VERSION "created by canmatrix"

NS_ :

BS_:

BU_: HUT T_BOX GW XBOX_D CEM Tester

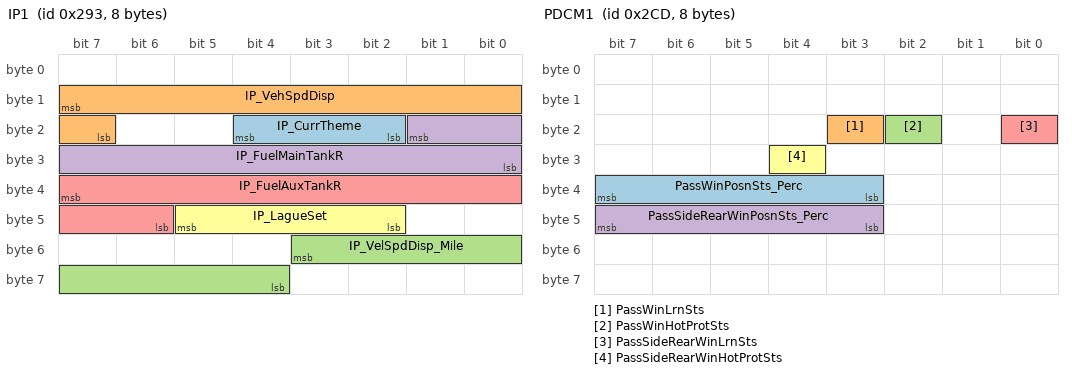
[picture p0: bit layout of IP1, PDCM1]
BO_ 659 IP1: 8 HUT
 SG_ IP_CurrTheme : 20|3@0+ (1,0) [0|7] "" T_BOX
 SG_ IP_VehSpdDisp : 15|9@0+ (0.5,0) [0|255] "kmh" GW
 SG_ IP_VelSpdDisp_Mile : 51|8@0+ (1,0) [0|255] "Mile per hour" GW
 SG_ IP_FuelMainTankR : 17|10@0+ (1,0) [10|1000] "Ohm" GW
 SG_ IP_FuelAuxTankR : 39|10@0+ (1,0) [10|1000] "Ohm" GW
 SG_ IP_LagueSet : 45|4@0+ (1,0) [0|15] "" Vector__XXX

BO_ 639 IP2: 16 HUT
 SG_ CheckSum_IP2 : 7|8@0+ (1,0) [0|255] "" GW
 SG_ IP_DrvSeatBeltWarnLmpFailSts : 51|2@0+ (1,0) [0|3] "" GW
 SG_ IP_PassSeatBeltWarnLmpFailSts : 49|2@0+ (1,0) [0|3] "" GW
 SG_ IP_VehTotDistance : 15|24@0+ (0.1,0) [0|999999.9] "Km" GW,CEM,T_BOX
 SG_ IP_VehTotDistanceValid : 46|1@0+ (1,0) [0|1] "" GW,CEM,T_BOX
 SG_ IP_FuelLvlInfo : 39|8@0+ (1,0) [0|200] "L" GW,T_BOX
 SG_ IP_FuelLvlLowLmpSts : 45|2@0+ (1,0) [0|3] "" T_BOX
 SG_ IP_BattChrgLmpSts : 43|2@0+ (1,0) [0|3] "" Vector__XXX
 SG_ IP_EngOilPressLowLmpSts : 41|2@0+ (1,0) [0|3] "" Vector__XXX
 SG_ IP_ABMWarnLmpFailrSts : 55|2@0+ (1,0) [0|3] "" GW
 SG_ IP_Err : 52|1@0+ (1,0) [0|1] "" GW
 SG_ IP_ACCErr : 47|1@0+ (1,0) [0|1] "" GW
 SG_ IP_VehSpdUnit : 53|1@0+ (1,0) [0|1] "" GW,T_BOX
 SG_ IP_VINcompr : 63|1@0+ (1,0) [0|1] "" GW
 SG_ RollingCounter_IP2 : 59|4@0+ (1,0) [0|15] "" GW
 SG_ FreshnessValue_IP2 : 71|16@0+ (1,0) [0|65535] "" GW,T_BOX
 SG_ MAC_Check_IP2 : 87|48@0+ (1,0) [0|281474976710655] "" GW,T_BOX

BO_ 842 IP3: 16 HUT
 SG_ IP_RemainDistance : 15|12@0+ (1,0) [0|2000] "km" T_BOX
 SG_ IP_InstFuelConsUnit : 19|1@0+ (1,0) [0|1] "" Vector__XXX
 SG_ IP_EBDFailSts : 18|1@0+ (1,0) [0|1] "" Vector__XXX
 SG_ IP_AvgFuelCons : 31|12@0+ (0.01,0) [0|29.99] "L100km" T_BOX
 SG_ IP_InstFuelCons : 35|14@0+ (0.01,0) [0|99.99] "L100km" T_BOX

BO_ 717 PDCM1: 8 GW
 SG_ PassWinPosnSts_Perc : 39|5@0+ (1,0) [0|31] "" HUT,T_BOX
 SG_ PassWinLrnSts : 19|1@0+ (1,0) [0|1] "" HUT,T_BOX
 SG_ PassWinHotProtSts : 18|1@0+ (1,0) [0|1] "" HUT,T_BOX
 SG_ PassSideRearWinPosnSts_Perc : 47|5@0+ (1,0) [0|31] "" HUT,T_BOX
 SG_ PassSideRearWinLrnSts : 16|1@0+ (1,0) [0|1] "" HUT,T_BOX
 SG_ PassSideRearWinHotProtSts : 28|1@0+ (1,0) [0|1] "" HUT,T_BOX

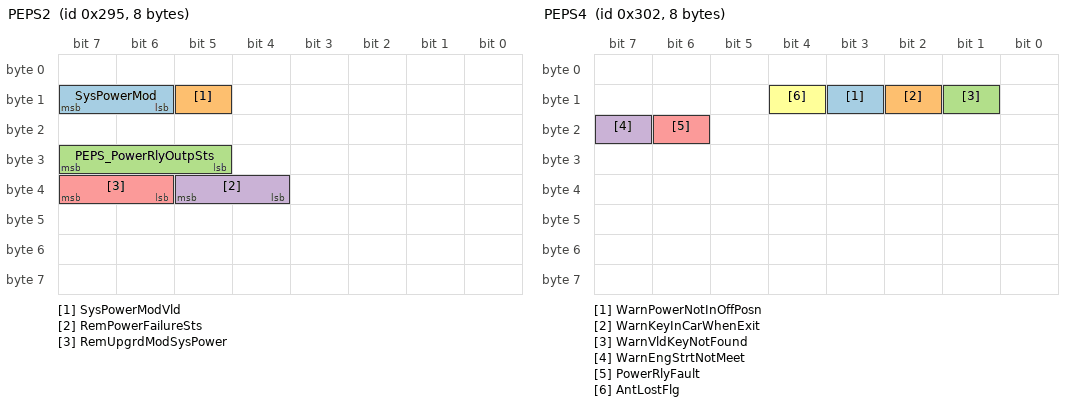
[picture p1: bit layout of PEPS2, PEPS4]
BO_ 661 PEPS2: 8 CEM
 SG_ SysPowerMod : 15|2@0+ (1,0) [0|3] "" HUT,XBOX_D,T_BOX
 SG_ SysPowerModVld : 13|1@0+ (1,0) [0|1] "" HUT,XBOX_D,T_BOX
 SG_ PEPS_PowerRlyOutpSts : 31|3@0+ (1,0) [0|7] "" HUT
 SG_ RemPowerFailureSts : 37|2@0+ (1,0) [0|3] "" HUT,T_BOX
 SG_ RemUpgrdModSysPower : 39|2@0+ (1,0) [0|3] "" HUT,T_BOX

BO_ 770 PEPS4: 8 CEM
 SG_ WarnPowerNotInOffPosn : 11|1@0+ (1,0) [0|1] "" HUT
 SG_ WarnKeyInCarWhenExit : 10|1@0+ (1,0) [0|1] "" HUT
 SG_ WarnVldKeyNotFound : 9|1@0+ (1,0) [0|1] "" HUT
 SG_ WarnEngStrtNotMeet : 23|1@0+ (1,0) [0|1] "" HUT
 SG_ PowerRlyFault : 22|1@0+ (1,0) [0|1] "" HUT
 SG_ AntLostFlg : 12|1@0+ (1,0) [0|1] "" HUT

BO_ 412 R_PBOX1: 16 GW
 SG_ HiPosnBrkLmpFailSts : 15|1@0+ (1,0) [0|1] "" HUT,T_BOX
 SG_ LBrkLmpFailSts : 13|1@0+ (1,0) [0|1] "" HUT,T_BOX
 SG_ RFogLmpFailSts_R_PBox : 29|1@0+ (1,0) [0|1] "" HUT,T_BOX
 SG_ RFogLmpSts_R_PBox : 28|1@0+ (1,0) [0|1] "" HUT,T_BOX
 SG_ ParkLmpSts_R_PBox : 26|1@0+ (1,0) [0|1] "" HUT,T_BOX
 SG_ RBrkLmpFailSts : 12|1@0+ (1,0) [0|1] "" HUT,T_BOX
 SG_ PosnLmpOutpSts_R_PBox : 11|1@0+ (1,0) [0|1] "" HUT,T_BOX
 SG_ RRPosnLmpFailSts : 10|1@0+ (1,0) [0|1] "" HUT,T_BOX
 SG_ RvsLmpFailSts : 9|1@0+ (1,0) [0|1] "" HUT,T_BOX
 SG_ LRPosnLmpFailSts : 8|1@0+ (1,0) [0|1] "" HUT,T_BOX
 SG_ LTurnLmpSts_R_PBox : 31|1@0+ (1,0) [0|1] "" HUT,T_BOX
 SG_ RTurnLmpSts_R_PBox : 30|1@0+ (1,0) [0|1] "" HUT,T_BOX
 SG_ RWinHeatgIconRlyCmd : 21|1@0+ (1,0) [0|1] "" HUT,T_BOX
 SG_ RWinHeatgFailSts : 20|1@0+ (1,0) [0|1] "" HUT
 SG_ LicPlateLmpFailSts : 14|1@0+ (1,0) [0|1] "" HUT,T_BOX
 SG_ RTurnLmpFailSts : 19|2@0+ (1,0) [0|3] "" HUT,T_BOX
 SG_ LTurnLmpFailSts : 17|2@0+ (1,0) [0|3] "" HUT,T_BOX
 SG_ LBrkLmpOutpSts_R_PBox : 38|1@0+ (1,0) [0|1] "" HUT
 SG_ RBrkLmpOutpSts_R_PBox : 24|1@0+ (1,0) [0|1] "" HUT
 SG_ HiPosnBrkLmpOutpSts_R_PBox : 39|1@0+ (1,0) [0|1] "" HUT
 SG_ FreshnessValue_R_PBox1 : 71|16@0+ (1,0) [0|65535] "" HUT,T_BOX
 SG_ MAC_Check_R_PBox1 : 87|48@0+ (1,0) [0|281474976710655] "" HUT,T_BOX

BO_ 367 RSDS_FD1: 64 GW
 SG_ RSDS_IPSoundReq : 81|2@0+ (1,0) [0|3] "" HUT
 SG_ RSDS_ErrSts : 119|1@0+ (1,0) [0|1] "" HUT
 SG_ RSDS_BrkgTrig : 118|1@0+ (1,0) [0|1] "" HUT
 SG_ RSDS_BliSts : 117|1@0+ (1,0) [0|1] "" HUT
 SG_ RSDS_TrailerSts : 116|1@0+ (1,0) [0|1] "" HUT
 SG_ RSDS_LCAResp : 115|1@0+ (1,0) [0|1] "" HUT
 SG_ RSDS_DOWResp : 114|1@0+ (1,0) [0|1] "" HUT
 SG_ RSDS_RCWResp : 113|1@0+ (1,0) [0|1] "" HUT
 SG_ RSDS_RCTAResp : 112|1@0+ (1,0) [0|1] "" HUT
 SG_ RSDS_RCTABrkResp : 127|1@0+ (1,0) [0|1] "" HUT
 SG_ RSDS_RCW_Trigger : 105|2@0+ (1,0) [0|3] "" HUT
 SG_ RSDS_CTA_Actv : 126|1@0+ (1,0) [0|1] "" HUT
 SG_ BSD_LCA_warningReqRight : 95|2@0+ (1,0) [0|3] "" HUT
 SG_ BSD_LCA_warningReqleft : 93|2@0+ (1,0) [0|3] "" HUT
 SG_ DOW_warningReqRight : 91|2@0+ (1,0) [0|3] "" HUT
 SG_ DOW_warningReqleft : 89|2@0+ (1,0) [0|3] "" HUT
 SG_ RCTA_warningReqRight : 125|1@0+ (1,0) [0|1] "" HUT
 SG_ RCTA_warningReqLeft : 124|1@0+ (1,0) [0|1] "" HUT

BO_ 778 RSDS_FD2: 64 GW
 SG_ RCTA_B_TTC : 15|6@0+ (0.1,0) [0|6.3] "s" HUT
 SG_ BSD_LCA_Left_TTC : 9|6@0+ (0.1,0) [0|6.3] "s" HUT
 SG_ BSD_LCA_Right_TTC : 19|6@0+ (0.1,0) [0|6.3] "s" HUT
 SG_ RCW_TTC : 29|6@0+ (0.1,0) [0|6.3] "s" HUT
 SG_ RSDS_LeTgt_01 : 79|1@0+ (1,0) [0|1] "" HUT
 SG_ RSDS_LeTgt_01_dx : 87|10@0+ (0.1,-90) [-90|5] "m" HUT
 SG_ RSDS_LeTgt_01_dy : 78|7@0+ (0.1,0) [0|8] "m" HUT
 SG_ RSDS_LeTgt_02 : 93|1@0+ (1,0) [0|1] "" HUT
 SG_ RSDS_LeTgt_02_dx : 92|10@0+ (0.1,-90) [-90|5] "m" HUT
 SG_ RSDS_LeTgt_02_dy : 98|7@0+ (0.1,0) [0|8] "m" HUT
 SG_ RSDS_RiTgt_01 : 107|1@0+ (1,0) [0|1] "" HUT
 SG_ RSDS_RiTgt_01_dx : 106|10@0+ (0.1,-90) [-90|5] "m" HUT
 SG_ RSDS_RiTgt_01_dy : 143|7@0+ (0.1,-8) [-8|0] "m" HUT
 SG_ RSDS_RiTgt_02 : 136|1@0+ (1,0) [0|1] "" HUT
 SG_ RSDS_RiTgt_02_dx : 151|10@0+ (0.1,-90) [-90|5] "m" HUT
 SG_ RSDS_RiTgt_02_dy : 157|7@0+ (0.1,-8) [-8|0] "m" HUT
 SG_ RSDS_MidTgt_01 : 166|1@0+ (1,0) [0|1] "" HUT
 SG_ RSDS_MidTgt_01_dx : 165|10@0+ (0.1,-90) [-90|5] "m" HUT
 SG_ RSDS_MidTgt_01_dy : 171|7@0+ (0.1,-4) [-4|4] "m" HUT
 SG_ RSDS_MidTgt_02 : 180|1@0+ (1,0) [0|1] "" HUT
 SG_ RSDS_MidTgt_02_dx : 207|10@0+ (0.1,-90) [-90|5] "m" HUT
 SG_ RSDS_MidTgt_02_dy : 213|7@0+ (0.1,-4) [-4|4] "m" HUT

BO_ 51 T_BOX_FD1: 16 T_BOX
 SG_ T_BOX_RemtDoorLockCtrl : 7|3@0+ (1,0) [0|7] "" CEM,HUT
 SG_ T_BOX_AudioMuteReq : 9|2@0+ (1,0) [0|3] "" HUT
 SG_ T_BOX_PM25AirQLvl : 43|4@0+ (1,0) [0|15] "" HUT
 SG_ T_BOX_PM25Dens : 49|10@0+ (1,0) [0|1023] "ugm^3" HUT
 SG_ FreshnessValue_T_BOX_FD1 : 71|16@0+ (1,0) [0|65535] "" GW,HUT
 SG_ MAC_Check_T_BOX_FD1 : 87|48@0+ (1,0) [0|281474976710655] "" GW,HUT

BO_ 1001 T_BOX_FD3: 16 T_BOX
 SG_ T_BOX_SysErrSts : 7|5@0+ (1,0) [0|31] "" GW,HUT
 SG_ T_BOX_SWUpdSts : 18|3@0+ (1,0) [0|7] "" HUT
 SG_ FreshnessValue_T_BOX_FD3 : 71|16@0+ (1,0) [0|65535] "" GW,HUT
 SG_ MAC_Check_T_BOX_FD3 : 87|48@0+ (1,0) [0|281474976710655] "" GW,HUT

BO_ 481 T_BOX_FD4: 16 T_BOX
 SG_ T_BOX_RemtVideoMonrEnaReq_APP : 41|2@0+ (1,0) [0|3] "" HUT

BO_ 752 T_BOX_FD10: 64 T_BOX
 SG_ V2X_FCW : 15|2@0+ (1,0) [0|3] "" HUT
 SG_ V2X_BSW : 13|4@0+ (1,0) [0|15] "" HUT
 SG_ V2X_LCW : 9|2@0+ (1,0) [0|3] "" HUT
 SG_ V2X_EBW : 23|2@0+ (1,0) [0|3] "" HUT
 SG_ V2X_ICW : 21|4@0+ (1,0) [0|15] "" HUT
 SG_ V2X_LTA : 17|2@0+ (1,0) [0|3] "" HUT
 SG_ V2X_IVSW : 31|8@0+ (1,0) [0|255] "" HUT
 SG_ V2X_AVW : 39|3@0+ (1,0) [0|7] "" HUT
 SG_ V2X_EVW : 36|3@0+ (1,0) [0|7] "" HUT
 SG_ V2X_DNPW : 33|2@0+ (1,0) [0|3] "" HUT
 SG_ V2X_HLW : 47|5@0+ (1,0) [0|31] "" HUT
 SG_ V2X_TJW : 42|3@0+ (1,0) [0|7] "" HUT
 SG_ V2X_CLW : 55|6@0+ (1,0) [0|63] "" HUT
 SG_ V2X_RLVW : 49|2@0+ (1,0) [0|3] "" HUT
 SG_ V2X_VRUCW : 63|4@0+ (1,0) [0|15] "" HUT
 SG_ V2X_SLW : 79|6@0+ (1,0) [0|63] "" HUT
 SG_ V2X_GLOSA : 87|8@0+ (1,0) [0|255] "" HUT
 SG_ V2X_SL1_LightTyp : 95|4@0+ (1,0) [0|15] "" HUT
 SG_ V2X_SL1_LightColor : 91|4@0+ (1,0) [0|15] "" HUT
 SG_ V2X_SL1_LightTim : 103|16@0+ (1,0) [0|65535] "s" HUT
 SG_ V2X_SL2_LightTyp : 119|4@0+ (1,0) [0|15] "" HUT
 SG_ V2X_SL2_LightColor : 115|4@0+ (1,0) [0|15] "" HUT
 SG_ V2X_SL2_LightTim : 143|16@0+ (1,0) [0|65535] "s" HUT
 SG_ V2X_SL3_LightTyp : 159|4@0+ (1,0) [0|15] "" HUT
 SG_ V2X_SL3_LightColor : 155|4@0+ (1,0) [0|15] "" HUT
 SG_ V2X_SL3_LightTim : 167|16@0+ (1,0) [0|65535] "s" HUT
 SG_ V2X_SL4_LightTyp : 183|4@0+ (1,0) [0|15] "" HUT
 SG_ V2X_SL4_LightColor : 179|4@0+ (1,0) [0|15] "" HUT
 SG_ V2X_SL5_LightTyp : 191|4@0+ (1,0) [0|15] "" HUT
 SG_ V2X_SL4_LightTim : 207|16@0+ (1,0) [0|65535] "s" HUT
 SG_ V2X_SL5_LightColor : 223|4@0+ (1,0) [0|15] "" HUT
 SG_ V2X_SL5_LightTim : 231|16@0+ (1,0) [0|65535] "s" HUT
 SG_ V2X_SL6_LightTyp : 219|4@0+ (1,0) [0|15] "" HUT
 SG_ V2X_SL6_LightColor : 247|4@0+ (1,0) [0|15] "" HUT
 SG_ V2X_SL6_LightTim : 271|16@0+ (1,0) [0|65535] "s" HUT
 SG_ V2X_SL7_LightTyp : 243|4@0+ (1,0) [0|15] "" HUT
 SG_ V2X_SL7_LightColor : 255|4@0+ (1,0) [0|15] "" HUT
 SG_ V2X_SL7_LightTim : 287|16@0+ (1,0) [0|65535] "s" HUT
 SG_ V2X_SL8_LightTyp : 303|4@0+ (1,0) [0|15] "" HUT
 SG_ V2X_SL8_LightColor : 299|4@0+ (1,0) [0|15] "" HUT
 SG_ V2X_SL8_LightTim : 335|16@0+ (1,0) [0|65535] "s" HUT
 SG_ V2X_SL_of_Veh : 311|4@0+ (1,0) [0|15] "" HUT

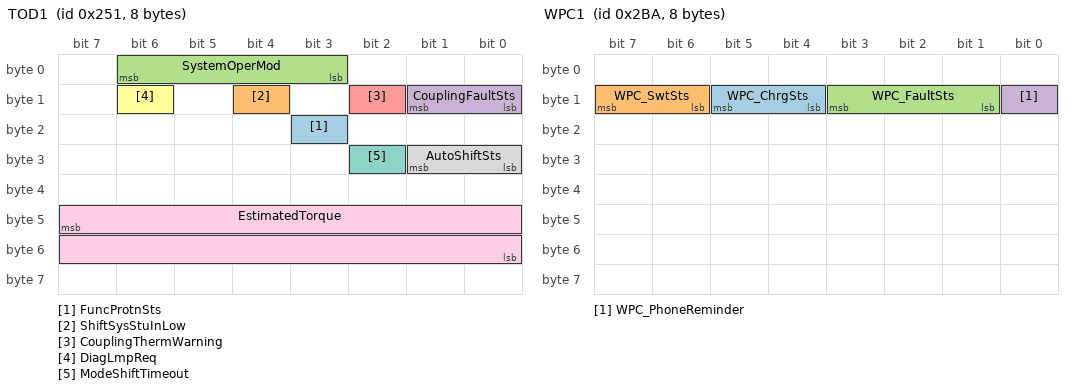
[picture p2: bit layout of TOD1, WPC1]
BO_ 593 TOD1: 8 GW
 SG_ FuncProtnSts : 19|1@0+ (1,0) [0|1] "" HUT
 SG_ ShiftSysStuInLow : 12|1@0+ (1,0) [0|1] "" HUT
 SG_ SystemOperMod : 6|4@0+ (1,0) [0|15] "" HUT,T_BOX
 SG_ CouplingFaultSts : 9|2@0+ (1,0) [0|3] "" HUT
 SG_ CouplingThermWarning : 10|1@0+ (1,0) [0|1] "" HUT,T_BOX
 SG_ DiagLmpReq : 14|1@0+ (1,0) [0|1] "" HUT,T_BOX
 SG_ ModeShiftTimeout : 26|1@0+ (1,0) [0|1] "" HUT
 SG_ AutoShiftSts : 25|2@0+ (1,0) [0|3] "" HUT
 SG_ EstimatedTorque : 47|16@0+ (0.25,0) [0|3000] "Nm" HUT

BO_ 833 TPMS1: 16 GW
 SG_ FLTirePressIndSts : 15|3@0+ (1,0) [0|7] "" HUT,T_BOX
 SG_ FRTirePressIndSts : 12|3@0+ (1,0) [0|7] "" HUT,T_BOX
 SG_ TirePressSysFailrIndcn : 9|2@0+ (1,0) [0|3] "" HUT,T_BOX
 SG_ RLTirePressIndSts : 23|3@0+ (1,0) [0|7] "" HUT,T_BOX
 SG_ RRTirePressIndSts : 20|3@0+ (1,0) [0|7] "" HUT,T_BOX
 SG_ FLTireTempSts : 31|2@0+ (1,0) [0|3] "" HUT,T_BOX
 SG_ FRTireTempSts : 29|2@0+ (1,0) [0|3] "" HUT,T_BOX
 SG_ RLTireTempSts : 27|2@0+ (1,0) [0|3] "" HUT,T_BOX
 SG_ RRTireTempSts : 25|2@0+ (1,0) [0|3] "" HUT,T_BOX
 SG_ FreshnessValue_TPMS1 : 71|16@0+ (1,0) [0|65535] "" HUT,T_BOX
 SG_ MAC_Check_TPMS1 : 87|48@0+ (1,0) [0|281474976710655] "" HUT,T_BOX

BO_ 917 TPMS2: 16 GW
 SG_ FLTirePress : 7|8@0+ (1.3725,0) [0|348.615] "kPa" HUT,T_BOX
 SG_ FLTireTemp : 15|8@0+ (1,-50) [-50|204] "Ã‚Â°C" HUT,T_BOX
 SG_ FRTirePress : 23|8@0+ (1.3725,0) [0|348.615] "kPa" HUT,T_BOX
 SG_ FRTireTemp : 31|8@0+ (1,-50) [-50|204] "Ã‚Â°C" HUT,T_BOX
 SG_ RLTirePress : 39|8@0+ (1.3725,0) [0|348.615] "kPa" HUT,T_BOX
 SG_ RLTireTemp : 47|8@0+ (1,-50) [-50|204] "Ã‚Â°C" HUT,T_BOX
 SG_ RRTirePress : 55|8@0+ (1.3725,0) [0|348.615] "kPa" HUT,T_BOX
 SG_ RRTireTemp : 63|8@0+ (1,-50) [-50|204] "Ã‚Â°C" HUT,T_BOX
 SG_ FreshnessValue_TPMS2 : 71|16@0+ (1,0) [0|65535] "" HUT,T_BOX
 SG_ MAC_Check_TPMS2 : 87|48@0+ (1,0) [0|281474976710655] "" HUT,T_BOX

BO_ 627 Trailer1: 8 GW
 SG_ TrailerSts : 7|1@0+ (1,0) [0|1] "" HUT

BO_ 698 WPC1: 8 GW
 SG_ WPC_ChrgSts : 13|2@0+ (1,0) [0|3] "" HUT
 SG_ WPC_SwtSts : 15|2@0+ (1,0) [0|3] "" HUT
 SG_ WPC_FaultSts : 11|3@0+ (1,0) [0|7] "" HUT
 SG_ WPC_PhoneReminder : 8|1@0+ (1,0) [0|1] "" HUT

BO_ 785 DOCK1: 64 XBOX_D
 SG_ DOCK_ExternalDevice_P : 7|512@0+ (1,0) [0|3.40282366920938E+038] "" HUT

BO_ 479 DOCK2: 64 XBOX_D
 SG_ DOCK_HUT_ExternalDevice_E : 7|512@0+ (1,0) [0|3.40282366920938E+038] "" HUT

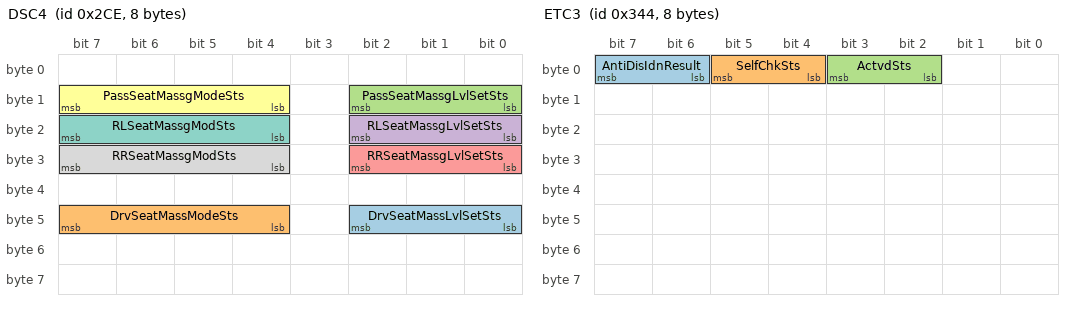
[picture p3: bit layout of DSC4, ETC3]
BO_ 718 DSC4: 8 GW
 SG_ DrvSeatMassLvlSetSts : 42|3@0+ (1,0) [0|7] "" HUT
 SG_ DrvSeatMassModeSts : 47|4@0+ (1,0) [0|15] "" HUT
 SG_ PassSeatMassgLvlSetSts : 10|3@0+ (1,0) [0|7] "" HUT
 SG_ RLSeatMassgLvlSetSts : 18|3@0+ (1,0) [0|7] "" HUT
 SG_ RRSeatMassgLvlSetSts : 26|3@0+ (1,0) [0|7] "" HUT
 SG_ PassSeatMassgModeSts : 15|4@0+ (1,0) [0|15] "" HUT
 SG_ RLSeatMassgModSts : 23|4@0+ (1,0) [0|15] "" HUT
 SG_ RRSeatMassgModSts : 31|4@0+ (1,0) [0|15] "" HUT

BO_ 604 BLE1: 8 GW
 SG_ BLEConnSts : 15|2@0+ (1,0) [0|3] "" HUT
 SG_ BLESecuritySts : 13|2@0+ (1,0) [0|3] "" HUT

BO_ 506 BLE5: 8 GW
 SG_ BLE_BeanID : 7|64@0+ (1,0) [0|1.84467440737096E+019] "" HUT

BO_ 473 GW_OTA: 8 CEM
 SG_ OTA_UpgrdModErrCode : 14|2@0+ (1,0) [0|3] "" HUT

BO_ 721 SCM1: 8 CEM
 SG_ DrvSeatVentnSts : 11|2@0+ (1,0) [0|3] "" HUT
 SG_ PassSeatVentnSts : 9|2@0+ (1,0) [0|3] "" HUT

BO_ 497 ETC2: 8 GW
 SG_ AntiDisIdnRndNumber : 7|64@0+ (1,0) [0|1.84467440737096E+019] "" HUT

BO_ 836 ETC3: 8 GW
 SG_ AntiDisIdnResult : 7|2@0+ (1,0) [0|3] "" HUT
 SG_ SelfChkSts : 5|2@0+ (1,0) [0|3] "" HUT
 SG_ ActvdSts : 3|2@0+ (1,0) [0|3] "" HUT

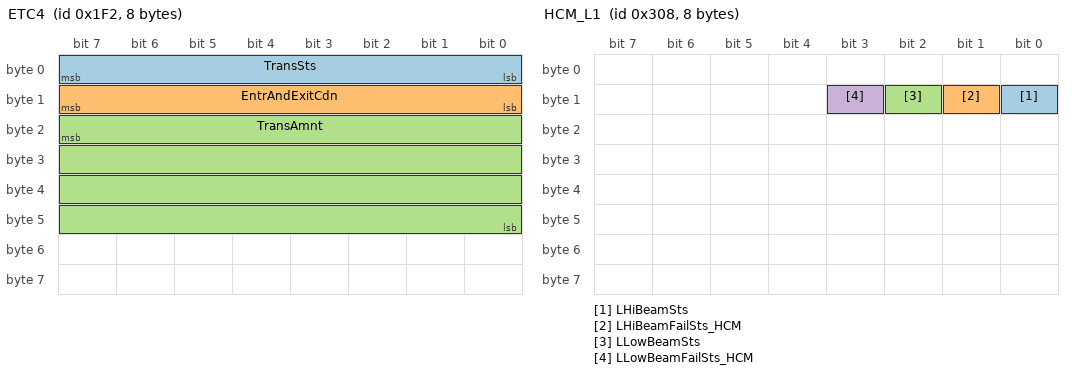
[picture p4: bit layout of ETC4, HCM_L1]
BO_ 498 ETC4: 8 GW
 SG_ TransSts : 7|8@0+ (1,0) [0|255] "" HUT
 SG_ EntrAndExitCdn : 15|8@0+ (1,0) [0|255] "" HUT
 SG_ TransAmnt : 23|32@0+ (1,0) [0|4294967295] "cent" HUT

BO_ 776 HCM_L1: 8 GW
 SG_ LHiBeamSts : 8|1@0+ (1,0) [0|1] "" HUT
 SG_ LHiBeamFailSts_HCM : 9|1@0+ (1,0) [0|1] "" HUT
 SG_ LLowBeamSts : 10|1@0+ (1,0) [0|1] "" HUT
 SG_ LLowBeamFailSts_HCM : 11|1@0+ (1,0) [0|1] "" HUT

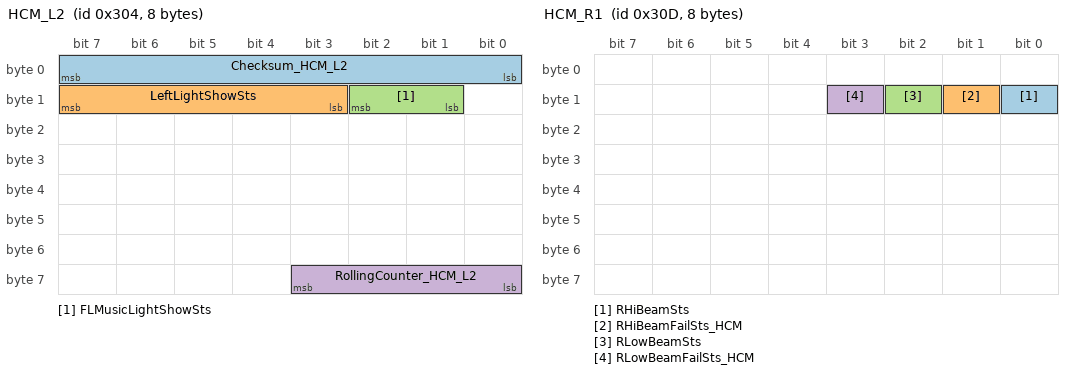
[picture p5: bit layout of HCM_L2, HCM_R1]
BO_ 772 HCM_L2: 8 GW
 SG_ Checksum_HCM_L2 : 7|8@0+ (1,0) [0|255] "" HUT,T_BOX
 SG_ LeftLightShowSts : 15|5@0+ (1,0) [0|31] "" HUT
 SG_ FLMusicLightShowSts : 10|2@0+ (1,0) [0|3] "" HUT,T_BOX
 SG_ RollingCounter_HCM_L2 : 59|4@0+ (1,0) [0|15] "" HUT,T_BOX

BO_ 781 HCM_R1: 8 GW
 SG_ RHiBeamSts : 8|1@0+ (1,0) [0|1] "" HUT
 SG_ RHiBeamFailSts_HCM : 9|1@0+ (1,0) [0|1] "" HUT
 SG_ RLowBeamSts : 10|1@0+ (1,0) [0|1] "" HUT
 SG_ RLowBeamFailSts_HCM : 11|1@0+ (1,0) [0|1] "" HUT

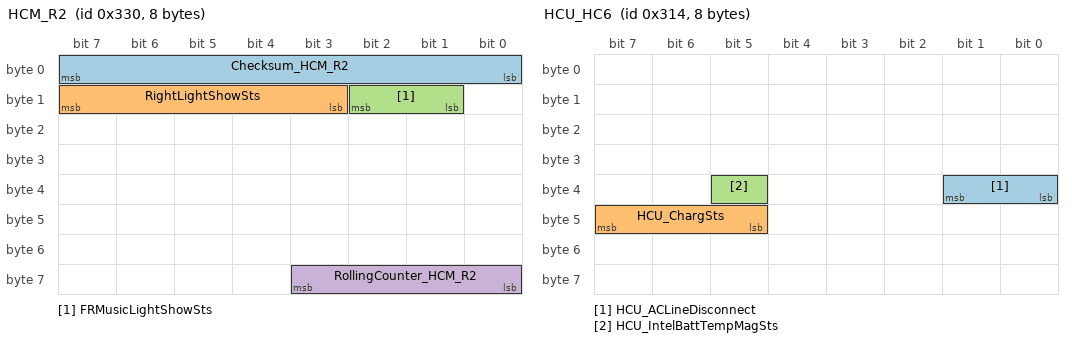
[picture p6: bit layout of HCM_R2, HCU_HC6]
BO_ 816 HCM_R2: 8 GW
 SG_ Checksum_HCM_R2 : 7|8@0+ (1,0) [0|255] "" HUT,T_BOX
 SG_ RightLightShowSts : 15|5@0+ (1,0) [0|31] "" HUT
 SG_ FRMusicLightShowSts : 10|2@0+ (1,0) [0|3] "" HUT,T_BOX
 SG_ RollingCounter_HCM_R2 : 59|4@0+ (1,0) [0|15] "" HUT,T_BOX

BO_ 647 ALS1: 16 GW
 SG_ CheckSum_HC1 : 7|8@0+ (1,0) [0|255] "" HUT
 SG_ ALS_FailSts : 8|1@0+ (1,0) [0|1] "" HUT
 SG_ RollingCounter_HC1 : 59|4@0+ (1,0) [0|15] "" HUT

BO_ 818 RFCM_L1: 8 GW
 SG_ RFLLightShowSts : 23|5@0+ (1,0) [0|31] "" HUT,T_BOX

BO_ 819 RFCM_R1: 8 GW
 SG_ RFRLightShowSts : 23|5@0+ (1,0) [0|31] "" HUT,T_BOX

BO_ 1888 DiagFuncReq: 8 Tester
 SG_ DiagFuncReq : 7|64@0+ (1,0) [0|1.84467440737096E+019] "" GW,CEM,T_BOX,XBOX_D,HUT

BO_ 1889 GW_Phy_Req: 8 Tester
 SG_ GW_Phy_Req : 7|64@0+ (1,0) [0|1.84467440737096E+019] "" GW

BO_ 1918 T_Box_Phy_Req: 8 Tester
 SG_ T_Box_Phy_Req : 7|64@0+ (1,0) [0|1.84467440737096E+019] "" GW,T_BOX

BO_ 1843 XBOX_D_Phy_Req: 8 Tester
 SG_ XBOX_D_Phy_Req : 7|64@0+ (1,0) [0|1.84467440737096E+019] "" GW,XBOX_D

BO_ 1907 HUT_Phy_Req: 8 Tester
 SG_ HUT_Phy_Req : 7|64@0+ (1,0) [0|1.84467440737096E+019] "" GW,HUT

BO_ 1953 GW_Phy_Resp: 8 GW
 SG_ GW_Phy_Resp : 7|64@0+ (1,0) [0|1.84467440737096E+019] "" Tester

BO_ 1982 T_Box_Phy_Resp: 8 T_BOX
 SG_ T_Box_Phy_Resp : 7|64@0+ (1,0) [0|1.84467440737096E+019] "" GW,Tester

BO_ 1844 XBOX_D_Phy_Resp: 8 XBOX_D
 SG_ XBOX_D_Phy_Resp : 7|64@0+ (1,0) [0|1.84467440737096E+019] "" GW,Tester

BO_ 1971 HUT_Phy_Resp: 8 HUT
 SG_ HUT_Phy_Resp : 7|64@0+ (1,0) [0|1.84467440737096E+019] "" GW,Tester

BO_ 1290 T_Box_NM: 8 T_BOX
 SG_ Destination_T_Box_NM : 7|8@0+ (1,0) [0|255] "" CEM,XBOX_D,HUT
 SG_ OpCode_T_Box_NM : 15|8@0+ (1,0) [0|255] "" CEM,XBOX_D,HUT

BO_ 1289 HUT_NM: 8 HUT
 SG_ Destination_HUT_NM : 7|8@0+ (1,0) [0|255] "" CEM,T_BOX,XBOX_D
 SG_ OpCode_HUT_NM : 15|8@0+ (1,0) [0|255] "" CEM,T_BOX,XBOX_D

BO_ 1334 XBOX_D_NM: 8 XBOX_D
 SG_ Destination_XBOX_D_NM : 7|8@0+ (1,0) [0|255] "" CEM,T_BOX,HUT
 SG_ OpCode_XBOX_D_NM : 15|8@0+ (1,0) [0|255] "" CEM,T_BOX,HUT

BO_ 1281 CEM_NM: 8 CEM
 SG_ Destination_CEM_NM : 7|8@0+ (1,0) [0|255] "" T_BOX,XBOX_D,HUT
 SG_ OpCode_CEM_NM : 15|8@0+ (1,0) [0|255] "" T_BOX,XBOX_D,HUT

BO_ 1122 HUT_Sync_Req: 16 HUT
 SG_ SyncRequestMessageId : 7|8@0+ (1,0) [0|0] "" GW
 SG_ SyncRequstReseverData : 15|56@0+ (1,0) [0|0] "" GW

BO_ 1121 GW_Sync_Req: 16 GW
 SG_ ResetCount : 31|16@0+ (1,0) [0|0] "" HUT
 SG_ CMACMessageInfo : 47|88@0+ (1,0) [0|0] "" HUT
 SG_ TripCount : 7|24@0+ (1,0) [0|0] "" HUT

BO_ 483 BMS_FD14: 8 GW
 SG_ BMS_ChrgTimResp : 9|1@0+ (1,0) [0|1] "" HUT

BO_ 850 BMS19: 8 GW
 SG_ BMS_IntelEngIdlChrgnSts : 45|2@0+ (1,0) [0|3] "" HUT
 SG_ BMS_BattKeepTempSts : 18|1@0+ (1,0) [0|1] "" HUT

BO_ 959 BMS22: 8 GW
 SG_ BMS_ChrgDurationTime : 47|10@0+ (1,0) [0|1022] "minute" HUT,T_BOX

BO_ 1009 BMS30: 8 GW
 SG_ BMS_SOCLowWarn : 31|1@0+ (1,0) [0|1] "" HUT

BO_ 942 BMS66: 8 GW
 SG_ BMS_SocJumpWarn_RM : 7|1@0+ (1,0) [0|1] "" HUT,T_BOX
 SG_ BMS_PackOverChrgWarn_RM : 6|1@0+ (1,0) [0|1] "" HUT,T_BOX
 SG_ BMS_ChrgSts_RM : 5|3@0+ (1,0) [0|7] "" HUT,T_BOX
 SG_ BMS_IsolationRValue_RM : 15|16@0+ (1,0) [0|60000] "Kohm" HUT,T_BOX
 SG_ BMS_PackCurr_RM : 31|15@0+ (0.1,-1000) [-1000|1000] "A" HUT,T_BOX
 SG_ BMS_SocOverWarn_RM : 32|1@0+ (1,0) [0|1] "" HUT,T_BOX
 SG_ BMS_BattOverTempRank_RM : 47|1@0+ (1,0) [0|1] "" HUT,T_BOX
 SG_ BMS_BattOverVoltRank_RM : 46|1@0+ (1,0) [0|1] "" HUT,T_BOX
 SG_ BMS_BattSOCLowRank_RM : 45|1@0+ (1,0) [0|1] "" HUT,T_BOX
 SG_ BMS_VCUIsolateErr_RM : 44|1@0+ (1,0) [0|1] "" HUT,T_BOX
 SG_ BMS_BattUnderVoltRank_RM : 43|1@0+ (1,0) [0|1] "" HUT,T_BOX
 SG_ BMS_CellDeltaVoltRank_RM : 42|1@0+ (1,0) [0|1] "" HUT,T_BOX
 SG_ BMS_CellOverVoltRank_RM : 41|1@0+ (1,0) [0|1] "" HUT,T_BOX
 SG_ BMS_CellUnderVoltRank_RM : 40|1@0+ (1,0) [0|1] "" HUT,T_BOX
 SG_ BMS_DeltaTempRank_RM : 55|1@0+ (1,0) [0|1] "" HUT,T_BOX
 SG_ BMS_PackMismatchWarn_RM : 54|1@0+ (1,0) [0|1] "" HUT,T_BOX
 SG_ BMS_PackVolt_RM : 53|14@0+ (0.1,0) [0|1000] "V" HUT,T_BOX

BO_ 645 BMS8: 8 GW
 SG_ BMS_BattHeatRunaway : 61|2@0+ (1,0) [0|3] "" HUT,T_BOX
 SG_ BMS_DisSOC1 : 31|8@0+ (1,0) [0|100] "%" HUT,T_BOX

BO_ 142 ECM_PT5: 8 GW
 SG_ EngTrqCrankshaftLvl : 27|12@0+ (0.25,-224) [-224|799.75] "Nm" HUT
 SG_ EngTrqCrankshaftLvlValid : 61|1@0+ (1,0) [0|1] "" HUT

BO_ 279 ECM_PT7: 8 GW
 SG_ EngState_PHEV : 31|3@0+ (1,0) [0|7] "" HUT
 SG_ CruiseCtrlSts_PHEV : 55|4@0+ (1,0) [0|15] "" HUT

BO_ 96 HCU_FD1: 64 GW
 SG_ HCU_AccelPedalPosn_Diag : 79|8@0+ (0.3937,0) [0|100.395] "%" HUT
 SG_ HCU_AccelPedalPosn_DiagValid : 85|1@0+ (1,0) [0|1] "" HUT
 SG_ HCU_PowertrainSts_0x60 : 303|5@0+ (1,0) [0|31] "" HUT,XBOX_D
 SG_ HCU_RaceLaunchSts_0x60 : 319|3@0+ (1,0) [0|7] "" HUT
 SG_ HCU_RaceLaunchAvail_0x60 : 287|2@0+ (1,0) [0|3] "" HUT
 SG_ HCU_AccelPedalPosn : 103|8@0+ (0.3937,0) [0|100.395] "%" HUT
 SG_ HCU_AccelPedalPosnValid : 127|1@0+ (1,0) [0|1] "" HUT

BO_ 616 HCU_HC3: 8 GW
 SG_ HCU_BattLowTempWarn : 51|2@0+ (1,0) [0|3] "" HUT
 SG_ HCU_BattLowTempHeatSts : 49|2@0+ (1,0) [0|3] "" HUT

BO_ 788 HCU_HC6: 8 GW
 SG_ HCU_ACLineDisconnect : 33|2@0+ (1,0) [0|3] "" HUT,T_BOX
 SG_ HCU_ChargSts : 47|3@0+ (1,0) [0|7] "" HUT,T_BOX
 SG_ HCU_IntelBattTempMagSts : 37|1@0+ (1,0) [0|1] "" HUT

BO_ 482 HCU_HC8: 8 GW
 SG_ HCU_TotalScore : 23|3@0+ (1,0) [0|5] "" HUT

BO_ 249 HCU_HP8: 8 GW
 SG_ HCU_TrqLimMax_Norm : 16|9@0+ (2,0) [0|800] "Nm" HUT

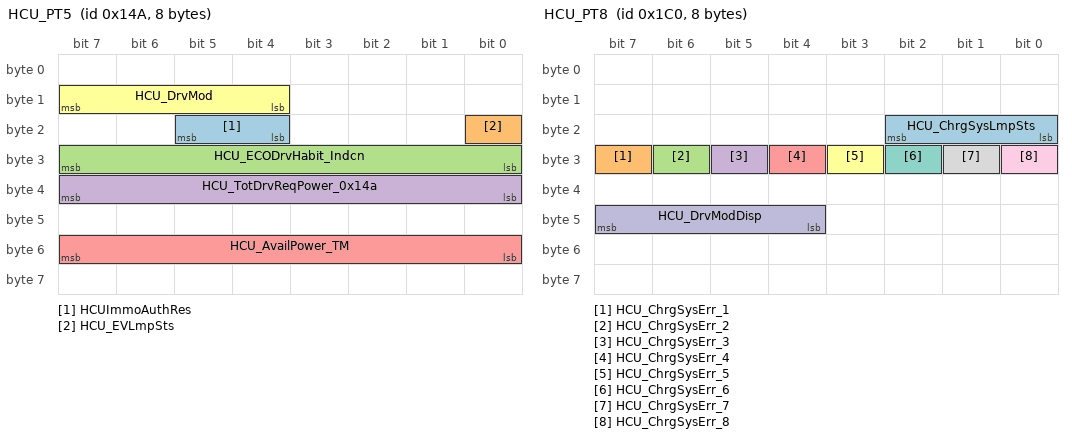
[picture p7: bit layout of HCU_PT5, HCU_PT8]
BO_ 330 HCU_PT5: 8 GW
 SG_ HCUImmoAuthRes : 21|2@0+ (1,0) [0|3] "" HUT
 SG_ HCU_EVLmpSts : 16|1@0+ (1,0) [0|1] "" HUT
 SG_ HCU_ECODrvHabit_Indcn : 31|8@0+ (0.1,-10) [-10|10] "" HUT
 SG_ HCU_TotDrvReqPower_0x14a : 39|8@0+ (1,-100) [-100|100] "%" HUT
 SG_ HCU_AvailPower_TM : 55|8@0+ (0.5,0) [0|100] "%" HUT
 SG_ HCU_DrvMod : 15|4@0+ (1,0) [0|15] "" HUT

BO_ 282 HCU_HP6: 8 GW
 SG_ HCU_HybMod : 28|2@0+ (1,0) [0|3] "" HUT
 SG_ HCU_HybFctnMod : 26|2@0+ (1,0) [0|3] "" HUT

BO_ 448 HCU_PT8: 8 GW
 SG_ HCU_ChrgSysLmpSts : 18|3@0+ (1,0) [0|7] "" HUT
 SG_ HCU_ChrgSysErr_1 : 31|1@0+ (1,0) [0|1] "" HUT
 SG_ HCU_ChrgSysErr_2 : 30|1@0+ (1,0) [0|1] "" HUT
 SG_ HCU_ChrgSysErr_3 : 29|1@0+ (1,0) [0|1] "" HUT
 SG_ HCU_ChrgSysErr_4 : 28|1@0+ (1,0) [0|1] "" HUT
 SG_ HCU_ChrgSysErr_5 : 27|1@0+ (1,0) [0|1] "" HUT
 SG_ HCU_ChrgSysErr_6 : 26|1@0+ (1,0) [0|1] "" HUT
 SG_ HCU_ChrgSysErr_7 : 25|1@0+ (1,0) [0|1] "" HUT
 SG_ HCU_ChrgSysErr_8 : 24|1@0+ (1,0) [0|1] "" HUT
 SG_ HCU_DrvModDisp : 47|4@0+ (1,0) [0|15] "" HUT

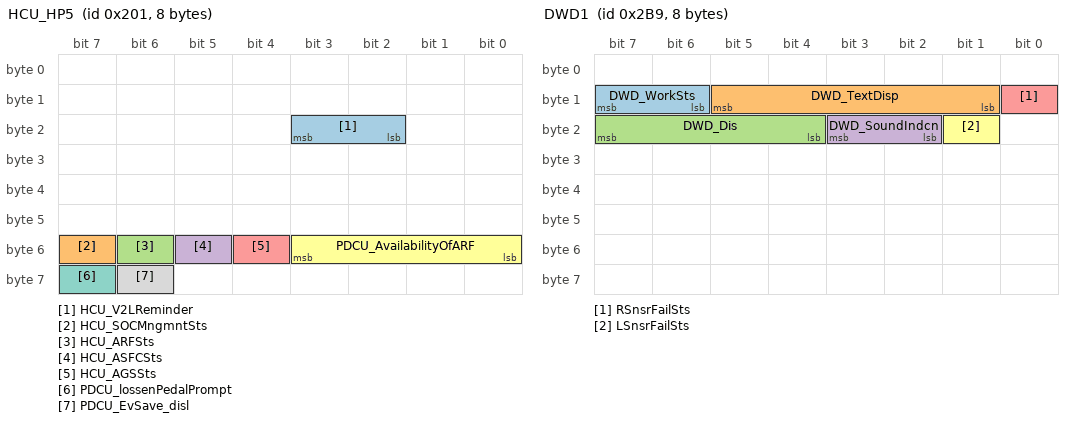
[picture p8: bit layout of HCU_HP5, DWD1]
BO_ 513 HCU_HP5: 8 GW
 SG_ HCU_V2LReminder : 19|2@0+ (1,0) [0|3] "" HUT
 SG_ HCU_SOCMngmntSts : 55|1@0+ (1,0) [0|1] "" HUT
 SG_ HCU_ARFSts : 54|1@0+ (1,0) [0|1] "" HUT
 SG_ HCU_ASFCSts : 53|1@0+ (1,0) [0|1] "" HUT
 SG_ HCU_AGSSts : 52|1@0+ (1,0) [0|1] "" HUT
 SG_ PDCU_AvailabilityOfARF : 51|4@0+ (1,0) [0|5] "" HUT
 SG_ PDCU_lossenPedalPrompt : 63|1@0+ (1,0) [0|1] "" HUT
 SG_ PDCU_EvSave_disl : 62|1@0+ (1,0) [0|1] "" HUT

BO_ 690 HUT27: 8 HUT
 SG_ ExpertModReq_HUT_HCU : 62|2@0+ (1,0) [0|3] "" GW

BO_ 301 EBOOSTER_FD1: 64 GW
 SG_ EB_TgtRcprtnTrqSts : 145|2@0+ (1,0) [0|3] "" HUT

BO_ 172 P2M1: 8 GW
 SG_ P2M_ActTrq : 38|14@0+ (0.1,-819) [-819|819.1] "Nm" HUT

BO_ 190 P2M3: 8 GW
 SG_ P2M_ActSpd : 43|16@0+ (1,-2000) [-2000|10286] "rpm" HUT,T_BOX
 SG_ P2M_ActHvDcVolt : 15|12@0+ (0.25,0) [0|1023.25] "V" HUT

BO_ 510 T_BOX_FD9: 8 T_BOX
 SG_ T_BOX_ChrgTim_Day : 50|5@0+ (1,0) [0|31] "" GW,HUT

BO_ 697 DWD1: 8 GW
 SG_ DWD_WorkSts : 15|2@0+ (1,0) [0|3] "" HUT
 SG_ DWD_TextDisp : 13|5@0+ (1,0) [0|31] "" HUT
 SG_ DWD_Dis : 23|4@0+ (1,0) [0|15] "" HUT
 SG_ DWD_SoundIndcn : 19|2@0+ (1,0) [0|3] "" HUT
 SG_ RSnsrFailSts : 8|1@0+ (1,0) [0|1] "" HUT
 SG_ LSnsrFailSts : 17|1@0+ (1,0) [0|1] "" HUT

BO_ 790 OBC1: 8 GW
 SG_ OBC_ModSts : 19|4@0+ (1,0) [0|15] "" HUT

BO_ 791 OBC2: 8 GW
 SG_ OBC_ConnectSts : 15|2@0+ (1,0) [0|3] "" HUT,T_BOX

BO_ 708 BMS35: 8 GW
 SG_ BMS_BattSOCLimResp : 42|3@0+ (1,0) [0|7] "" HUT

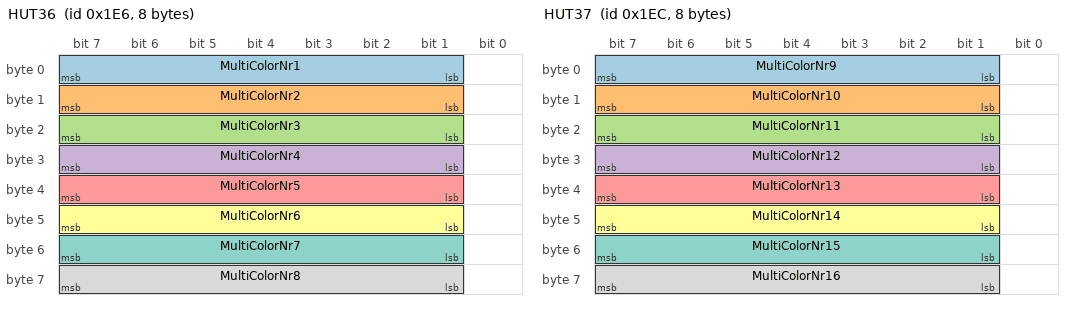
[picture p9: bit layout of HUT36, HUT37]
BO_ 486 HUT36: 8 HUT
 SG_ MultiColorNr1 : 7|7@0+ (1,0) [0|64] "" CEM
 SG_ MultiColorNr2 : 15|7@0+ (1,0) [0|64] "" CEM
 SG_ MultiColorNr3 : 23|7@0+ (1,0) [0|64] "" CEM
 SG_ MultiColorNr4 : 31|7@0+ (1,0) [0|64] "" CEM
 SG_ MultiColorNr5 : 39|7@0+ (1,0) [0|64] "" CEM
 SG_ MultiColorNr6 : 47|7@0+ (1,0) [0|64] "" CEM
 SG_ MultiColorNr7 : 55|7@0+ (1,0) [0|64] "" CEM
 SG_ MultiColorNr8 : 63|7@0+ (1,0) [0|64] "" CEM

BO_ 492 HUT37: 8 HUT
 SG_ MultiColorNr9 : 7|7@0+ (1,0) [0|64] "" CEM
 SG_ MultiColorNr10 : 15|7@0+ (1,0) [0|64] "" CEM
 SG_ MultiColorNr11 : 23|7@0+ (1,0) [0|64] "" CEM
 SG_ MultiColorNr12 : 31|7@0+ (1,0) [0|64] "" CEM
 SG_ MultiColorNr13 : 39|7@0+ (1,0) [0|64] "" CEM
 SG_ MultiColorNr14 : 47|7@0+ (1,0) [0|64] "" CEM
 SG_ MultiColorNr15 : 55|7@0+ (1,0) [0|64] "" CEM
 SG_ MultiColorNr16 : 63|7@0+ (1,0) [0|64] "" CEM

BO_ 130 ECM4: 8 GW
 SG_ NetEngTrq : 15|16@0+ (0.0030518,-100) [-100|99.9966612] "%" HUT
 SG_ DrvEngTrqReq : 31|16@0+ (0.0030518,-100) [-100|99.999713] "%" HUT

BO_ 258 ECM9: 8 GW
 SG_ AccelPedlPosnDiagc : 39|8@0+ (0.3937,0) [0|100.3935] "%" HUT

BO_ 132 ECM7: 8 GW
 SG_ HCU_RaceLaunchAvail_0x84 : 61|2@0+ (1,0) [0|3] "" HUT
 SG_ HCU_RaceLaunchSts_0x84 : 23|3@0+ (1,0) [0|7] "" HUT

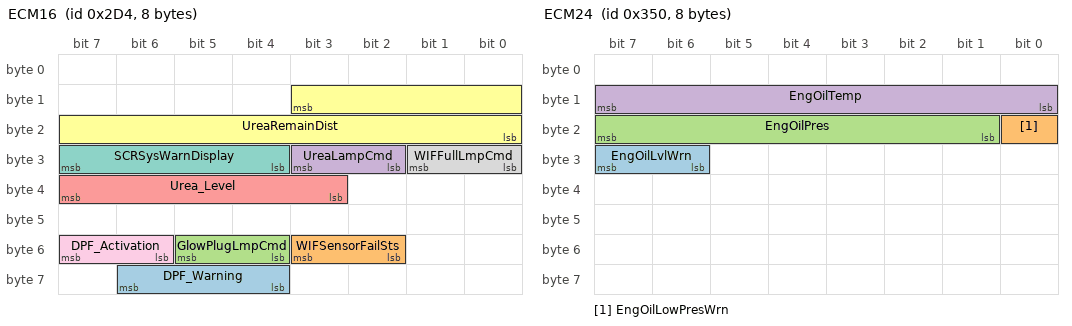
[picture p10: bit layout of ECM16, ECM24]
BO_ 724 ECM16: 8 GW
 SG_ DPF_Warning : 62|3@0+ (1,0) [0|7] "" HUT
 SG_ WIFSensorFailSts : 51|2@0+ (1,0) [0|3] "" HUT
 SG_ GlowPlugLmpCmd : 53|2@0+ (1,0) [0|3] "" HUT
 SG_ UreaLampCmd : 27|2@0+ (1,0) [0|3] "" HUT
 SG_ Urea_Level : 39|5@0+ (5,0) [0|100] "%" HUT
 SG_ UreaRemainDist : 11|12@0+ (1,0) [0|4095] "Km" HUT
 SG_ SCRSysWarnDisplay : 31|4@0+ (1,0) [0|15] "" HUT
 SG_ WIFFullLmpCmd : 25|2@0+ (1,0) [0|3] "" HUT
 SG_ DPF_Activation : 55|2@0+ (1,0) [0|3] "" HUT

BO_ 848 ECM24: 8 GW
 SG_ EngOilLvlWrn : 31|2@0+ (1,0) [0|3] "" HUT
 SG_ EngOilLowPresWrn : 16|1@0+ (1,0) [0|1] "" HUT
 SG_ EngOilPres : 23|7@0+ (0.1,0) [0|12] "Bar" HUT
 SG_ EngOilTemp : 15|8@0+ (1,-40) [-40|160] "Ã¢Â„Âƒ" HUT

BO_ 335 BMS65: 8 GW
 SG_ BMS_BattSOC_P0 : 33|10@0+ (0.1,0) [0|100] "%" HUT

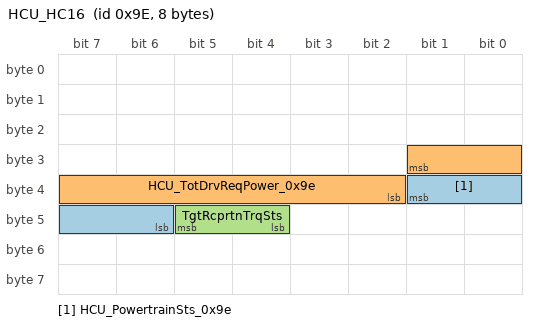
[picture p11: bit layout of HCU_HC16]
BO_ 158 HCU_HC16: 8 GW
 SG_ HCU_PowertrainSts_0x9e : 33|4@0+ (1,0) [0|15] "" HUT
 SG_ HCU_TotDrvReqPower_0x9e : 25|8@0+ (1,-100) [-100|100] "%" HUT
 SG_ TgtRcprtnTrqSts : 45|2@0+ (1,0) [0|3] "" HUT

CM_ SG_ 659 IP_CurrTheme "Indicate the current theme by IP.The coding detailed definition IFCACCording to specific project";
CM_ SG_ 659 IP_VehSpdDisp "The vehilce speed display by IPADAS_CAN:To IFC,IDC_L2";
CM_ SG_ 659 IP_VelSpdDisp_Mile "The vehicle speed display by IP(Mile)ADAS_CAN:To IFC,IDC_L2";
CM_ SG_ 659 IP_FuelMainTankR "IP external main fuel tank resistance valuePT_CAN To:ECM";
CM_ SG_ 659 IP_FuelAuxTankR "IP external auxiliary fuel tank resistance valuePT_CAN To:ECM";
CM_ SG_ 659 IP_LagueSet "Language set";
CM_ SG_ 639 CheckSum_IP2 "Use the checksum strategy from document Ã¢Â€ÂœEnd-to-End Communication Protection SpecificationÃ¢Â€Â";
CM_ SG_ 639 IP_DrvSeatBeltWarnLmpFailSts "Driver Seat Belt  warning lamp failure statusBD2-CAN To:ABM";
CM_ SG_ 639 IP_PassSeatBeltWarnLmpFailSts "Passenger  Seat Belt warning lamp failure statusBD2-CAN To:ABM";
CM_ SG_ 639 IP_VehTotDistance "Vehicle total distanceBD1-CAN To:CSA,ESCL,WPC,AC,BLE
BD2-CAN To:ABM,HUD,AMP,PPMI_D,PPMI_P,SBWM,SVM,ELD,TOD
PT_CAN To:ESP,TCU,Ibooster,EDC,EPS,ECM
ADAS-CANFD To:IFC,RSDS_R,RSDS_L,HAP,PAS,RPAS,CR_L,CR_R,ALS,IDC_L2
HC_CAN:To DCDC,BSG,BMS
BD_Sub_CAN:To DDCM,PDCM,DSC,HVSM,CP,RHVSM";
CM_ SG_ 639 IP_VehTotDistanceValid "Vaild information to current Vehicle travelled total distanceBD1-CAN To:CSA,ESCL,WPC,AC,BLE
BD2-CAN To:HUD,AMP,SBWM,SVM,TOD
PT_CAN To:ESP,TCU,Ibooster,EDC,EPS,ECM
ADAS-CANFD To:IFC,RSDS_R,RSDS_L,HAP,PAS,RPAS,CR_L,CR_R,ALS,IDC_L2
HC_CAN:To DCDC,BSG,BMS
BD_Sub_CAN:To DDCM,PDCM,DSC,HVSM,CP,RHVSM";
CM_ SG_ 639 IP_FuelLvlInfo "Fuel Level Information.PT_CAN:To ECM";
CM_ SG_ 639 IP_FuelLvlLowLmpSts "Fuel Level Low indication lamp ON or OFF status.";
CM_ SG_ 639 IP_BattChrgLmpSts "Indicate Battery charging  lamp ON or OFF status.";
CM_ SG_ 639 IP_EngOilPressLowLmpSts "Engine Oil pressure Low indication lamp status..";
CM_ SG_ 639 IP_ABMWarnLmpFailrSts "Airbag warning lamp failure statusBD2-CAN To:ABM";
CM_ SG_ 639 IP_Err "Error in the IP control unit or the dashboardADAS-CANFD To:IFC,IDC_L2";
CM_ SG_ 639 IP_ACCErr "IP Check ACC error(Checksum,RollingCounter,Missing message)status,if any error were detected by IP will send this signalADAS-CANFD To:IFC,IDC_L2";
CM_ SG_ 639 IP_VehSpdUnit "Indicate the vehicle speed unit used by IP.PT_CAN To:ECM,TCU
ADAS-CANFD To:IFC,IDC_L2";
CM_ SG_ 639 IP_VINcompr "IP compare inner VIN with VIN ECM sendPT_CAN To:ECM";
CM_ SG_ 639 RollingCounter_IP2 "Rolling counter_IP2PT_CAN To:TCU,Ibooster";
CM_ SG_ 639 FreshnessValue_IP2 "ADAS-CANFD To:IDC_L2
PT_CAN:To TCU,EPS";
CM_ SG_ 639 MAC_Check_IP2 "MAC protection mechanism should comply with the GWM MAC SpecificatioADAS-CANFD To:IDC_L2
PT_CAN:To TCU,EPS";
CM_ SG_ 842 IP_RemainDistance "the value was calculated by IPÃ¯Â¼ÂŒwhen Remain Distance<50km,IP will send value \"0xFFF\"display";
CM_ SG_ 842 IP_InstFuelConsUnit "the unit  of instant fuel consumption";
CM_ SG_ 842 IP_EBDFailSts "the Brake System Fault status";
CM_ SG_ 842 IP_AvgFuelCons "the value of average fuel consumption";
CM_ SG_ 842 IP_InstFuelCons "the value  of instant fuel consumption - when the unit is L100kmÃ¯Â¼ÂŒmax value 29.99,when  unit is LhÃ¯Â¼ÂŒmax value 99.99When the vehicle is idling,the unit of this signal is Lh.
When the vehicle is runing,the unit of this signal is Lkm";
CM_ SG_ 717 PassWinPosnSts_Perc "passenger window position status";
CM_ SG_ 717 PassWinLrnSts "passenger window learning status";
CM_ SG_ 717 PassWinHotProtSts "passenger window hot protection status";
CM_ SG_ 717 PassSideRearWinPosnSts_Perc "passenger side rear window position status";
CM_ SG_ 717 PassSideRearWinLrnSts "passenger side rear window learning status";
CM_ SG_ 717 PassSideRearWinHotProtSts "passenger side rear window hot protection status";
CM_ SG_ 661 SysPowerMod "System power modeIP Received";
CM_ SG_ 661 SysPowerModVld "System power mode valid";
CM_ SG_ 661 PEPS_PowerRlyOutpSts "PEPS Power Relay Output status, 3 bits indicate 3 PEPS Power Relay Output Status, 0 means the output enable, 1 means no output. Bit0 for ACC, Bit1 for IGN2, Bit2 For IGN1.
Ã§Â³Â»Ã§Â»ÂŸÃ§Â”ÂµÃ¦ÂºÂÃ§Â»Â§Ã§Â”ÂµÃ¥Â™Â¨Ã¥ÂÂÃ©Â¦ÂˆÃ§ÂŠÂ¶Ã¦Â€ÂÃ¤Â¿Â¡Ã¥ÂÂ·Sub_CAN:To HUD";
CM_ SG_ 661 RemPowerFailureSts "Remote power failure status";
CM_ SG_ 661 RemUpgrdModSysPower "Remote upgrade system power mode";
CM_ SG_ 770 WarnPowerNotInOffPosn "Power not in off warning,when the driver close the door and exit with carrying the key
Ã§Â”ÂµÃ¦ÂºÂÃ¦ÂœÂªÃ¥Â…Â³Ã¦ÂŠÂ¥Ã¨Â­Â¦Ã¤Â¿Â¡Ã¥ÂÂ·IP Received";
CM_ SG_ 770 WarnKeyInCarWhenExit "Key in car warning,when the driver exit and close the door
Ã©Â’Â¥Ã¥ÂŒÂ™Ã©ÂÂ—Ã¥Â¿Â˜Ã¨Â½Â¦Ã¥Â†Â…Ã¦ÂŠÂ¥Ã¨Â­Â¦Ã¤Â¿Â¡Ã¥ÂÂ·IP Received";
CM_ SG_ 770 WarnVldKeyNotFound "Valid Key not found  in the vehicle warningIP Received";
CM_ SG_ 770 WarnEngStrtNotMeet "Indicate the engine start condition is not meetIP Received";
CM_ SG_ 770 PowerRlyFault "ACC(reserved),IGN1 or IGN2 Relay rault,which is no same to the relay driver output status.
Ã§Â»Â§Ã§Â”ÂµÃ¥Â™Â¨Ã¦Â•Â…Ã©ÂšÂœIP Received";
CM_ SG_ 770 AntLostFlg "Antenna lost flag
Ã¥Â¤Â©Ã§ÂºÂ¿Ã¦Â•Â…Ã©ÂšÂœÃ¤Â¿Â¡Ã¥ÂÂ·";
CM_ SG_ 412 HiPosnBrkLmpFailSts "High position Brake lamp failure statusIP Received";
CM_ SG_ 412 LBrkLmpFailSts "Left  Brake lamp failure stausIP Received";
CM_ SG_ 412 RFogLmpFailSts_R_PBox "Rear fog lamp failure statusIP Received";
CM_ SG_ 412 RFogLmpSts_R_PBox "Rear fog lamp statusIP Received";
CM_ SG_ 412 ParkLmpSts_R_PBox "Park lamp statusIP Received";
CM_ SG_ 412 RBrkLmpFailSts "Right  Brake lamp failure stausIP Received";
CM_ SG_ 412 PosnLmpOutpSts_R_PBox "Position lamp output statusIP Received
HUT_Sub:To HUD";
CM_ SG_ 412 RRPosnLmpFailSts "Right rear  position lamp failure stausIP Received";
CM_ SG_ 412 RvsLmpFailSts "Revers Lamp failure stausIP Received";
CM_ SG_ 412 LRPosnLmpFailSts "Left  rear position lamp failure statusIP Received";
CM_ SG_ 412 LTurnLmpSts_R_PBox "Left turn lamp statusIP Received";
CM_ SG_ 412 RTurnLmpSts_R_PBox "Right turn lamp statusIP Received";
CM_ SG_ 412 RWinHeatgIconRlyCmd "Rear Window Heating Icon RelayCommandthis signal is transferred to CCSM by BCM";
CM_ SG_ 412 RWinHeatgFailSts "Rear Window Heating Status";
CM_ SG_ 412 LicPlateLmpFailSts "License plate lamp fail statusIP Received";
CM_ SG_ 412 RTurnLmpFailSts "Right turn lamp failure status";
CM_ SG_ 412 LTurnLmpFailSts "Left turn lamp failure status";
CM_ SG_ 412 LBrkLmpOutpSts_R_PBox "Left  Brake lamp output status";
CM_ SG_ 412 RBrkLmpOutpSts_R_PBox "Right  Brake lamp output status";
CM_ SG_ 412 HiPosnBrkLmpOutpSts_R_PBox "High position Brake lamp output status";
CM_ SG_ 412 MAC_Check_R_PBox1 "MAC protection mechanism should comply with the GWM MAC Specificatio";
CM_ SG_ 367 RSDS_IPSoundReq "IP sound RequestIP Received";
CM_ SG_ 367 RSDS_ErrSts "show the RSDS status of  failureIP Received";
CM_ SG_ 367 RSDS_BrkgTrig "Indicate the CTA Braking function had been triggeredIP Received";
CM_ SG_ 367 RSDS_BliSts "RSDS Blindness StatesIP Received";
CM_ SG_ 367 RSDS_TrailerSts "RSDS Trailer StatesIP Received";
CM_ SG_ 367 RSDS_LCAResp "Indicate LCAÃ¯Â¼ÂˆLane Change AssistÃ‚Â Ã¯Â¼Â‰ Switch statusIP Received";
CM_ SG_ 367 RSDS_DOWResp "Indicate DOW(door open warning) Switch status";
CM_ SG_ 367 RSDS_RCWResp "Indicate RCWÃ¯Â¼ÂˆRear Collision Warning Ã¯Â¼Â‰ Switch status";
CM_ SG_ 367 RSDS_RCTAResp "Indicate CTA  Ã¯Â¼ÂˆCross Traffic Assist Ã¯Â¼Â‰Switch status";
CM_ SG_ 367 RSDS_RCTABrkResp "Indicate CTA _Brake Ã¯Â¼ÂˆCross Traffic Assist With BrakeÃ¯Â¼Â‰Switch status";
CM_ SG_ 367 RSDS_RCW_Trigger "indicate RCW trigger statusIP Received";
CM_ SG_ 367 RSDS_CTA_Actv "show the CTA  Ã¯Â¼ÂˆCross Traffic Assist Ã¯Â¼Â‰statusIP Received";
CM_ SG_ 367 BSD_LCA_warningReqRight "Request BSDLCA right side warning element";
CM_ SG_ 367 BSD_LCA_warningReqleft "Request BSDLCA left side warning element";
CM_ SG_ 367 DOW_warningReqRight "Request DOW right side warning element";
CM_ SG_ 367 DOW_warningReqleft "Request DOW left side warning element";
CM_ SG_ 367 RCTA_warningReqRight "Request RCTA right side warning element";
CM_ SG_ 367 RCTA_warningReqLeft "Request RCTA left side warning element";
CM_ SG_ 778 RCTA_B_TTC "RCTARCTB TTC";
CM_ SG_ 778 BSD_LCA_Left_TTC "Left  BSD_LCA  TTC";
CM_ SG_ 778 BSD_LCA_Right_TTC "Right  BSD_LCA  TTC";
CM_ SG_ 778 RCW_TTC "RCW TTC(Rear collision warning)";
CM_ SG_ 778 RSDS_LeTgt_01 "left first targrt from RSDS";
CM_ SG_ 778 RSDS_LeTgt_01_dx "left first targrt of dx  from RSDS";
CM_ SG_ 778 RSDS_LeTgt_01_dy "left first targrt of dy  from RSDS";
CM_ SG_ 778 RSDS_LeTgt_02 "left second targrt from RSDS";
CM_ SG_ 778 RSDS_LeTgt_02_dx "left second targrt of dx  from RSDS";
CM_ SG_ 778 RSDS_LeTgt_02_dy "left second targrt of dy  from RSDS";
CM_ SG_ 778 RSDS_RiTgt_01 "right first targrt from RSDS";
CM_ SG_ 778 RSDS_RiTgt_01_dx "right first targrt of dx  from RSDS";
CM_ SG_ 778 RSDS_RiTgt_01_dy "right first targrt of dy  from RSDS";
CM_ SG_ 778 RSDS_RiTgt_02 "right second targrt from RSDS";
CM_ SG_ 778 RSDS_RiTgt_02_dx "right second targrt of dx  from RSDS";
CM_ SG_ 778 RSDS_RiTgt_02_dy "right second targrt of dy  from RSDS";
CM_ SG_ 778 RSDS_MidTgt_01 "left first targrt from RSDS";
CM_ SG_ 778 RSDS_MidTgt_01_dx "middle first targrt of dx  from RSDS";
CM_ SG_ 778 RSDS_MidTgt_01_dy "middle first targrt of dy  from RSDS";
CM_ SG_ 778 RSDS_MidTgt_02 "middle second targrt from RSDS";
CM_ SG_ 778 RSDS_MidTgt_02_dx "middle second targrt of dx  from RSDS";
CM_ SG_ 778 RSDS_MidTgt_02_dy "middle second targrt of dy  from RSDS";
CM_ SG_ 51 T_BOX_RemtDoorLockCtrl "Remote door lock control";
CM_ SG_ 51 T_BOX_AudioMuteReq "Request HUT mute the Audio.";
CM_ SG_ 51 T_BOX_PM25AirQLvl "PM2.5 air quality level";
CM_ SG_ 51 T_BOX_PM25Dens "PM2.5 density";
CM_ SG_ 51 MAC_Check_T_BOX_FD1 "MAC protection mechanism should comply with the GWM MAC Specificatio";
CM_ SG_ 1001 T_BOX_SysErrSts "System error statusADAS-CANFD To:IFC,IDC_L2";
CM_ SG_ 1001 T_BOX_SWUpdSts "Software update status";
CM_ SG_ 1001 FreshnessValue_T_BOX_FD3 "ADAS-CANFD To:IDC_L2";
CM_ SG_ 1001 MAC_Check_T_BOX_FD3 "MAC protection mechanism should comply with the GWM MAC SpecificatioADAS-CANFD To:IDC_L2";
CM_ SG_ 481 T_BOX_RemtVideoMonrEnaReq_APP "remote video monitor enable request from APP";
CM_ SG_ 752 V2X_FCW "V2X_Forward Collision Warning";
CM_ SG_ 752 V2X_BSW "V2X_Blind Spot Warning";
CM_ SG_ 752 V2X_LCW "V2X_Lane Change Warning";
CM_ SG_ 752 V2X_EBW "V2X_Emergency Brake Warning";
CM_ SG_ 752 V2X_ICW "V2X_Intersection Collision Warning";
CM_ SG_ 752 V2X_LTA "V2X_Left Turn Assist";
CM_ SG_ 752 V2X_IVSW "V2X_In-Vehicle Signage Warning";
CM_ SG_ 752 V2X_AVW "V2X_Abnormal Vehicle  Warning";
CM_ SG_ 752 V2X_EVW "V2X_Emergency Vehicle Warning";
CM_ SG_ 752 V2X_DNPW "V2X_Do Not Pass Warning";
CM_ SG_ 752 V2X_HLW "V2X_Hazardous Location Warning";
CM_ SG_ 752 V2X_TJW "V2X_Traffic Jam Warning";
CM_ SG_ 752 V2X_CLW "V2X_Control Loss Warning";
CM_ SG_ 752 V2X_RLVW "V2X_Red Light Violation Warning";
CM_ SG_ 752 V2X_VRUCW "V2X_Vulnerable Road User Collision Warning";
CM_ SG_ 752 V2X_SLW "V2X_Speed Limit Warning";
CM_ SG_ 752 V2X_GLOSA "V2X_Green Light Optimal Speed Advisory";
CM_ SG_ 752 V2X_SL1_LightTyp "V2X_Single Lamp1-LightType";
CM_ SG_ 752 V2X_SL1_LightColor "V2X_Single Lamp1-LightColor";
CM_ SG_ 752 V2X_SL1_LightTim "V2X_Single Lamp1-Light Time";
CM_ SG_ 752 V2X_SL2_LightTyp "V2X_Single Lamp2-LightType";
CM_ SG_ 752 V2X_SL2_LightColor "V2X_Single Lamp2-LightColor";
CM_ SG_ 752 V2X_SL2_LightTim "V2X_Single Lamp2-Light Time";
CM_ SG_ 752 V2X_SL3_LightTyp "V2X_Single Lamp3-LightType";
CM_ SG_ 752 V2X_SL3_LightColor "V2X_Single Lamp3-LightColor";
CM_ SG_ 752 V2X_SL3_LightTim "V2X_Single Lamp3-Light Time";
CM_ SG_ 752 V2X_SL4_LightTyp "V2X_Single Lamp4-Light Type";
CM_ SG_ 752 V2X_SL4_LightColor "V2X_Single Lamp4-Light Color";
CM_ SG_ 752 V2X_SL5_LightTyp "V2X_Single Lamp5-LightType";
CM_ SG_ 752 V2X_SL4_LightTim "V2X_Single Lamp4-Light Time";
CM_ SG_ 752 V2X_SL5_LightColor "V2X_Single Lamp5-LightColor";
CM_ SG_ 752 V2X_SL5_LightTim "V2X_Single Lamp5-Light Time";
CM_ SG_ 752 V2X_SL6_LightTyp "V2X_Single Lamp6-LightType";
CM_ SG_ 752 V2X_SL6_LightColor "V2X_Single Lamp6-LightColor";
CM_ SG_ 752 V2X_SL6_LightTim "V2X_Single Lamp6-Light Time";
CM_ SG_ 752 V2X_SL7_LightTyp "V2X_Single Lamp7-LightType";
CM_ SG_ 752 V2X_SL7_LightColor "V2X_Single Lamp7-LightColor";
CM_ SG_ 752 V2X_SL7_LightTim "V2X_Single Lamp7-Light Time";
CM_ SG_ 752 V2X_SL8_LightTyp "V2X_Single Lamp8-LightType";
CM_ SG_ 752 V2X_SL8_LightColor "V2X_Single Lamp8-LightColor";
CM_ SG_ 752 V2X_SL8_LightTim "V2X_Single Lamp8-Light Time";
CM_ SG_ 752 V2X_SL_of_Veh "V2X_ Signal Light of  Vehicle";
CM_ SG_ 593 FuncProtnSts "Identifies the function demotion status through wheel speed.IP Received";
CM_ SG_ 593 ShiftSysStuInLow "Shift System Stuck in Low";
CM_ SG_ 593 SystemOperMod "Identifies the current AWD(all wheel drive) Mode";
CM_ SG_ 593 CouplingFaultSts "indicates that which fault the coupling  has";
CM_ SG_ 593 CouplingThermWarning "Indicates that the system is shutdown due to thermal protection WarningIP Received";
CM_ SG_ 593 DiagLmpReq "Identifies there is a light diagnostic lamp request.";
CM_ SG_ 593 ModeShiftTimeout "Mode Shift Timeout";
CM_ SG_ 593 AutoShiftSts "Identifies there is a light Neutral mode lamp request";
CM_ SG_ 593 EstimatedTorque "Estimated Coupling Torque";
CM_ SG_ 833 FLTirePressIndSts "Front left tire pressure Indicator statusIP Received";
CM_ SG_ 833 FRTirePressIndSts "Front right  tire pressure Indicator statusIP Received";
CM_ SG_ 833 TirePressSysFailrIndcn "Tire pressure system failure indicationIP Received";
CM_ SG_ 833 RLTirePressIndSts "Rear left  tire pressure Indicator statusIP Received";
CM_ SG_ 833 RRTirePressIndSts "Rear right tire pressure Indicator statusIP Received";
CM_ SG_ 833 FLTireTempSts "Front left tire tempperature statusIP Received";
CM_ SG_ 833 FRTireTempSts "Front right tire tempperature statusIP Received";
CM_ SG_ 833 RLTireTempSts "Rear left tire tempperature statusIP Received";
CM_ SG_ 833 RRTireTempSts "Rear right tire tempperature statusIP Received";
CM_ SG_ 833 MAC_Check_TPMS1 "MAC protection mechanism should comply with the GWM MAC Specificatio";
CM_ SG_ 917 FLTirePress "Left front tire pressureIP Received";
CM_ SG_ 917 FLTireTemp "Left front tire temperatureIP Received";
CM_ SG_ 917 FRTirePress "Right front tire pressureIP Received";
CM_ SG_ 917 FRTireTemp "Right front tire temperatureIP Received";
CM_ SG_ 917 RLTirePress "Left rear tire pressureIP Received";
CM_ SG_ 917 RLTireTemp "Left rear tire temperatureIP Received";
CM_ SG_ 917 RRTirePress "Right rear tire pressureIP Received";
CM_ SG_ 917 RRTireTemp "Right rear tire temperatureIP Received";
CM_ SG_ 917 MAC_Check_TPMS2 "MAC protection mechanism should comply with the GWM MAC Specificatio";
CM_ SG_ 627 TrailerSts "Trailer Status";
CM_ SG_ 698 WPC_ChrgSts "Describe the status of charge of the WPC:standby,charging,charging completed,WPC failure.";
CM_ SG_ 698 WPC_SwtSts "WPC Switch Status";
CM_ SG_ 698 WPC_FaultSts "Describe the current failure status of WPC.";
CM_ SG_ 698 WPC_PhoneReminder "Describe whether there is a phone forgotten in the car.";
CM_ SG_ 785 DOCK_ExternalDevice_P "DOCK External Device (Period)";
CM_ SG_ 479 DOCK_HUT_ExternalDevice_E "DOCK_HUT External Device (Event)";
CM_ SG_ 718 DrvSeatMassLvlSetSts "Driver Seat Massage Level Set Status";
CM_ SG_ 718 DrvSeatMassModeSts "Driver Seat Massage Mode Status";
CM_ SG_ 718 PassSeatMassgLvlSetSts "Passager Seat Massage Level Set Status";
CM_ SG_ 718 RLSeatMassgLvlSetSts "Rear Left Seat massage  level set status";
CM_ SG_ 718 RRSeatMassgLvlSetSts "Rear Right Seat massage  level set status";
CM_ SG_ 718 PassSeatMassgModeSts "Passager Seat Massage Mode Status";
CM_ SG_ 718 RLSeatMassgModSts "Rear Left Seat massage mode status";
CM_ SG_ 718 RRSeatMassgModSts "Rear Right Seat massage mode status";
CM_ SG_ 604 BLEConnSts "Smartphone BLE and vehicle BLE connection status";
CM_ SG_ 604 BLESecuritySts "Smartphone BLE and vehicle BLE Security certification status";
CM_ SG_ 506 BLE_BeanID "Bluetooth bean ID";
CM_ SG_ 473 OTA_UpgrdModErrCode "Unable to enter the vehicle upgrade mode.";
CM_ SG_ 721 DrvSeatVentnSts "The driver side seat ventilation status";
CM_ SG_ 721 PassSeatVentnSts "The passenger side seat ventilation status";
CM_ SG_ 497 AntiDisIdnRndNumber "Anti-dismantle identification random number";
CM_ SG_ 836 AntiDisIdnResult "Anti-dismantle identification result";
CM_ SG_ 836 SelfChkSts "Status of Self-Check";
CM_ SG_ 836 ActvdSts "Status of Activation of the ESAM";
CM_ SG_ 498 TransSts "Transaction Status";
CM_ SG_ 498 EntrAndExitCdn "Entrance And Exit Condition";
CM_ SG_ 498 TransAmnt "Amount of the Transaction";
CM_ SG_ 776 LHiBeamSts "High beam status";
CM_ SG_ 776 LHiBeamFailSts_HCM "Left High beam failure status";
CM_ SG_ 776 LLowBeamSts "Low beam status";
CM_ SG_ 776 LLowBeamFailSts_HCM "Left Low beam  failure status";
CM_ SG_ 772 Checksum_HCM_L2 "Use the checksum strategy from document Ã¢Â€ÂœEnd-to-End Communication Protection SpecificationÃ¢Â€Â";
CM_ SG_ 772 LeftLightShowSts "Light show processstatus";
CM_ SG_ 772 FLMusicLightShowSts "Front Left Light show processstatus";
CM_ SG_ 772 RollingCounter_HCM_L2 "Rolling Counter";
CM_ SG_ 781 RHiBeamSts "Right High beam status";
CM_ SG_ 781 RHiBeamFailSts_HCM "Right High beam failure status";
CM_ SG_ 781 RLowBeamSts "Right Low beam status";
CM_ SG_ 781 RLowBeamFailSts_HCM "Right Low beam  failure status";
CM_ SG_ 816 Checksum_HCM_R2 "Use the checksum strategy from document Ã¢Â€ÂœEnd-to-End Communication Protection SpecificationÃ¢Â€Â";
CM_ SG_ 816 RightLightShowSts "Light show processstatus";
CM_ SG_ 816 FRMusicLightShowSts "Front Right Light show processstatus";
CM_ SG_ 816 RollingCounter_HCM_R2 "Rolling Counter";
CM_ SG_ 647 CheckSum_HC1 "Use the checksum strategy from document Ã¢Â€ÂœEnd-to-End Communication Protection SpecificationÃ¢Â€Â";
CM_ SG_ 647 ALS_FailSts "ALS failure status";
CM_ SG_ 647 RollingCounter_HC1 "Rolling counter_HC1";
CM_ SG_ 818 RFLLightShowSts "Rear fender left light show processstatus";
CM_ SG_ 819 RFRLightShowSts "Rear fender right light show processstatus";
CM_ SG_ 483 BMS_ChrgTimResp "Charg Time Response";
CM_ SG_ 850 BMS_IntelEngIdlChrgnSts "Intelligent Engine Idle Charging statusSC_CAN:To HUT";
CM_ SG_ 850 BMS_BattKeepTempSts "Battery Keep Temperature stateSC_CAN:To HUT";
CM_ SG_ 959 BMS_ChrgDurationTime "Charge Duration Time in minute";
CM_ SG_ 1009 BMS_SOCLowWarn "SOC is too low,need to charge,IP need light the lamp.IP receive";
CM_ SG_ 942 BMS_SocJumpWarn_RM "BMS_SocJumpWarn Rank";
CM_ SG_ 942 BMS_PackOverChrgWarn_RM "BMS_Pack Over Charge warning Rank";
CM_ SG_ 942 BMS_ChrgSts_RM "BMS Charge status";
CM_ SG_ 942 BMS_IsolationRValue_RM "Isolation resistance value";
CM_ SG_ 942 BMS_PackCurr_RM "Pack Current";
CM_ SG_ 942 BMS_SocOverWarn_RM "BMS_Soc over warning Rank";
CM_ SG_ 942 BMS_BattOverTempRank_RM "battery temperature is too higher";
CM_ SG_ 942 BMS_BattOverVoltRank_RM "battery pack over voltage Rank";
CM_ SG_ 942 BMS_BattSOCLowRank_RM "SOC low Rank";
CM_ SG_ 942 BMS_VCUIsolateErr_RM "BMS_VCU Isolate  Error";
CM_ SG_ 942 BMS_BattUnderVoltRank_RM "battery pack under voltage Rank";
CM_ SG_ 942 BMS_CellDeltaVoltRank_RM "cell delta voltage Rank";
CM_ SG_ 942 BMS_CellOverVoltRank_RM "cell over voltage Rank";
CM_ SG_ 942 BMS_CellUnderVoltRank_RM "cell under voltage Rank";
CM_ SG_ 942 BMS_DeltaTempRank_RM "delta temperature Rank";
CM_ SG_ 942 BMS_PackMismatchWarn_RM "BMS_Pack Mismatchwarning Rank";
CM_ SG_ 942 BMS_PackVolt_RM "Pack Voltage";
CM_ SG_ 645 BMS_BattHeatRunaway "Battery  Heat  Runaway";
CM_ SG_ 645 BMS_DisSOC1 "display battery SOC";
CM_ SG_ 142 EngTrqCrankshaftLvl "Actual engine torque at crankshaft level (fast path)HUT_sub:TO AMP";
CM_ SG_ 142 EngTrqCrankshaftLvlValid "Actual engine torque at crankshaft level (fast path) ValidityHUT_sub:TO AMP";
CM_ SG_ 279 EngState_PHEV "Engine status.HUT";
CM_ SG_ 279 CruiseCtrlSts_PHEV "Cruise control statusIP";
CM_ SG_ 96 HCU_AccelPedalPosn_Diag "Physical acceleration pedal position.
it represents the physical value of acceleration pedal even in CCACC case, in which case normal acceleration pedal is replaced by virtual pedal position.IP Received";
CM_ SG_ 96 HCU_AccelPedalPosn_DiagValid "Flag: Physical acceleration pedal position validIP Received";
CM_ SG_ 96 HCU_PowertrainSts_0x60 "Powertrain Status.";
CM_ SG_ 96 HCU_RaceLaunchSts_0x60 "Race Launch function is active or deactivateIP Received";
CM_ SG_ 96 HCU_RaceLaunchAvail_0x60 "HCU Race Launch AvailIP Received";
CM_ SG_ 96 HCU_AccelPedalPosn "Acceleration pedal position
shall represent real physical pedal position or in case of CCACCHDCCCOAPA active a pedal value calculated from the torque request";
CM_ SG_ 96 HCU_AccelPedalPosnValid "Flag: Accelerator pedal value valid<accelerator pedal actual position validity>";
CM_ SG_ 616 HCU_BattLowTempWarn "Battery low temperature low warn";
CM_ SG_ 616 HCU_BattLowTempHeatSts "Low temperature heating state of battery";
CM_ SG_ 788 HCU_ACLineDisconnect "AC Line Disconnect";
CM_ SG_ 788 HCU_ChargSts "Charging  statue  displayIPHUT Received";
CM_ SG_ 788 HCU_IntelBattTempMagSts "Intelligent Battery Temperature Management stateSC_CAN:To HUT";
CM_ SG_ 482 HCU_TotalScore "the Total score of the  driverÃ¢Â€Â˜s drive style and  energy consumption in this dirve cycle";
CM_ SG_ 249 HCU_TrqLimMax_Norm "Torque Normalization value which reflect 100% torque on CAN bus,Current value is 550Nm.HUT_sub:To AMP";
CM_ SG_ 330 HCUImmoAuthRes "Immo authorisation resultIP";
CM_ SG_ 330 HCU_EVLmpSts "EV lamp signalIP";
CM_ SG_ 330 HCU_ECODrvHabit_Indcn "Economic Indication of driving habitsIP";
CM_ SG_ 330 HCU_TotDrvReqPower_0x14a "total driver request PowerIP";
CM_ SG_ 330 HCU_AvailPower_TM "rear emotor available powerIP";
CM_ SG_ 330 HCU_DrvMod "Represents currently active driving mode. It is also used to transmit terrain response modes (sand mud snow)HUT_sub:TO AMP";
CM_ SG_ 282 HCU_HybMod "Represents currently active dhybrid mode.";
CM_ SG_ 282 HCU_HybFctnMod "Represents currently battery SOC management mode and currently sport plus mode";
CM_ SG_ 448 HCU_ChrgSysLmpSts "Charge system indicate lamp statusIP Received";
CM_ SG_ 448 HCU_ChrgSysErr_1 "Charge system error indicate word:On board charger errorÃ¯Â¼ÂŒ go to the service piont.IP Received";
CM_ SG_ 448 HCU_ChrgSysErr_2 "Charge system error indicate word: Charge system errorÃ¯Â¼ÂŒ charging stoppedIP Received";
CM_ SG_ 448 HCU_ChrgSysErr_3 "Charge system error indicate word:  Charging stopped due to insuff power supply lowIP Received";
CM_ SG_ 448 HCU_ChrgSysErr_4 "Charge system error indicate word:  Charging stopped due to charger over temperatureIP Received";
CM_ SG_ 448 HCU_ChrgSysErr_5 "Charge system error indicate word:  Charging stopped due to battery over temperatureIP Received";
CM_ SG_ 448 HCU_ChrgSysErr_6 "Charge system error indicate word:  Charging stopped due to  battery temperature lowIP Received";
CM_ SG_ 448 HCU_ChrgSysErr_7 "Charge system error indicate word:  Charger output power  lowIP Received";
CM_ SG_ 448 HCU_ChrgSysErr_8 "Charge system error indicate word:  Charging stopped due to charge line not connect rightIP Received";
CM_ SG_ 448 HCU_DrvModDisp "Represents currently active driving mode to HUTFrom HCU_FD4";
CM_ SG_ 513 HCU_V2LReminder "V2L relevant
tips";
CM_ SG_ 513 HCU_SOCMngmntSts "The status of Soc management function";
CM_ SG_ 513 HCU_ARFSts "The status of adaptive recuperation function";
CM_ SG_ 513 HCU_ASFCSts "The status of adaptive startstop control function";
CM_ SG_ 513 HCU_AGSSts "The status of adaptive gear shifting function";
CM_ SG_ 513 PDCU_AvailabilityOfARF "the current availability status of the ARF function for display";
CM_ SG_ 513 PDCU_lossenPedalPrompt "the display signal about loosenthe accelerator pedal to IP for display at prompt time";
CM_ SG_ 513 PDCU_EvSave_disl "Inform the driver of Currently in 4L mode,EVSAVE mode is not availableÃ¢Â€Â";
CM_ SG_ 690 ExpertModReq_HUT_HCU "HCU mode  request by HUTPT_CAN:To PDCU";
CM_ SG_ 301 EB_TgtRcprtnTrqSts "Status of Target Recuperation torque of Generator";
CM_ SG_ 172 P2M_ActTrq "Actual torque at EM(Electric Motor) shaftHUT_sub:To AMP";
CM_ SG_ 190 P2M_ActSpd "Actual mechanical speed of EM(Electric Motor)PT_CAN:To ECM DCT
SC_CANFD:To HUT,T_BOX,VIMS,DVR";
CM_ SG_ 190 P2M_ActHvDcVolt "Actual HV DC(High Voltage Direct Current link) voltage";
CM_ SG_ 510 T_BOX_ChrgTim_Day "The Charge Time for daysHC_CAN:To PDCU";
CM_ SG_ 697 DWD_WorkSts "DWD work status";
CM_ SG_ 697 DWD_TextDisp "DWD Text Display";
CM_ SG_ 697 DWD_Dis "DWD Distance";
CM_ SG_ 697 DWD_SoundIndcn "DWD Sound Indication";
CM_ SG_ 697 RSnsrFailSts "Sensor fault status of the Right sensor";
CM_ SG_ 697 LSnsrFailSts "Sensor fault status of the Left sensor";
CM_ SG_ 790 OBC_ModSts "mode status of charger";
CM_ SG_ 791 OBC_ConnectSts "OBC charge connect statusIP Received";
CM_ SG_ 708 BMS_BattSOCLimResp "After BMS received signal\"BattSOCLim\" , BMS shall make a Response to confirm wether received successful or not";
CM_ SG_ 486 MultiColorNr1 "Multi color number1";
CM_ SG_ 486 MultiColorNr2 "Multi color number2";
CM_ SG_ 486 MultiColorNr3 "Multi color number3";
CM_ SG_ 486 MultiColorNr4 "Multi color number4";
CM_ SG_ 486 MultiColorNr5 "Multi color number5";
CM_ SG_ 486 MultiColorNr6 "Multi color number6";
CM_ SG_ 486 MultiColorNr7 "Multi color number7";
CM_ SG_ 486 MultiColorNr8 "Multi color number8";
CM_ SG_ 492 MultiColorNr9 "Multi color number9";
CM_ SG_ 492 MultiColorNr10 "Multi color number10";
CM_ SG_ 492 MultiColorNr11 "Multi color number11";
CM_ SG_ 492 MultiColorNr12 "Multi color number12";
CM_ SG_ 492 MultiColorNr13 "Multi color number13";
CM_ SG_ 492 MultiColorNr14 "Multi color number14";
CM_ SG_ 492 MultiColorNr15 "Multi color number15";
CM_ SG_ 492 MultiColorNr16 "Multi color number16";
CM_ SG_ 130 NetEngTrq "Current engine flywheel torque.";
CM_ SG_ 130 DrvEngTrqReq "Torque request from ACCeleration pedal or from CCACC.
It is burning torque, without any torque limitation, without filtering, without  consideration of external intervention, with idle controller, no torque intervention, not minus engine loss.Sub_CAN:To HUD";
CM_ SG_ 258 AccelPedlPosnDiagc "Physical acceleration pedal position.IP Received";
CM_ SG_ 132 HCU_RaceLaunchAvail_0x84 "HCU Race Launch Avail";
CM_ SG_ 132 HCU_RaceLaunchSts_0x84 "Race Launch function is active or deactivate";
CM_ SG_ 724 DPF_Warning "This signal is used for IP to dispalay the regeneration state of the DPF(Disel Particulate Filter).IP Received";
CM_ SG_ 724 WIFSensorFailSts "Fuel water box sensor failure statusIP Received";
CM_ SG_ 724 GlowPlugLmpCmd "Glow plug working statusIP Received";
CM_ SG_ 724 UreaLampCmd "This signal is a indicator to display the AUS system working stateIP Received";
CM_ SG_ 724 Urea_Level "This signal is a indicator to display the remain AUS solution in the tank. This signal is from ECU, and in ECU It is computed throuth the AUS tank volume and the signal from DCU.
The level display will be 0%Ã£Â€Â5%Ã£Â€Â10%Ã£Â€Â15%Ã£Â€Â20%Ã£Â€Â25%Ã£Â€Â30%Ã£Â€Â35%Ã£Â€Â40%Ã£Â€Â45%Ã£Â€Â50%Ã£Â€Â55%Ã£Â€Â60%Ã£Â€Â65%Ã£Â€Â70%Ã£Â€Â75%Ã£Â€Â80%Ã£Â€Â85%Ã£Â€Â90%Ã£Â€Â95%Ã£Â€Â100%IP Received";
CM_ SG_ 724 UreaRemainDist "This signal is used to display the estimated remain distance due to the Urea volume in tank.IP Received";
CM_ SG_ 724 SCRSysWarnDisplay "This signal is used to display the messages of SCR system failure mode,to inform the driver to operate in time to avold system damage and keep the vehicle performance.IP Received";
CM_ SG_ 724 WIFFullLmpCmd "Fuel water box statusIP Received";
CM_ SG_ 724 DPF_Activation "This signal is used for HUT to activate the regeneration keys of the DPF(Diesel Particulate Filter)";
CM_ SG_ 848 EngOilLvlWrn "Engine oil  warning";
CM_ SG_ 848 EngOilLowPresWrn "Engine oil low pressure warning";
CM_ SG_ 848 EngOilPres "Engine oil pressure";
CM_ SG_ 848 EngOilTemp "Engine oil temperature";
CM_ SG_ 335 BMS_BattSOC_P0 "Battery SOCIP Received";
CM_ SG_ 158 HCU_PowertrainSts_0x9e "Powertrain Status.";
CM_ SG_ 158 HCU_TotDrvReqPower_0x9e "total driver request PowerIP Received";
CM_ SG_ 158 TgtRcprtnTrqSts "Status of Target Recuperation torque of Generator";

BA_DEF_ BO_ "DiagRequest" ENUM  "No","Yes";
BA_DEF_ BO_ "DiagResponse" ENUM  "No","Yes";
BA_DEF_ BO_ "DiagState" ENUM  "No","Yes";
BA_DEF_ BO_ "GenMsgCycleTime" INT 0 65535;
BA_DEF_ BO_ "GenMsgCycleTimeFast" INT 0 65535;
BA_DEF_ BO_ "GenMsgILSupport" ENUM  "No","Yes";
BA_DEF_ BO_ "GenMsgNrOfRepetition" INT 0 65535;
BA_DEF_ BO_ "GenMsgSendType" ENUM  "Cyclic","CyclicAndSpontanX","Event";
BA_DEF_ BO_ "NmAsrMessage" ENUM  "No","Yes";
BA_DEF_ BO_ "OriginFrame" STRING;
BA_DEF_ BO_ "SCP_AuthInfoTxLength" INT 0 512;
BA_DEF_ BO_ "SCP_DataId" INT 0 65535;
BA_DEF_ BO_ "SCP_FreshnessValueLength" INT 0 512;
BA_DEF_ BO_ "SCP_FreshnessValueTxLength" INT 0 512;
BA_DEF_ BO_ "SC_Message" ENUM  "NO","YES";
BA_DEF_ BO_ "VFrameFormat" ENUM  "StandardCAN","ExtendedCAN","reserved","reserved","reserved","reserved","reserved","reserved","reserved","reserved","reserved","reserved","reserved","reserved","StandardCAN_FD","ExtendedCAN_FD";
BA_DEF_ SG_ "GenSigCycleTime" INT 0 65535;
BA_DEF_ SG_ "GenSigSendType" ENUM  "Cyclic","OnWrite","OnWriteWithRepetition","OnChange","OnChangeWithRepetition","NotUsed","NotUsed","NoSigSendType";
BA_DEF_ SG_ "GenSigStartValue" FLOAT 0 100000000000;
BA_DEF_ SG_ "Match" STRING;
BA_DEF_ SG_ "Origin" STRING;
BA_DEF_ SG_ "SystemSignalLongSymbol" STRING;
BA_DEF_DEF_ "DiagRequest" "No";
BA_DEF_DEF_ "DiagResponse" "No";
BA_DEF_DEF_ "DiagState" "No";
BA_DEF_DEF_ "GenMsgCycleTime" 0;
BA_DEF_DEF_ "GenMsgCycleTimeFast" 0;
BA_DEF_DEF_ "GenMsgILSupport" "No";
BA_DEF_DEF_ "GenMsgNrOfRepetition" 0;
BA_DEF_DEF_ "GenMsgSendType" "Cyclic";
BA_DEF_DEF_ "GenSigCycleTime" 0;
BA_DEF_DEF_ "GenSigSendType" "Cyclic";
BA_DEF_DEF_ "GenSigStartValue" 0;
BA_DEF_DEF_ "Match" "";
BA_DEF_DEF_ "NmAsrMessage" "No";
BA_DEF_DEF_ "Origin" "";
BA_DEF_DEF_ "OriginFrame" "";
BA_DEF_DEF_ "SCP_AuthInfoTxLength" 0;
BA_DEF_DEF_ "SCP_DataId" 0;
BA_DEF_DEF_ "SCP_FreshnessValueLength" 0;
BA_DEF_DEF_ "SCP_FreshnessValueTxLength" 0;
BA_DEF_DEF_ "SC_Message" "NO";
BA_DEF_DEF_ "SystemSignalLongSymbol" "";
BA_DEF_DEF_ "VFrameFormat" "";
BA_ "GenMsgCycleTime" BO_ 659 100;
BA_ "GenMsgILSupport" BO_ 659 1;
BA_ "OriginFrame" BO_ 659 "fuel,ev";
BA_ "VFrameFormat" BO_ 659 14;
BA_ "GenMsgCycleTime" BO_ 639 50;
BA_ "GenMsgILSupport" BO_ 639 1;
BA_ "OriginFrame" BO_ 639 "fuel,ev";
BA_ "SCP_AuthInfoTxLength" BO_ 639 48;
BA_ "SCP_DataId" BO_ 639 639;
BA_ "SCP_FreshnessValueLength" BO_ 639 64;
BA_ "SCP_FreshnessValueTxLength" BO_ 639 16;
BA_ "SC_Message" BO_ 639 1;
BA_ "VFrameFormat" BO_ 639 14;
BA_ "GenMsgCycleTime" BO_ 842 500;
BA_ "GenMsgILSupport" BO_ 842 1;
BA_ "OriginFrame" BO_ 842 "fuel,ev";
BA_ "VFrameFormat" BO_ 842 14;
BA_ "GenMsgCycleTime" BO_ 717 100;
BA_ "GenMsgILSupport" BO_ 717 1;
BA_ "OriginFrame" BO_ 717 "fuel,ev";
BA_ "VFrameFormat" BO_ 717 14;
BA_ "GenMsgCycleTime" BO_ 661 50;
BA_ "GenMsgILSupport" BO_ 661 1;
BA_ "OriginFrame" BO_ 661 "fuel,ev";
BA_ "VFrameFormat" BO_ 661 14;
BA_ "GenMsgCycleTime" BO_ 770 200;
BA_ "GenMsgCycleTimeFast" BO_ 770 20;
BA_ "GenMsgILSupport" BO_ 770 1;
BA_ "GenMsgNrOfRepetition" BO_ 770 5;
BA_ "OriginFrame" BO_ 770 "fuel,ev";
BA_ "VFrameFormat" BO_ 770 14;
BA_ "GenMsgCycleTime" BO_ 412 50;
BA_ "GenMsgILSupport" BO_ 412 1;
BA_ "OriginFrame" BO_ 412 "fuel,ev";
BA_ "SCP_AuthInfoTxLength" BO_ 412 48;
BA_ "SCP_DataId" BO_ 412 412;
BA_ "SCP_FreshnessValueLength" BO_ 412 64;
BA_ "SCP_FreshnessValueTxLength" BO_ 412 16;
BA_ "SC_Message" BO_ 412 1;
BA_ "VFrameFormat" BO_ 412 14;
BA_ "GenMsgCycleTime" BO_ 367 20;
BA_ "GenMsgILSupport" BO_ 367 1;
BA_ "OriginFrame" BO_ 367 "fuel,ev";
BA_ "VFrameFormat" BO_ 367 14;
BA_ "GenMsgCycleTime" BO_ 778 200;
BA_ "GenMsgILSupport" BO_ 778 1;
BA_ "OriginFrame" BO_ 778 "fuel,ev";
BA_ "VFrameFormat" BO_ 778 14;
BA_ "GenMsgCycleTimeFast" BO_ 51 20;
BA_ "GenMsgILSupport" BO_ 51 1;
BA_ "GenMsgNrOfRepetition" BO_ 51 5;
BA_ "GenMsgSendType" BO_ 51 2;
BA_ "OriginFrame" BO_ 51 "fuel,ev";
BA_ "SCP_AuthInfoTxLength" BO_ 51 48;
BA_ "SCP_DataId" BO_ 51 51;
BA_ "SCP_FreshnessValueLength" BO_ 51 64;
BA_ "SCP_FreshnessValueTxLength" BO_ 51 16;
BA_ "SC_Message" BO_ 51 1;
BA_ "VFrameFormat" BO_ 51 14;
BA_ "GenMsgCycleTime" BO_ 1001 1000;
BA_ "GenMsgILSupport" BO_ 1001 1;
BA_ "OriginFrame" BO_ 1001 "fuel,ev";
BA_ "SCP_AuthInfoTxLength" BO_ 1001 48;
BA_ "SCP_DataId" BO_ 1001 1001;
BA_ "SCP_FreshnessValueLength" BO_ 1001 64;
BA_ "SCP_FreshnessValueTxLength" BO_ 1001 16;
BA_ "SC_Message" BO_ 1001 1;
BA_ "VFrameFormat" BO_ 1001 14;
BA_ "GenMsgCycleTimeFast" BO_ 481 20;
BA_ "GenMsgILSupport" BO_ 481 1;
BA_ "GenMsgNrOfRepetition" BO_ 481 5;
BA_ "GenMsgSendType" BO_ 481 2;
BA_ "OriginFrame" BO_ 481 "fuel,ev";
BA_ "VFrameFormat" BO_ 481 14;
BA_ "GenMsgCycleTime" BO_ 752 100;
BA_ "GenMsgILSupport" BO_ 752 1;
BA_ "OriginFrame" BO_ 752 "fuel,ev";
BA_ "VFrameFormat" BO_ 752 14;
BA_ "GenMsgCycleTime" BO_ 593 20;
BA_ "GenMsgILSupport" BO_ 593 1;
BA_ "OriginFrame" BO_ 593 "fuel,ev";
BA_ "VFrameFormat" BO_ 593 14;
BA_ "GenMsgCycleTime" BO_ 833 500;
BA_ "GenMsgILSupport" BO_ 833 1;
BA_ "OriginFrame" BO_ 833 "fuel,ev";
BA_ "SCP_AuthInfoTxLength" BO_ 833 48;
BA_ "SCP_DataId" BO_ 833 833;
BA_ "SCP_FreshnessValueLength" BO_ 833 64;
BA_ "SCP_FreshnessValueTxLength" BO_ 833 16;
BA_ "SC_Message" BO_ 833 1;
BA_ "VFrameFormat" BO_ 833 14;
BA_ "GenMsgCycleTime" BO_ 917 500;
BA_ "GenMsgILSupport" BO_ 917 1;
BA_ "OriginFrame" BO_ 917 "fuel,ev";
BA_ "SCP_AuthInfoTxLength" BO_ 917 48;
BA_ "SCP_DataId" BO_ 917 917;
BA_ "SCP_FreshnessValueLength" BO_ 917 64;
BA_ "SCP_FreshnessValueTxLength" BO_ 917 16;
BA_ "SC_Message" BO_ 917 1;
BA_ "VFrameFormat" BO_ 917 14;
BA_ "GenMsgCycleTime" BO_ 627 50;
BA_ "GenMsgILSupport" BO_ 627 1;
BA_ "OriginFrame" BO_ 627 "fuel,ev";
BA_ "VFrameFormat" BO_ 627 14;
BA_ "GenMsgCycleTime" BO_ 698 100;
BA_ "GenMsgILSupport" BO_ 698 1;
BA_ "OriginFrame" BO_ 698 "fuel,ev";
BA_ "VFrameFormat" BO_ 698 14;
BA_ "GenMsgCycleTime" BO_ 785 200;
BA_ "GenMsgILSupport" BO_ 785 1;
BA_ "OriginFrame" BO_ 785 "fuel,ev";
BA_ "VFrameFormat" BO_ 785 14;
BA_ "GenMsgCycleTimeFast" BO_ 479 20;
BA_ "GenMsgILSupport" BO_ 479 1;
BA_ "GenMsgNrOfRepetition" BO_ 479 5;
BA_ "GenMsgSendType" BO_ 479 2;
BA_ "OriginFrame" BO_ 479 "fuel,ev";
BA_ "VFrameFormat" BO_ 479 14;
BA_ "GenMsgCycleTime" BO_ 718 100;
BA_ "GenMsgILSupport" BO_ 718 1;
BA_ "OriginFrame" BO_ 718 "fuel,ev";
BA_ "VFrameFormat" BO_ 718 14;
BA_ "GenMsgCycleTime" BO_ 604 50;
BA_ "GenMsgILSupport" BO_ 604 1;
BA_ "OriginFrame" BO_ 604 "fuel,ev";
BA_ "VFrameFormat" BO_ 604 14;
BA_ "GenMsgCycleTimeFast" BO_ 506 20;
BA_ "GenMsgILSupport" BO_ 506 1;
BA_ "GenMsgNrOfRepetition" BO_ 506 5;
BA_ "GenMsgSendType" BO_ 506 2;
BA_ "OriginFrame" BO_ 506 "fuel,ev";
BA_ "VFrameFormat" BO_ 506 14;
BA_ "GenMsgCycleTimeFast" BO_ 473 20;
BA_ "GenMsgILSupport" BO_ 473 1;
BA_ "GenMsgNrOfRepetition" BO_ 473 5;
BA_ "GenMsgSendType" BO_ 473 2;
BA_ "OriginFrame" BO_ 473 "fuel,ev";
BA_ "VFrameFormat" BO_ 473 14;
BA_ "GenMsgCycleTime" BO_ 721 100;
BA_ "GenMsgILSupport" BO_ 721 1;
BA_ "OriginFrame" BO_ 721 "fuel,ev";
BA_ "VFrameFormat" BO_ 721 14;
BA_ "GenMsgCycleTimeFast" BO_ 497 20;
BA_ "GenMsgILSupport" BO_ 497 1;
BA_ "GenMsgNrOfRepetition" BO_ 497 5;
BA_ "GenMsgSendType" BO_ 497 2;
BA_ "OriginFrame" BO_ 497 "fuel,ev";
BA_ "VFrameFormat" BO_ 497 14;
BA_ "GenMsgCycleTime" BO_ 836 500;
BA_ "GenMsgILSupport" BO_ 836 1;
BA_ "OriginFrame" BO_ 836 "fuel,ev";
BA_ "VFrameFormat" BO_ 836 14;
BA_ "GenMsgCycleTimeFast" BO_ 498 20;
BA_ "GenMsgILSupport" BO_ 498 1;
BA_ "GenMsgNrOfRepetition" BO_ 498 5;
BA_ "GenMsgSendType" BO_ 498 2;
BA_ "OriginFrame" BO_ 498 "fuel,ev";
BA_ "VFrameFormat" BO_ 498 14;
BA_ "GenMsgCycleTime" BO_ 776 200;
BA_ "GenMsgILSupport" BO_ 776 1;
BA_ "OriginFrame" BO_ 776 "fuel,ev";
BA_ "VFrameFormat" BO_ 776 14;
BA_ "GenMsgCycleTime" BO_ 772 200;
BA_ "GenMsgILSupport" BO_ 772 1;
BA_ "OriginFrame" BO_ 772 "fuel,ev";
BA_ "VFrameFormat" BO_ 772 14;
BA_ "GenMsgCycleTime" BO_ 781 200;
BA_ "GenMsgILSupport" BO_ 781 1;
BA_ "OriginFrame" BO_ 781 "fuel,ev";
BA_ "VFrameFormat" BO_ 781 14;
BA_ "GenMsgCycleTime" BO_ 816 200;
BA_ "GenMsgILSupport" BO_ 816 1;
BA_ "OriginFrame" BO_ 816 "fuel,ev";
BA_ "VFrameFormat" BO_ 816 14;
BA_ "GenMsgCycleTime" BO_ 647 100;
BA_ "GenMsgILSupport" BO_ 647 1;
BA_ "OriginFrame" BO_ 647 "fuel,ev";
BA_ "VFrameFormat" BO_ 647 14;
BA_ "GenMsgCycleTime" BO_ 818 200;
BA_ "GenMsgILSupport" BO_ 818 1;
BA_ "OriginFrame" BO_ 818 "fuel,ev";
BA_ "VFrameFormat" BO_ 818 14;
BA_ "GenMsgCycleTime" BO_ 819 200;
BA_ "GenMsgILSupport" BO_ 819 1;
BA_ "OriginFrame" BO_ 819 "fuel,ev";
BA_ "VFrameFormat" BO_ 819 14;
BA_ "DiagState" BO_ 1888 1;
BA_ "GenMsgSendType" BO_ 1888 2;
BA_ "OriginFrame" BO_ 1888 "fuel,ev";
BA_ "VFrameFormat" BO_ 1888 14;
BA_ "DiagRequest" BO_ 1889 1;
BA_ "GenMsgSendType" BO_ 1889 2;
BA_ "OriginFrame" BO_ 1889 "fuel,ev";
BA_ "VFrameFormat" BO_ 1889 14;
BA_ "DiagRequest" BO_ 1918 1;
BA_ "GenMsgSendType" BO_ 1918 2;
BA_ "OriginFrame" BO_ 1918 "fuel,ev";
BA_ "VFrameFormat" BO_ 1918 14;
BA_ "DiagRequest" BO_ 1843 1;
BA_ "GenMsgSendType" BO_ 1843 2;
BA_ "OriginFrame" BO_ 1843 "fuel,ev";
BA_ "VFrameFormat" BO_ 1843 14;
BA_ "DiagRequest" BO_ 1907 1;
BA_ "GenMsgSendType" BO_ 1907 2;
BA_ "OriginFrame" BO_ 1907 "fuel,ev";
BA_ "VFrameFormat" BO_ 1907 14;
BA_ "DiagResponse" BO_ 1953 1;
BA_ "GenMsgSendType" BO_ 1953 2;
BA_ "OriginFrame" BO_ 1953 "fuel,ev";
BA_ "VFrameFormat" BO_ 1953 14;
BA_ "DiagResponse" BO_ 1982 1;
BA_ "GenMsgSendType" BO_ 1982 2;
BA_ "OriginFrame" BO_ 1982 "fuel,ev";
BA_ "VFrameFormat" BO_ 1982 14;
BA_ "DiagResponse" BO_ 1844 1;
BA_ "GenMsgSendType" BO_ 1844 2;
BA_ "OriginFrame" BO_ 1844 "fuel,ev";
BA_ "VFrameFormat" BO_ 1844 14;
BA_ "DiagResponse" BO_ 1971 1;
BA_ "GenMsgSendType" BO_ 1971 2;
BA_ "OriginFrame" BO_ 1971 "fuel,ev";
BA_ "VFrameFormat" BO_ 1971 14;
BA_ "GenMsgSendType" BO_ 1290 2;
BA_ "NmAsrMessage" BO_ 1290 1;
BA_ "OriginFrame" BO_ 1290 "fuel,ev";
BA_ "VFrameFormat" BO_ 1290 0;
BA_ "GenMsgSendType" BO_ 1289 2;
BA_ "NmAsrMessage" BO_ 1289 1;
BA_ "OriginFrame" BO_ 1289 "fuel,ev";
BA_ "VFrameFormat" BO_ 1289 0;
BA_ "GenMsgSendType" BO_ 1334 2;
BA_ "NmAsrMessage" BO_ 1334 1;
BA_ "OriginFrame" BO_ 1334 "fuel,ev";
BA_ "VFrameFormat" BO_ 1334 0;
BA_ "GenMsgSendType" BO_ 1281 2;
BA_ "NmAsrMessage" BO_ 1281 1;
BA_ "OriginFrame" BO_ 1281 "fuel,ev";
BA_ "VFrameFormat" BO_ 1281 0;
BA_ "GenMsgILSupport" BO_ 1122 1;
BA_ "GenMsgSendType" BO_ 1122 2;
BA_ "OriginFrame" BO_ 1122 "fuel,ev";
BA_ "VFrameFormat" BO_ 1122 14;
BA_ "OriginFrame" BO_ 1121 "fuel,ev";
BA_ "SCP_AuthInfoTxLength" BO_ 1121 88;
BA_ "SCP_DataId" BO_ 1121 1121;
BA_ "SCP_FreshnessValueLength" BO_ 1121 40;
BA_ "SCP_FreshnessValueTxLength" BO_ 1121 40;
BA_ "SC_Message" BO_ 1121 1;
BA_ "VFrameFormat" BO_ 1121 14;
BA_ "GenMsgCycleTimeFast" BO_ 483 20;
BA_ "GenMsgILSupport" BO_ 483 1;
BA_ "GenMsgNrOfRepetition" BO_ 483 5;
BA_ "GenMsgSendType" BO_ 483 2;
BA_ "OriginFrame" BO_ 483 "ev";
BA_ "VFrameFormat" BO_ 483 14;
BA_ "GenMsgCycleTime" BO_ 850 500;
BA_ "GenMsgILSupport" BO_ 850 1;
BA_ "OriginFrame" BO_ 850 "ev";
BA_ "VFrameFormat" BO_ 850 14;
BA_ "GenMsgCycleTime" BO_ 959 1000;
BA_ "GenMsgILSupport" BO_ 959 1;
BA_ "OriginFrame" BO_ 959 "ev";
BA_ "VFrameFormat" BO_ 959 14;
BA_ "GenMsgCycleTime" BO_ 1009 1000;
BA_ "GenMsgILSupport" BO_ 1009 1;
BA_ "OriginFrame" BO_ 1009 "ev";
BA_ "VFrameFormat" BO_ 1009 14;
BA_ "GenMsgCycleTime" BO_ 942 1000;
BA_ "GenMsgILSupport" BO_ 942 1;
BA_ "OriginFrame" BO_ 942 "ev";
BA_ "VFrameFormat" BO_ 942 14;
BA_ "GenMsgCycleTime" BO_ 645 100;
BA_ "GenMsgILSupport" BO_ 645 1;
BA_ "OriginFrame" BO_ 645 "ev";
BA_ "VFrameFormat" BO_ 645 14;
BA_ "GenMsgCycleTime" BO_ 142 10;
BA_ "GenMsgILSupport" BO_ 142 1;
BA_ "OriginFrame" BO_ 142 "ev";
BA_ "VFrameFormat" BO_ 142 14;
BA_ "GenMsgCycleTime" BO_ 279 20;
BA_ "GenMsgILSupport" BO_ 279 1;
BA_ "OriginFrame" BO_ 279 "ev";
BA_ "VFrameFormat" BO_ 279 14;
BA_ "GenMsgCycleTime" BO_ 96 10;
BA_ "GenMsgILSupport" BO_ 96 1;
BA_ "OriginFrame" BO_ 96 "ev";
BA_ "VFrameFormat" BO_ 96 14;
BA_ "GenMsgCycleTime" BO_ 616 50;
BA_ "GenMsgILSupport" BO_ 616 1;
BA_ "OriginFrame" BO_ 616 "ev";
BA_ "VFrameFormat" BO_ 616 14;
BA_ "GenMsgCycleTime" BO_ 788 200;
BA_ "GenMsgILSupport" BO_ 788 1;
BA_ "OriginFrame" BO_ 788 "ev";
BA_ "VFrameFormat" BO_ 788 14;
BA_ "GenMsgCycleTimeFast" BO_ 482 20;
BA_ "GenMsgILSupport" BO_ 482 1;
BA_ "GenMsgNrOfRepetition" BO_ 482 5;
BA_ "GenMsgSendType" BO_ 482 2;
BA_ "OriginFrame" BO_ 482 "ev";
BA_ "VFrameFormat" BO_ 482 14;
BA_ "GenMsgCycleTime" BO_ 249 10;
BA_ "GenMsgILSupport" BO_ 249 1;
BA_ "OriginFrame" BO_ 249 "ev";
BA_ "VFrameFormat" BO_ 249 14;
BA_ "GenMsgCycleTime" BO_ 330 20;
BA_ "GenMsgILSupport" BO_ 330 1;
BA_ "OriginFrame" BO_ 330 "ev";
BA_ "VFrameFormat" BO_ 330 14;
BA_ "GenMsgCycleTime" BO_ 282 20;
BA_ "GenMsgILSupport" BO_ 282 1;
BA_ "OriginFrame" BO_ 282 "ev";
BA_ "VFrameFormat" BO_ 282 14;
BA_ "GenMsgCycleTime" BO_ 448 50;
BA_ "GenMsgILSupport" BO_ 448 1;
BA_ "OriginFrame" BO_ 448 "ev";
BA_ "VFrameFormat" BO_ 448 14;
BA_ "GenMsgCycleTime" BO_ 513 50;
BA_ "GenMsgILSupport" BO_ 513 1;
BA_ "OriginFrame" BO_ 513 "ev";
BA_ "VFrameFormat" BO_ 513 14;
BA_ "GenMsgCycleTime" BO_ 690 100;
BA_ "GenMsgILSupport" BO_ 690 1;
BA_ "OriginFrame" BO_ 690 "ev";
BA_ "VFrameFormat" BO_ 690 14;
BA_ "GenMsgCycleTime" BO_ 301 20;
BA_ "GenMsgILSupport" BO_ 301 1;
BA_ "OriginFrame" BO_ 301 "ev";
BA_ "VFrameFormat" BO_ 301 14;
BA_ "GenMsgCycleTime" BO_ 172 10;
BA_ "GenMsgILSupport" BO_ 172 1;
BA_ "OriginFrame" BO_ 172 "ev";
BA_ "VFrameFormat" BO_ 172 14;
BA_ "GenMsgCycleTime" BO_ 190 10;
BA_ "GenMsgILSupport" BO_ 190 1;
BA_ "OriginFrame" BO_ 190 "ev";
BA_ "VFrameFormat" BO_ 190 14;
BA_ "GenMsgCycleTimeFast" BO_ 510 20;
BA_ "GenMsgILSupport" BO_ 510 1;
BA_ "GenMsgNrOfRepetition" BO_ 510 5;
BA_ "GenMsgSendType" BO_ 510 2;
BA_ "OriginFrame" BO_ 510 "ev";
BA_ "VFrameFormat" BO_ 510 14;
BA_ "GenMsgCycleTime" BO_ 697 100;
BA_ "GenMsgILSupport" BO_ 697 1;
BA_ "OriginFrame" BO_ 697 "ev";
BA_ "VFrameFormat" BO_ 697 14;
BA_ "GenMsgCycleTime" BO_ 790 200;
BA_ "GenMsgILSupport" BO_ 790 1;
BA_ "OriginFrame" BO_ 790 "ev";
BA_ "VFrameFormat" BO_ 790 14;
BA_ "GenMsgCycleTime" BO_ 791 200;
BA_ "GenMsgILSupport" BO_ 791 1;
BA_ "OriginFrame" BO_ 791 "ev";
BA_ "VFrameFormat" BO_ 791 14;
BA_ "GenMsgCycleTime" BO_ 708 100;
BA_ "GenMsgILSupport" BO_ 708 1;
BA_ "OriginFrame" BO_ 708 "ev";
BA_ "VFrameFormat" BO_ 708 14;
BA_ "GenMsgCycleTimeFast" BO_ 486 20;
BA_ "GenMsgILSupport" BO_ 486 1;
BA_ "GenMsgNrOfRepetition" BO_ 486 5;
BA_ "GenMsgSendType" BO_ 486 2;
BA_ "OriginFrame" BO_ 486 "fuel";
BA_ "VFrameFormat" BO_ 486 14;
BA_ "GenMsgCycleTimeFast" BO_ 492 20;
BA_ "GenMsgILSupport" BO_ 492 1;
BA_ "GenMsgNrOfRepetition" BO_ 492 5;
BA_ "GenMsgSendType" BO_ 492 2;
BA_ "OriginFrame" BO_ 492 "fuel";
BA_ "VFrameFormat" BO_ 492 14;
BA_ "GenMsgCycleTime" BO_ 130 10;
BA_ "GenMsgILSupport" BO_ 130 1;
BA_ "OriginFrame" BO_ 130 "fuel";
BA_ "VFrameFormat" BO_ 130 14;
BA_ "GenMsgCycleTime" BO_ 258 20;
BA_ "GenMsgILSupport" BO_ 258 1;
BA_ "OriginFrame" BO_ 258 "fuel";
BA_ "VFrameFormat" BO_ 258 14;
BA_ "GenMsgCycleTime" BO_ 132 10;
BA_ "GenMsgILSupport" BO_ 132 1;
BA_ "OriginFrame" BO_ 132 "fuel";
BA_ "VFrameFormat" BO_ 132 14;
BA_ "GenMsgCycleTime" BO_ 724 100;
BA_ "GenMsgILSupport" BO_ 724 1;
BA_ "OriginFrame" BO_ 724 "fuel";
BA_ "VFrameFormat" BO_ 724 14;
BA_ "GenMsgCycleTime" BO_ 848 500;
BA_ "GenMsgILSupport" BO_ 848 1;
BA_ "OriginFrame" BO_ 848 "fuel";
BA_ "VFrameFormat" BO_ 848 14;
BA_ "GenMsgCycleTime" BO_ 335 20;
BA_ "GenMsgILSupport" BO_ 335 1;
BA_ "OriginFrame" BO_ 335 "fuel";
BA_ "VFrameFormat" BO_ 335 14;
BA_ "GenMsgCycleTime" BO_ 158 10;
BA_ "GenMsgILSupport" BO_ 158 1;
BA_ "OriginFrame" BO_ 158 "fuel";
BA_ "VFrameFormat" BO_ 158 14;
BA_ "GenSigCycleTime" SG_ 659 IP_CurrTheme 100;
BA_ "GenSigStartValue" SG_ 659 IP_CurrTheme 4;
BA_ "Match" SG_ 659 IP_CurrTheme "IP_CurrTheme";
BA_ "Origin" SG_ 659 IP_CurrTheme "fuel,ev";
BA_ "GenSigCycleTime" SG_ 659 IP_VehSpdDisp 100;
BA_ "Match" SG_ 659 IP_VehSpdDisp "IP_VehSpdDisp";
BA_ "Origin" SG_ 659 IP_VehSpdDisp "fuel,ev";
BA_ "GenSigCycleTime" SG_ 659 IP_VelSpdDisp_Mile 100;
BA_ "Match" SG_ 659 IP_VelSpdDisp_Mile "IP_VelSpdDisp_Mile";
BA_ "Origin" SG_ 659 IP_VelSpdDisp_Mile "fuel,ev";
BA_ "GenSigCycleTime" SG_ 659 IP_FuelMainTankR 100;
BA_ "GenSigStartValue" SG_ 659 IP_FuelMainTankR 10;
BA_ "Match" SG_ 659 IP_FuelMainTankR "IP_FuelMainTankR";
BA_ "Origin" SG_ 659 IP_FuelMainTankR "fuel,ev";
BA_ "GenSigCycleTime" SG_ 659 IP_FuelAuxTankR 100;
BA_ "GenSigStartValue" SG_ 659 IP_FuelAuxTankR 10;
BA_ "Match" SG_ 659 IP_FuelAuxTankR "IP_FuelAuxTankR";
BA_ "Origin" SG_ 659 IP_FuelAuxTankR "fuel,ev";
BA_ "GenSigCycleTime" SG_ 659 IP_LagueSet 100;
BA_ "GenSigStartValue" SG_ 659 IP_LagueSet 15;
BA_ "Match" SG_ 659 IP_LagueSet "IP_LagueSet";
BA_ "Origin" SG_ 659 IP_LagueSet "fuel,ev";
BA_ "GenSigCycleTime" SG_ 639 CheckSum_IP2 50;
BA_ "Match" SG_ 639 CheckSum_IP2 "CheckSum_IP2";
BA_ "Origin" SG_ 639 CheckSum_IP2 "fuel,ev";
BA_ "GenSigCycleTime" SG_ 639 IP_DrvSeatBeltWarnLmpFailSts 50;
BA_ "Match" SG_ 639 IP_DrvSeatBeltWarnLmpFailSts "IP_DrvSeatBeltWarnLmpFailSts";
BA_ "Origin" SG_ 639 IP_DrvSeatBeltWarnLmpFailSts "fuel,ev";
BA_ "GenSigCycleTime" SG_ 639 IP_PassSeatBeltWarnLmpFailSts 50;
BA_ "Match" SG_ 639 IP_PassSeatBeltWarnLmpFailSts "IP_PassSeatBeltWarnLmpFailSts";
BA_ "Origin" SG_ 639 IP_PassSeatBeltWarnLmpFailSts "fuel,ev";
BA_ "GenSigCycleTime" SG_ 639 IP_VehTotDistance 50;
BA_ "Match" SG_ 639 IP_VehTotDistance "IP_VehTotDistance";
BA_ "Origin" SG_ 639 IP_VehTotDistance "fuel,ev";
BA_ "GenSigCycleTime" SG_ 639 IP_VehTotDistanceValid 50;
BA_ "Match" SG_ 639 IP_VehTotDistanceValid "IP_VehTotDistanceValid";
BA_ "Origin" SG_ 639 IP_VehTotDistanceValid "fuel,ev";
BA_ "GenSigCycleTime" SG_ 639 IP_FuelLvlInfo 50;
BA_ "Match" SG_ 639 IP_FuelLvlInfo "IP_FuelLvlInfo";
BA_ "Origin" SG_ 639 IP_FuelLvlInfo "fuel,ev";
BA_ "GenSigCycleTime" SG_ 639 IP_FuelLvlLowLmpSts 50;
BA_ "Match" SG_ 639 IP_FuelLvlLowLmpSts "IP_FuelLvlLowLmpSts";
BA_ "Origin" SG_ 639 IP_FuelLvlLowLmpSts "fuel,ev";
BA_ "GenSigCycleTime" SG_ 639 IP_BattChrgLmpSts 50;
BA_ "Match" SG_ 639 IP_BattChrgLmpSts "IP_BattChrgLmpSts";
BA_ "Origin" SG_ 639 IP_BattChrgLmpSts "fuel,ev";
BA_ "GenSigCycleTime" SG_ 639 IP_EngOilPressLowLmpSts 50;
BA_ "Match" SG_ 639 IP_EngOilPressLowLmpSts "IP_EngOilPressLowLmpSts";
BA_ "Origin" SG_ 639 IP_EngOilPressLowLmpSts "fuel,ev";
BA_ "GenSigCycleTime" SG_ 639 IP_ABMWarnLmpFailrSts 50;
BA_ "Match" SG_ 639 IP_ABMWarnLmpFailrSts "IP_ABMWarnLmpFailrSts";
BA_ "Origin" SG_ 639 IP_ABMWarnLmpFailrSts "fuel,ev";
BA_ "GenSigCycleTime" SG_ 639 IP_Err 50;
BA_ "Match" SG_ 639 IP_Err "IP_Err";
BA_ "Origin" SG_ 639 IP_Err "fuel,ev";
BA_ "GenSigCycleTime" SG_ 639 IP_ACCErr 50;
BA_ "Match" SG_ 639 IP_ACCErr "IP_ACCErr";
BA_ "Origin" SG_ 639 IP_ACCErr "fuel,ev";
BA_ "GenSigCycleTime" SG_ 639 IP_VehSpdUnit 50;
BA_ "Match" SG_ 639 IP_VehSpdUnit "IP_VehSpdUnit";
BA_ "Origin" SG_ 639 IP_VehSpdUnit "fuel,ev";
BA_ "GenSigCycleTime" SG_ 639 IP_VINcompr 50;
BA_ "Match" SG_ 639 IP_VINcompr "IP_VINcompr";
BA_ "Origin" SG_ 639 IP_VINcompr "fuel,ev";
BA_ "GenSigCycleTime" SG_ 639 RollingCounter_IP2 50;
BA_ "Match" SG_ 639 RollingCounter_IP2 "RollingCounter_IP2";
BA_ "Origin" SG_ 639 RollingCounter_IP2 "fuel,ev";
BA_ "GenSigCycleTime" SG_ 639 FreshnessValue_IP2 50;
BA_ "Match" SG_ 639 FreshnessValue_IP2 "FreshnessValue_IP2";
BA_ "Origin" SG_ 639 FreshnessValue_IP2 "fuel,ev";
BA_ "GenSigCycleTime" SG_ 639 MAC_Check_IP2 50;
BA_ "Match" SG_ 639 MAC_Check_IP2 "MAC_Check_IP2";
BA_ "Origin" SG_ 639 MAC_Check_IP2 "fuel,ev";
BA_ "GenSigCycleTime" SG_ 842 IP_RemainDistance 500;
BA_ "Match" SG_ 842 IP_RemainDistance "IP_RemainDistance";
BA_ "Origin" SG_ 842 IP_RemainDistance "fuel,ev";
BA_ "GenSigCycleTime" SG_ 842 IP_InstFuelConsUnit 500;
BA_ "Match" SG_ 842 IP_InstFuelConsUnit "IP_InstFuelConsUnit";
BA_ "Origin" SG_ 842 IP_InstFuelConsUnit "fuel,ev";
BA_ "GenSigCycleTime" SG_ 842 IP_EBDFailSts 500;
BA_ "Match" SG_ 842 IP_EBDFailSts "IP_EBDFailSts";
BA_ "Origin" SG_ 842 IP_EBDFailSts "fuel,ev";
BA_ "GenSigCycleTime" SG_ 842 IP_AvgFuelCons 500;
BA_ "GenSigStartValue" SG_ 842 IP_AvgFuelCons 4095;
BA_ "Match" SG_ 842 IP_AvgFuelCons "IP_AvgFuelCons";
BA_ "Origin" SG_ 842 IP_AvgFuelCons "fuel,ev";
BA_ "GenSigCycleTime" SG_ 842 IP_InstFuelCons 500;
BA_ "GenSigStartValue" SG_ 842 IP_InstFuelCons 16383;
BA_ "Match" SG_ 842 IP_InstFuelCons "IP_InstFuelCons";
BA_ "Origin" SG_ 842 IP_InstFuelCons "fuel,ev";
BA_ "GenSigCycleTime" SG_ 717 PassWinPosnSts_Perc 100;
BA_ "Match" SG_ 717 PassWinPosnSts_Perc "PassWinPosnSts_Perc";
BA_ "Origin" SG_ 717 PassWinPosnSts_Perc "fuel,ev";
BA_ "GenSigCycleTime" SG_ 717 PassWinLrnSts 100;
BA_ "Match" SG_ 717 PassWinLrnSts "PassWinLrnSts";
BA_ "Origin" SG_ 717 PassWinLrnSts "fuel,ev";
BA_ "GenSigCycleTime" SG_ 717 PassWinHotProtSts 100;
BA_ "Match" SG_ 717 PassWinHotProtSts "PassWinHotProtSts";
BA_ "Origin" SG_ 717 PassWinHotProtSts "fuel,ev";
BA_ "GenSigCycleTime" SG_ 717 PassSideRearWinPosnSts_Perc 100;
BA_ "Match" SG_ 717 PassSideRearWinPosnSts_Perc "PassSideRearWinPosnSts_Perc";
BA_ "Origin" SG_ 717 PassSideRearWinPosnSts_Perc "fuel,ev";
BA_ "GenSigCycleTime" SG_ 717 PassSideRearWinLrnSts 100;
BA_ "Match" SG_ 717 PassSideRearWinLrnSts "PassSideRearWinLrnSts";
BA_ "Origin" SG_ 717 PassSideRearWinLrnSts "fuel,ev";
BA_ "GenSigCycleTime" SG_ 717 PassSideRearWinHotProtSts 100;
BA_ "Match" SG_ 717 PassSideRearWinHotProtSts "PassSideRearWinHotProtSts";
BA_ "Origin" SG_ 717 PassSideRearWinHotProtSts "fuel,ev";
BA_ "GenSigCycleTime" SG_ 661 SysPowerMod 50;
BA_ "Match" SG_ 661 SysPowerMod "SysPowerMod";
BA_ "Origin" SG_ 661 SysPowerMod "fuel,ev";
BA_ "GenSigCycleTime" SG_ 661 SysPowerModVld 50;
BA_ "Match" SG_ 661 SysPowerModVld "SysPowerModVld";
BA_ "Origin" SG_ 661 SysPowerModVld "fuel,ev";
BA_ "GenSigCycleTime" SG_ 661 PEPS_PowerRlyOutpSts 50;
BA_ "Match" SG_ 661 PEPS_PowerRlyOutpSts "PEPS_PowerRlyOutpSts";
BA_ "Origin" SG_ 661 PEPS_PowerRlyOutpSts "fuel,ev";
BA_ "GenSigCycleTime" SG_ 661 RemPowerFailureSts 50;
BA_ "Match" SG_ 661 RemPowerFailureSts "RemPowerFailureSts";
BA_ "Origin" SG_ 661 RemPowerFailureSts "fuel,ev";
BA_ "GenSigCycleTime" SG_ 661 RemUpgrdModSysPower 50;
BA_ "Match" SG_ 661 RemUpgrdModSysPower "RemUpgrdModSysPower";
BA_ "Origin" SG_ 661 RemUpgrdModSysPower "fuel,ev";
BA_ "GenSigCycleTime" SG_ 770 WarnPowerNotInOffPosn 200;
BA_ "GenSigSendType" SG_ 770 WarnPowerNotInOffPosn 2;
BA_ "Match" SG_ 770 WarnPowerNotInOffPosn "WarnPowerNotInOffPosn";
BA_ "Origin" SG_ 770 WarnPowerNotInOffPosn "fuel,ev";
BA_ "GenSigCycleTime" SG_ 770 WarnKeyInCarWhenExit 200;
BA_ "GenSigSendType" SG_ 770 WarnKeyInCarWhenExit 2;
BA_ "Match" SG_ 770 WarnKeyInCarWhenExit "WarnKeyInCarWhenExit";
BA_ "Origin" SG_ 770 WarnKeyInCarWhenExit "fuel,ev";
BA_ "GenSigCycleTime" SG_ 770 WarnVldKeyNotFound 200;
BA_ "GenSigSendType" SG_ 770 WarnVldKeyNotFound 2;
BA_ "Match" SG_ 770 WarnVldKeyNotFound "WarnVldKeyNotFound";
BA_ "Origin" SG_ 770 WarnVldKeyNotFound "fuel,ev";
BA_ "GenSigCycleTime" SG_ 770 WarnEngStrtNotMeet 200;
BA_ "GenSigSendType" SG_ 770 WarnEngStrtNotMeet 2;
BA_ "Match" SG_ 770 WarnEngStrtNotMeet "WarnEngStrtNotMeet";
BA_ "Origin" SG_ 770 WarnEngStrtNotMeet "fuel,ev";
BA_ "GenSigCycleTime" SG_ 770 PowerRlyFault 200;
BA_ "GenSigSendType" SG_ 770 PowerRlyFault 2;
BA_ "Match" SG_ 770 PowerRlyFault "PowerRlyFault";
BA_ "Origin" SG_ 770 PowerRlyFault "fuel,ev";
BA_ "GenSigCycleTime" SG_ 770 AntLostFlg 200;
BA_ "GenSigSendType" SG_ 770 AntLostFlg 2;
BA_ "Match" SG_ 770 AntLostFlg "AntLostFlg";
BA_ "Origin" SG_ 770 AntLostFlg "fuel,ev";
BA_ "GenSigCycleTime" SG_ 412 HiPosnBrkLmpFailSts 50;
BA_ "Match" SG_ 412 HiPosnBrkLmpFailSts "HiPosnBrkLmpFailSts";
BA_ "Origin" SG_ 412 HiPosnBrkLmpFailSts "fuel,ev";
BA_ "GenSigCycleTime" SG_ 412 LBrkLmpFailSts 50;
BA_ "Match" SG_ 412 LBrkLmpFailSts "LBrkLmpFailSts";
BA_ "Origin" SG_ 412 LBrkLmpFailSts "fuel,ev";
BA_ "GenSigCycleTime" SG_ 412 RFogLmpFailSts_R_PBox 50;
BA_ "Match" SG_ 412 RFogLmpFailSts_R_PBox "RFogLmpFailSts_R_PBox";
BA_ "Origin" SG_ 412 RFogLmpFailSts_R_PBox "fuel,ev";
BA_ "GenSigCycleTime" SG_ 412 RFogLmpSts_R_PBox 50;
BA_ "Match" SG_ 412 RFogLmpSts_R_PBox "RFogLmpSts_R_PBox";
BA_ "Origin" SG_ 412 RFogLmpSts_R_PBox "fuel,ev";
BA_ "GenSigCycleTime" SG_ 412 ParkLmpSts_R_PBox 50;
BA_ "Match" SG_ 412 ParkLmpSts_R_PBox "ParkLmpSts_R_PBox";
BA_ "Origin" SG_ 412 ParkLmpSts_R_PBox "fuel,ev";
BA_ "GenSigCycleTime" SG_ 412 RBrkLmpFailSts 50;
BA_ "Match" SG_ 412 RBrkLmpFailSts "RBrkLmpFailSts";
BA_ "Origin" SG_ 412 RBrkLmpFailSts "fuel,ev";
BA_ "GenSigCycleTime" SG_ 412 PosnLmpOutpSts_R_PBox 50;
BA_ "Match" SG_ 412 PosnLmpOutpSts_R_PBox "PosnLmpOutpSts_R_PBox";
BA_ "Origin" SG_ 412 PosnLmpOutpSts_R_PBox "fuel,ev";
BA_ "GenSigCycleTime" SG_ 412 RRPosnLmpFailSts 50;
BA_ "Match" SG_ 412 RRPosnLmpFailSts "RRPosnLmpFailSts";
BA_ "Origin" SG_ 412 RRPosnLmpFailSts "fuel,ev";
BA_ "GenSigCycleTime" SG_ 412 RvsLmpFailSts 50;
BA_ "Match" SG_ 412 RvsLmpFailSts "RvsLmpFailSts";
BA_ "Origin" SG_ 412 RvsLmpFailSts "fuel,ev";
BA_ "GenSigCycleTime" SG_ 412 LRPosnLmpFailSts 50;
BA_ "Match" SG_ 412 LRPosnLmpFailSts "LRPosnLmpFailSts";
BA_ "Origin" SG_ 412 LRPosnLmpFailSts "fuel,ev";
BA_ "GenSigCycleTime" SG_ 412 LTurnLmpSts_R_PBox 50;
BA_ "Match" SG_ 412 LTurnLmpSts_R_PBox "LTurnLmpSts_R_PBox";
BA_ "Origin" SG_ 412 LTurnLmpSts_R_PBox "fuel,ev";
BA_ "GenSigCycleTime" SG_ 412 RTurnLmpSts_R_PBox 50;
BA_ "Match" SG_ 412 RTurnLmpSts_R_PBox "RTurnLmpSts_R_PBox";
BA_ "Origin" SG_ 412 RTurnLmpSts_R_PBox "fuel,ev";
BA_ "GenSigCycleTime" SG_ 412 RWinHeatgIconRlyCmd 50;
BA_ "Match" SG_ 412 RWinHeatgIconRlyCmd "RWinHeatgIconRlyCmd";
BA_ "Origin" SG_ 412 RWinHeatgIconRlyCmd "fuel,ev";
BA_ "GenSigCycleTime" SG_ 412 RWinHeatgFailSts 50;
BA_ "Match" SG_ 412 RWinHeatgFailSts "RWinHeatgFailSts";
BA_ "Origin" SG_ 412 RWinHeatgFailSts "fuel,ev";
BA_ "GenSigCycleTime" SG_ 412 LicPlateLmpFailSts 50;
BA_ "Match" SG_ 412 LicPlateLmpFailSts "LicPlateLmpFailSts";
BA_ "Origin" SG_ 412 LicPlateLmpFailSts "fuel,ev";
BA_ "GenSigCycleTime" SG_ 412 RTurnLmpFailSts 50;
BA_ "Match" SG_ 412 RTurnLmpFailSts "RTurnLmpFailSts";
BA_ "Origin" SG_ 412 RTurnLmpFailSts "fuel,ev";
BA_ "GenSigCycleTime" SG_ 412 LTurnLmpFailSts 50;
BA_ "Match" SG_ 412 LTurnLmpFailSts "LTurnLmpFailSts";
BA_ "Origin" SG_ 412 LTurnLmpFailSts "fuel,ev";
BA_ "GenSigCycleTime" SG_ 412 LBrkLmpOutpSts_R_PBox 50;
BA_ "Match" SG_ 412 LBrkLmpOutpSts_R_PBox "LBrkLmpOutpSts_R_PBox";
BA_ "Origin" SG_ 412 LBrkLmpOutpSts_R_PBox "fuel,ev";
BA_ "GenSigCycleTime" SG_ 412 RBrkLmpOutpSts_R_PBox 50;
BA_ "Match" SG_ 412 RBrkLmpOutpSts_R_PBox "RBrkLmpOutpSts_R_PBox";
BA_ "Origin" SG_ 412 RBrkLmpOutpSts_R_PBox "fuel,ev";
BA_ "GenSigCycleTime" SG_ 412 HiPosnBrkLmpOutpSts_R_PBox 50;
BA_ "Match" SG_ 412 HiPosnBrkLmpOutpSts_R_PBox "HiPosnBrkLmpOutpSts_R_PBox";
BA_ "Origin" SG_ 412 HiPosnBrkLmpOutpSts_R_PBox "fuel,ev";
BA_ "GenSigCycleTime" SG_ 412 FreshnessValue_R_PBox1 50;
BA_ "Match" SG_ 412 FreshnessValue_R_PBox1 "FreshnessValue_R_PBox1";
BA_ "Origin" SG_ 412 FreshnessValue_R_PBox1 "fuel,ev";
BA_ "GenSigCycleTime" SG_ 412 MAC_Check_R_PBox1 50;
BA_ "Match" SG_ 412 MAC_Check_R_PBox1 "MAC_Check_R_PBox1";
BA_ "Origin" SG_ 412 MAC_Check_R_PBox1 "fuel,ev";
BA_ "GenSigCycleTime" SG_ 367 RSDS_IPSoundReq 20;
BA_ "Match" SG_ 367 RSDS_IPSoundReq "RSDS_IPSoundReq";
BA_ "Origin" SG_ 367 RSDS_IPSoundReq "fuel,ev";
BA_ "GenSigCycleTime" SG_ 367 RSDS_ErrSts 20;
BA_ "Match" SG_ 367 RSDS_ErrSts "RSDS_ErrSts";
BA_ "Origin" SG_ 367 RSDS_ErrSts "fuel,ev";
BA_ "GenSigCycleTime" SG_ 367 RSDS_BrkgTrig 20;
BA_ "Match" SG_ 367 RSDS_BrkgTrig "RSDS_BrkgTrig";
BA_ "Origin" SG_ 367 RSDS_BrkgTrig "fuel,ev";
BA_ "GenSigCycleTime" SG_ 367 RSDS_BliSts 20;
BA_ "Match" SG_ 367 RSDS_BliSts "RSDS_BliSts";
BA_ "Origin" SG_ 367 RSDS_BliSts "fuel,ev";
BA_ "GenSigCycleTime" SG_ 367 RSDS_TrailerSts 20;
BA_ "Match" SG_ 367 RSDS_TrailerSts "RSDS_TrailerSts";
BA_ "Origin" SG_ 367 RSDS_TrailerSts "fuel,ev";
BA_ "GenSigCycleTime" SG_ 367 RSDS_LCAResp 20;
BA_ "Match" SG_ 367 RSDS_LCAResp "RSDS_LCAResp";
BA_ "Origin" SG_ 367 RSDS_LCAResp "fuel,ev";
BA_ "GenSigCycleTime" SG_ 367 RSDS_DOWResp 20;
BA_ "Match" SG_ 367 RSDS_DOWResp "RSDS_DOWResp";
BA_ "Origin" SG_ 367 RSDS_DOWResp "fuel,ev";
BA_ "GenSigCycleTime" SG_ 367 RSDS_RCWResp 20;
BA_ "Match" SG_ 367 RSDS_RCWResp "RSDS_RCWResp";
BA_ "Origin" SG_ 367 RSDS_RCWResp "fuel,ev";
BA_ "GenSigCycleTime" SG_ 367 RSDS_RCTAResp 20;
BA_ "Match" SG_ 367 RSDS_RCTAResp "RSDS_RCTAResp";
BA_ "Origin" SG_ 367 RSDS_RCTAResp "fuel,ev";
BA_ "GenSigCycleTime" SG_ 367 RSDS_RCTABrkResp 20;
BA_ "Match" SG_ 367 RSDS_RCTABrkResp "RSDS_RCTABrkResp";
BA_ "Origin" SG_ 367 RSDS_RCTABrkResp "fuel,ev";
BA_ "GenSigCycleTime" SG_ 367 RSDS_RCW_Trigger 20;
BA_ "Match" SG_ 367 RSDS_RCW_Trigger "RSDS_RCW_Trigger";
BA_ "Origin" SG_ 367 RSDS_RCW_Trigger "fuel,ev";
BA_ "GenSigCycleTime" SG_ 367 RSDS_CTA_Actv 20;
BA_ "Match" SG_ 367 RSDS_CTA_Actv "RSDS_CTA_Actv";
BA_ "Origin" SG_ 367 RSDS_CTA_Actv "fuel,ev";
BA_ "GenSigCycleTime" SG_ 367 BSD_LCA_warningReqRight 20;
BA_ "Match" SG_ 367 BSD_LCA_warningReqRight "BSD_LCA_warningReqRight";
BA_ "Origin" SG_ 367 BSD_LCA_warningReqRight "fuel,ev";
BA_ "GenSigCycleTime" SG_ 367 BSD_LCA_warningReqleft 20;
BA_ "Match" SG_ 367 BSD_LCA_warningReqleft "BSD_LCA_warningReqleft";
BA_ "Origin" SG_ 367 BSD_LCA_warningReqleft "fuel,ev";
BA_ "GenSigCycleTime" SG_ 367 DOW_warningReqRight 20;
BA_ "Match" SG_ 367 DOW_warningReqRight "DOW_warningReqRight";
BA_ "Origin" SG_ 367 DOW_warningReqRight "fuel,ev";
BA_ "GenSigCycleTime" SG_ 367 DOW_warningReqleft 20;
BA_ "Match" SG_ 367 DOW_warningReqleft "DOW_warningReqleft";
BA_ "Origin" SG_ 367 DOW_warningReqleft "fuel,ev";
BA_ "GenSigCycleTime" SG_ 367 RCTA_warningReqRight 20;
BA_ "Match" SG_ 367 RCTA_warningReqRight "RCTA_warningReqRight";
BA_ "Origin" SG_ 367 RCTA_warningReqRight "fuel,ev";
BA_ "GenSigCycleTime" SG_ 367 RCTA_warningReqLeft 20;
BA_ "Match" SG_ 367 RCTA_warningReqLeft "RCTA_warningReqLeft";
BA_ "Origin" SG_ 367 RCTA_warningReqLeft "fuel,ev";
BA_ "GenSigCycleTime" SG_ 778 RCTA_B_TTC 200;
BA_ "Match" SG_ 778 RCTA_B_TTC "RCTA_B_TTC";
BA_ "Origin" SG_ 778 RCTA_B_TTC "fuel,ev";
BA_ "GenSigCycleTime" SG_ 778 BSD_LCA_Left_TTC 200;
BA_ "Match" SG_ 778 BSD_LCA_Left_TTC "BSD_LCA_Left_TTC";
BA_ "Origin" SG_ 778 BSD_LCA_Left_TTC "fuel,ev";
BA_ "GenSigCycleTime" SG_ 778 BSD_LCA_Right_TTC 200;
BA_ "Match" SG_ 778 BSD_LCA_Right_TTC "BSD_LCA_Right_TTC";
BA_ "Origin" SG_ 778 BSD_LCA_Right_TTC "fuel,ev";
BA_ "GenSigCycleTime" SG_ 778 RCW_TTC 200;
BA_ "Match" SG_ 778 RCW_TTC "RCW_TTC";
BA_ "Origin" SG_ 778 RCW_TTC "fuel,ev";
BA_ "GenSigCycleTime" SG_ 778 RSDS_LeTgt_01 200;
BA_ "Match" SG_ 778 RSDS_LeTgt_01 "RSDS_LeTgt_01";
BA_ "Origin" SG_ 778 RSDS_LeTgt_01 "fuel,ev";
BA_ "GenSigCycleTime" SG_ 778 RSDS_LeTgt_01_dx 200;
BA_ "Match" SG_ 778 RSDS_LeTgt_01_dx "RSDS_LeTgt_01_dx";
BA_ "Origin" SG_ 778 RSDS_LeTgt_01_dx "fuel,ev";
BA_ "GenSigCycleTime" SG_ 778 RSDS_LeTgt_01_dy 200;
BA_ "Match" SG_ 778 RSDS_LeTgt_01_dy "RSDS_LeTgt_01_dy";
BA_ "Origin" SG_ 778 RSDS_LeTgt_01_dy "fuel,ev";
BA_ "GenSigCycleTime" SG_ 778 RSDS_LeTgt_02 200;
BA_ "Match" SG_ 778 RSDS_LeTgt_02 "RSDS_LeTgt_02";
BA_ "Origin" SG_ 778 RSDS_LeTgt_02 "fuel,ev";
BA_ "GenSigCycleTime" SG_ 778 RSDS_LeTgt_02_dx 200;
BA_ "Match" SG_ 778 RSDS_LeTgt_02_dx "RSDS_LeTgt_02_dx";
BA_ "Origin" SG_ 778 RSDS_LeTgt_02_dx "fuel,ev";
BA_ "GenSigCycleTime" SG_ 778 RSDS_LeTgt_02_dy 200;
BA_ "Match" SG_ 778 RSDS_LeTgt_02_dy "RSDS_LeTgt_02_dy";
BA_ "Origin" SG_ 778 RSDS_LeTgt_02_dy "fuel,ev";
BA_ "GenSigCycleTime" SG_ 778 RSDS_RiTgt_01 200;
BA_ "Match" SG_ 778 RSDS_RiTgt_01 "RSDS_RiTgt_01";
BA_ "Origin" SG_ 778 RSDS_RiTgt_01 "fuel,ev";
BA_ "GenSigCycleTime" SG_ 778 RSDS_RiTgt_01_dx 200;
BA_ "Match" SG_ 778 RSDS_RiTgt_01_dx "RSDS_RiTgt_01_dx";
BA_ "Origin" SG_ 778 RSDS_RiTgt_01_dx "fuel,ev";
BA_ "GenSigCycleTime" SG_ 778 RSDS_RiTgt_01_dy 200;
BA_ "Match" SG_ 778 RSDS_RiTgt_01_dy "RSDS_RiTgt_01_dy";
BA_ "Origin" SG_ 778 RSDS_RiTgt_01_dy "fuel,ev";
BA_ "GenSigCycleTime" SG_ 778 RSDS_RiTgt_02 200;
BA_ "Match" SG_ 778 RSDS_RiTgt_02 "RSDS_RiTgt_02";
BA_ "Origin" SG_ 778 RSDS_RiTgt_02 "fuel,ev";
BA_ "GenSigCycleTime" SG_ 778 RSDS_RiTgt_02_dx 200;
BA_ "Match" SG_ 778 RSDS_RiTgt_02_dx "RSDS_RiTgt_02_dx";
BA_ "Origin" SG_ 778 RSDS_RiTgt_02_dx "fuel,ev";
BA_ "GenSigCycleTime" SG_ 778 RSDS_RiTgt_02_dy 200;
BA_ "Match" SG_ 778 RSDS_RiTgt_02_dy "RSDS_RiTgt_02_dy";
BA_ "Origin" SG_ 778 RSDS_RiTgt_02_dy "fuel,ev";
BA_ "GenSigCycleTime" SG_ 778 RSDS_MidTgt_01 200;
BA_ "Match" SG_ 778 RSDS_MidTgt_01 "RSDS_MidTgt_01";
BA_ "Origin" SG_ 778 RSDS_MidTgt_01 "fuel,ev";
BA_ "GenSigCycleTime" SG_ 778 RSDS_MidTgt_01_dx 200;
BA_ "Match" SG_ 778 RSDS_MidTgt_01_dx "RSDS_MidTgt_01_dx";
BA_ "Origin" SG_ 778 RSDS_MidTgt_01_dx "fuel,ev";
BA_ "GenSigCycleTime" SG_ 778 RSDS_MidTgt_01_dy 200;
BA_ "Match" SG_ 778 RSDS_MidTgt_01_dy "RSDS_MidTgt_01_dy";
BA_ "Origin" SG_ 778 RSDS_MidTgt_01_dy "fuel,ev";
BA_ "GenSigCycleTime" SG_ 778 RSDS_MidTgt_02 200;
BA_ "Match" SG_ 778 RSDS_MidTgt_02 "RSDS_MidTgt_02";
BA_ "Origin" SG_ 778 RSDS_MidTgt_02 "fuel,ev";
BA_ "GenSigCycleTime" SG_ 778 RSDS_MidTgt_02_dx 200;
BA_ "Match" SG_ 778 RSDS_MidTgt_02_dx "RSDS_MidTgt_02_dx";
BA_ "Origin" SG_ 778 RSDS_MidTgt_02_dx "fuel,ev";
BA_ "GenSigCycleTime" SG_ 778 RSDS_MidTgt_02_dy 200;
BA_ "Match" SG_ 778 RSDS_MidTgt_02_dy "RSDS_MidTgt_02_dy";
BA_ "Origin" SG_ 778 RSDS_MidTgt_02_dy "fuel,ev";
BA_ "GenSigSendType" SG_ 51 T_BOX_RemtDoorLockCtrl 2;
BA_ "Match" SG_ 51 T_BOX_RemtDoorLockCtrl "T_BOX_RemtDoorLockCtrl";
BA_ "Origin" SG_ 51 T_BOX_RemtDoorLockCtrl "fuel,ev";
BA_ "GenSigSendType" SG_ 51 T_BOX_AudioMuteReq 2;
BA_ "Match" SG_ 51 T_BOX_AudioMuteReq "T_BOX_AudioMuteReq";
BA_ "Origin" SG_ 51 T_BOX_AudioMuteReq "fuel,ev";
BA_ "GenSigSendType" SG_ 51 T_BOX_PM25AirQLvl 2;
BA_ "GenSigStartValue" SG_ 51 T_BOX_PM25AirQLvl 7;
BA_ "Match" SG_ 51 T_BOX_PM25AirQLvl "T_BOX_PM25AirQLvl";
BA_ "Origin" SG_ 51 T_BOX_PM25AirQLvl "fuel,ev";
BA_ "GenSigSendType" SG_ 51 T_BOX_PM25Dens 2;
BA_ "GenSigStartValue" SG_ 51 T_BOX_PM25Dens 1023;
BA_ "Match" SG_ 51 T_BOX_PM25Dens "T_BOX_PM25Dens";
BA_ "Origin" SG_ 51 T_BOX_PM25Dens "fuel,ev";
BA_ "GenSigSendType" SG_ 51 FreshnessValue_T_BOX_FD1 2;
BA_ "Match" SG_ 51 FreshnessValue_T_BOX_FD1 "FreshnessValue_T_BOX_FD1";
BA_ "Origin" SG_ 51 FreshnessValue_T_BOX_FD1 "fuel,ev";
BA_ "GenSigSendType" SG_ 51 MAC_Check_T_BOX_FD1 2;
BA_ "Match" SG_ 51 MAC_Check_T_BOX_FD1 "MAC_Check_T_BOX_FD1";
BA_ "Origin" SG_ 51 MAC_Check_T_BOX_FD1 "fuel,ev";
BA_ "GenSigCycleTime" SG_ 1001 T_BOX_SysErrSts 1000;
BA_ "Match" SG_ 1001 T_BOX_SysErrSts "T_BOX_SysErrSts";
BA_ "Origin" SG_ 1001 T_BOX_SysErrSts "fuel,ev";
BA_ "GenSigCycleTime" SG_ 1001 T_BOX_SWUpdSts 1000;
BA_ "Match" SG_ 1001 T_BOX_SWUpdSts "T_BOX_SWUpdSts";
BA_ "Origin" SG_ 1001 T_BOX_SWUpdSts "fuel,ev";
BA_ "GenSigCycleTime" SG_ 1001 FreshnessValue_T_BOX_FD3 1000;
BA_ "Match" SG_ 1001 FreshnessValue_T_BOX_FD3 "FreshnessValue_T_BOX_FD3";
BA_ "Origin" SG_ 1001 FreshnessValue_T_BOX_FD3 "fuel,ev";
BA_ "GenSigCycleTime" SG_ 1001 MAC_Check_T_BOX_FD3 1000;
BA_ "Match" SG_ 1001 MAC_Check_T_BOX_FD3 "MAC_Check_T_BOX_FD3";
BA_ "Origin" SG_ 1001 MAC_Check_T_BOX_FD3 "fuel,ev";
BA_ "GenSigSendType" SG_ 481 T_BOX_RemtVideoMonrEnaReq_APP 2;
BA_ "Match" SG_ 481 T_BOX_RemtVideoMonrEnaReq_APP "T_BOX_RemtVideoMonrEnaReq_APP";
BA_ "Origin" SG_ 481 T_BOX_RemtVideoMonrEnaReq_APP "fuel,ev";
BA_ "GenSigCycleTime" SG_ 752 V2X_FCW 100;
BA_ "Match" SG_ 752 V2X_FCW "V2X_FCW";
BA_ "Origin" SG_ 752 V2X_FCW "fuel,ev";
BA_ "GenSigCycleTime" SG_ 752 V2X_BSW 100;
BA_ "Match" SG_ 752 V2X_BSW "V2X_BSW";
BA_ "Origin" SG_ 752 V2X_BSW "fuel,ev";
BA_ "GenSigCycleTime" SG_ 752 V2X_LCW 100;
BA_ "Match" SG_ 752 V2X_LCW "V2X_LCW";
BA_ "Origin" SG_ 752 V2X_LCW "fuel,ev";
BA_ "GenSigCycleTime" SG_ 752 V2X_EBW 100;
BA_ "Match" SG_ 752 V2X_EBW "V2X_EBW";
BA_ "Origin" SG_ 752 V2X_EBW "fuel,ev";
BA_ "GenSigCycleTime" SG_ 752 V2X_ICW 100;
BA_ "Match" SG_ 752 V2X_ICW "V2X_ICW";
BA_ "Origin" SG_ 752 V2X_ICW "fuel,ev";
BA_ "GenSigCycleTime" SG_ 752 V2X_LTA 100;
BA_ "Match" SG_ 752 V2X_LTA "V2X_LTA";
BA_ "Origin" SG_ 752 V2X_LTA "fuel,ev";
BA_ "GenSigCycleTime" SG_ 752 V2X_IVSW 100;
BA_ "Match" SG_ 752 V2X_IVSW "V2X_IVSW";
BA_ "Origin" SG_ 752 V2X_IVSW "fuel,ev";
BA_ "GenSigCycleTime" SG_ 752 V2X_AVW 100;
BA_ "Match" SG_ 752 V2X_AVW "V2X_AVW";
BA_ "Origin" SG_ 752 V2X_AVW "fuel,ev";
BA_ "GenSigCycleTime" SG_ 752 V2X_EVW 100;
BA_ "Match" SG_ 752 V2X_EVW "V2X_EVW";
BA_ "Origin" SG_ 752 V2X_EVW "fuel,ev";
BA_ "GenSigCycleTime" SG_ 752 V2X_DNPW 100;
BA_ "Match" SG_ 752 V2X_DNPW "V2X_DNPW";
BA_ "Origin" SG_ 752 V2X_DNPW "fuel,ev";
BA_ "GenSigCycleTime" SG_ 752 V2X_HLW 100;
BA_ "Match" SG_ 752 V2X_HLW "V2X_HLW";
BA_ "Origin" SG_ 752 V2X_HLW "fuel,ev";
BA_ "GenSigCycleTime" SG_ 752 V2X_TJW 100;
BA_ "Match" SG_ 752 V2X_TJW "V2X_TJW";
BA_ "Origin" SG_ 752 V2X_TJW "fuel,ev";
BA_ "GenSigCycleTime" SG_ 752 V2X_CLW 100;
BA_ "Match" SG_ 752 V2X_CLW "V2X_CLW";
BA_ "Origin" SG_ 752 V2X_CLW "fuel,ev";
BA_ "GenSigCycleTime" SG_ 752 V2X_RLVW 100;
BA_ "Match" SG_ 752 V2X_RLVW "V2X_RLVW";
BA_ "Origin" SG_ 752 V2X_RLVW "fuel,ev";
BA_ "GenSigCycleTime" SG_ 752 V2X_VRUCW 100;
BA_ "Match" SG_ 752 V2X_VRUCW "V2X_VRUCW";
BA_ "Origin" SG_ 752 V2X_VRUCW "fuel,ev";
BA_ "GenSigCycleTime" SG_ 752 V2X_SLW 100;
BA_ "Match" SG_ 752 V2X_SLW "V2X_SLW";
BA_ "Origin" SG_ 752 V2X_SLW "fuel,ev";
BA_ "GenSigCycleTime" SG_ 752 V2X_GLOSA 100;
BA_ "GenSigStartValue" SG_ 752 V2X_GLOSA 255;
BA_ "Match" SG_ 752 V2X_GLOSA "V2X_GLOSA";
BA_ "Origin" SG_ 752 V2X_GLOSA "fuel,ev";
BA_ "GenSigCycleTime" SG_ 752 V2X_SL1_LightTyp 100;
BA_ "Match" SG_ 752 V2X_SL1_LightTyp "V2X_SL1_LightTyp";
BA_ "Origin" SG_ 752 V2X_SL1_LightTyp "fuel,ev";
BA_ "GenSigCycleTime" SG_ 752 V2X_SL1_LightColor 100;
BA_ "Match" SG_ 752 V2X_SL1_LightColor "V2X_SL1_LightColor";
BA_ "Origin" SG_ 752 V2X_SL1_LightColor "fuel,ev";
BA_ "GenSigCycleTime" SG_ 752 V2X_SL1_LightTim 100;
BA_ "Match" SG_ 752 V2X_SL1_LightTim "V2X_SL1_LightTim";
BA_ "Origin" SG_ 752 V2X_SL1_LightTim "fuel,ev";
BA_ "GenSigCycleTime" SG_ 752 V2X_SL2_LightTyp 100;
BA_ "Match" SG_ 752 V2X_SL2_LightTyp "V2X_SL2_LightTyp";
BA_ "Origin" SG_ 752 V2X_SL2_LightTyp "fuel,ev";
BA_ "GenSigCycleTime" SG_ 752 V2X_SL2_LightColor 100;
BA_ "Match" SG_ 752 V2X_SL2_LightColor "V2X_SL2_LightColor";
BA_ "Origin" SG_ 752 V2X_SL2_LightColor "fuel,ev";
BA_ "GenSigCycleTime" SG_ 752 V2X_SL2_LightTim 100;
BA_ "Match" SG_ 752 V2X_SL2_LightTim "V2X_SL2_LightTim";
BA_ "Origin" SG_ 752 V2X_SL2_LightTim "fuel,ev";
BA_ "GenSigCycleTime" SG_ 752 V2X_SL3_LightTyp 100;
BA_ "Match" SG_ 752 V2X_SL3_LightTyp "V2X_SL3_LightTyp";
BA_ "Origin" SG_ 752 V2X_SL3_LightTyp "fuel,ev";
BA_ "GenSigCycleTime" SG_ 752 V2X_SL3_LightColor 100;
BA_ "Match" SG_ 752 V2X_SL3_LightColor "V2X_SL3_LightColor";
BA_ "Origin" SG_ 752 V2X_SL3_LightColor "fuel,ev";
BA_ "GenSigCycleTime" SG_ 752 V2X_SL3_LightTim 100;
BA_ "Match" SG_ 752 V2X_SL3_LightTim "V2X_SL3_LightTim";
BA_ "Origin" SG_ 752 V2X_SL3_LightTim "fuel,ev";
BA_ "GenSigCycleTime" SG_ 752 V2X_SL4_LightTyp 100;
BA_ "Match" SG_ 752 V2X_SL4_LightTyp "V2X_SL4_LightTyp";
BA_ "Origin" SG_ 752 V2X_SL4_LightTyp "fuel,ev";
BA_ "GenSigCycleTime" SG_ 752 V2X_SL4_LightColor 100;
BA_ "Match" SG_ 752 V2X_SL4_LightColor "V2X_SL4_LightColor";
BA_ "Origin" SG_ 752 V2X_SL4_LightColor "fuel,ev";
BA_ "GenSigCycleTime" SG_ 752 V2X_SL5_LightTyp 100;
BA_ "Match" SG_ 752 V2X_SL5_LightTyp "V2X_SL5_LightTyp";
BA_ "Origin" SG_ 752 V2X_SL5_LightTyp "fuel,ev";
BA_ "GenSigCycleTime" SG_ 752 V2X_SL4_LightTim 100;
BA_ "Match" SG_ 752 V2X_SL4_LightTim "V2X_SL4_LightTim";
BA_ "Origin" SG_ 752 V2X_SL4_LightTim "fuel,ev";
BA_ "GenSigCycleTime" SG_ 752 V2X_SL5_LightColor 100;
BA_ "Match" SG_ 752 V2X_SL5_LightColor "V2X_SL5_LightColor";
BA_ "Origin" SG_ 752 V2X_SL5_LightColor "fuel,ev";
BA_ "GenSigCycleTime" SG_ 752 V2X_SL5_LightTim 100;
BA_ "Match" SG_ 752 V2X_SL5_LightTim "V2X_SL5_LightTim";
BA_ "Origin" SG_ 752 V2X_SL5_LightTim "fuel,ev";
BA_ "GenSigCycleTime" SG_ 752 V2X_SL6_LightTyp 100;
BA_ "Match" SG_ 752 V2X_SL6_LightTyp "V2X_SL6_LightTyp";
BA_ "Origin" SG_ 752 V2X_SL6_LightTyp "fuel,ev";
BA_ "GenSigCycleTime" SG_ 752 V2X_SL6_LightColor 100;
BA_ "Match" SG_ 752 V2X_SL6_LightColor "V2X_SL6_LightColor";
BA_ "Origin" SG_ 752 V2X_SL6_LightColor "fuel,ev";
BA_ "GenSigCycleTime" SG_ 752 V2X_SL6_LightTim 100;
BA_ "Match" SG_ 752 V2X_SL6_LightTim "V2X_SL6_LightTim";
BA_ "Origin" SG_ 752 V2X_SL6_LightTim "fuel,ev";
BA_ "GenSigCycleTime" SG_ 752 V2X_SL7_LightTyp 100;
BA_ "Match" SG_ 752 V2X_SL7_LightTyp "V2X_SL7_LightTyp";
BA_ "Origin" SG_ 752 V2X_SL7_LightTyp "fuel,ev";
BA_ "GenSigCycleTime" SG_ 752 V2X_SL7_LightColor 100;
BA_ "Match" SG_ 752 V2X_SL7_LightColor "V2X_SL7_LightColor";
BA_ "Origin" SG_ 752 V2X_SL7_LightColor "fuel,ev";
BA_ "GenSigCycleTime" SG_ 752 V2X_SL7_LightTim 100;
BA_ "Match" SG_ 752 V2X_SL7_LightTim "V2X_SL7_LightTim";
BA_ "Origin" SG_ 752 V2X_SL7_LightTim "fuel,ev";
BA_ "GenSigCycleTime" SG_ 752 V2X_SL8_LightTyp 100;
BA_ "Match" SG_ 752 V2X_SL8_LightTyp "V2X_SL8_LightTyp";
BA_ "Origin" SG_ 752 V2X_SL8_LightTyp "fuel,ev";
BA_ "GenSigCycleTime" SG_ 752 V2X_SL8_LightColor 100;
BA_ "Match" SG_ 752 V2X_SL8_LightColor "V2X_SL8_LightColor";
BA_ "Origin" SG_ 752 V2X_SL8_LightColor "fuel,ev";
BA_ "GenSigCycleTime" SG_ 752 V2X_SL8_LightTim 100;
BA_ "Match" SG_ 752 V2X_SL8_LightTim "V2X_SL8_LightTim";
BA_ "Origin" SG_ 752 V2X_SL8_LightTim "fuel,ev";
BA_ "GenSigCycleTime" SG_ 752 V2X_SL_of_Veh 100;
BA_ "Match" SG_ 752 V2X_SL_of_Veh "V2X_SL_of_Veh";
BA_ "Origin" SG_ 752 V2X_SL_of_Veh "fuel,ev";
BA_ "GenSigCycleTime" SG_ 593 FuncProtnSts 20;
BA_ "Match" SG_ 593 FuncProtnSts "FuncProtnSts";
BA_ "Origin" SG_ 593 FuncProtnSts "fuel,ev";
BA_ "GenSigCycleTime" SG_ 593 ShiftSysStuInLow 20;
BA_ "Match" SG_ 593 ShiftSysStuInLow "ShiftSysStuInLow";
BA_ "Origin" SG_ 593 ShiftSysStuInLow "fuel,ev";
BA_ "GenSigCycleTime" SG_ 593 SystemOperMod 20;
BA_ "Match" SG_ 593 SystemOperMod "SystemOperMod";
BA_ "Origin" SG_ 593 SystemOperMod "fuel,ev";
BA_ "GenSigCycleTime" SG_ 593 CouplingFaultSts 20;
BA_ "Match" SG_ 593 CouplingFaultSts "CouplingFaultSts";
BA_ "Origin" SG_ 593 CouplingFaultSts "fuel,ev";
BA_ "GenSigCycleTime" SG_ 593 CouplingThermWarning 20;
BA_ "Match" SG_ 593 CouplingThermWarning "CouplingThermWarning";
BA_ "Origin" SG_ 593 CouplingThermWarning "fuel,ev";
BA_ "GenSigCycleTime" SG_ 593 DiagLmpReq 20;
BA_ "Match" SG_ 593 DiagLmpReq "DiagLmpReq";
BA_ "Origin" SG_ 593 DiagLmpReq "fuel,ev";
BA_ "GenSigCycleTime" SG_ 593 ModeShiftTimeout 20;
BA_ "Match" SG_ 593 ModeShiftTimeout "ModeShiftTimeout";
BA_ "Origin" SG_ 593 ModeShiftTimeout "fuel,ev";
BA_ "GenSigCycleTime" SG_ 593 AutoShiftSts 20;
BA_ "Match" SG_ 593 AutoShiftSts "AutoShiftSts";
BA_ "Origin" SG_ 593 AutoShiftSts "fuel,ev";
BA_ "GenSigCycleTime" SG_ 593 EstimatedTorque 20;
BA_ "Match" SG_ 593 EstimatedTorque "EstimatedTorque";
BA_ "Origin" SG_ 593 EstimatedTorque "fuel,ev";
BA_ "GenSigCycleTime" SG_ 833 FLTirePressIndSts 500;
BA_ "Match" SG_ 833 FLTirePressIndSts "FLTirePressIndSts";
BA_ "Origin" SG_ 833 FLTirePressIndSts "fuel,ev";
BA_ "GenSigCycleTime" SG_ 833 FRTirePressIndSts 500;
BA_ "Match" SG_ 833 FRTirePressIndSts "FRTirePressIndSts";
BA_ "Origin" SG_ 833 FRTirePressIndSts "fuel,ev";
BA_ "GenSigCycleTime" SG_ 833 TirePressSysFailrIndcn 500;
BA_ "Match" SG_ 833 TirePressSysFailrIndcn "TirePressSysFailrIndcn";
BA_ "Origin" SG_ 833 TirePressSysFailrIndcn "fuel,ev";
BA_ "GenSigCycleTime" SG_ 833 RLTirePressIndSts 500;
BA_ "Match" SG_ 833 RLTirePressIndSts "RLTirePressIndSts";
BA_ "Origin" SG_ 833 RLTirePressIndSts "fuel,ev";
BA_ "GenSigCycleTime" SG_ 833 RRTirePressIndSts 500;
BA_ "Match" SG_ 833 RRTirePressIndSts "RRTirePressIndSts";
BA_ "Origin" SG_ 833 RRTirePressIndSts "fuel,ev";
BA_ "GenSigCycleTime" SG_ 833 FLTireTempSts 500;
BA_ "Match" SG_ 833 FLTireTempSts "FLTireTempSts";
BA_ "Origin" SG_ 833 FLTireTempSts "fuel,ev";
BA_ "GenSigCycleTime" SG_ 833 FRTireTempSts 500;
BA_ "Match" SG_ 833 FRTireTempSts "FRTireTempSts";
BA_ "Origin" SG_ 833 FRTireTempSts "fuel,ev";
BA_ "GenSigCycleTime" SG_ 833 RLTireTempSts 500;
BA_ "Match" SG_ 833 RLTireTempSts "RLTireTempSts";
BA_ "Origin" SG_ 833 RLTireTempSts "fuel,ev";
BA_ "GenSigCycleTime" SG_ 833 RRTireTempSts 500;
BA_ "Match" SG_ 833 RRTireTempSts "RRTireTempSts";
BA_ "Origin" SG_ 833 RRTireTempSts "fuel,ev";
BA_ "GenSigCycleTime" SG_ 833 FreshnessValue_TPMS1 500;
BA_ "Match" SG_ 833 FreshnessValue_TPMS1 "FreshnessValue_TPMS1";
BA_ "Origin" SG_ 833 FreshnessValue_TPMS1 "fuel,ev";
BA_ "GenSigCycleTime" SG_ 833 MAC_Check_TPMS1 500;
BA_ "Match" SG_ 833 MAC_Check_TPMS1 "MAC_Check_TPMS1";
BA_ "Origin" SG_ 833 MAC_Check_TPMS1 "fuel,ev";
BA_ "GenSigCycleTime" SG_ 917 FLTirePress 500;
BA_ "Match" SG_ 917 FLTirePress "FLTirePress";
BA_ "Origin" SG_ 917 FLTirePress "fuel,ev";
BA_ "GenSigCycleTime" SG_ 917 FLTireTemp 500;
BA_ "Match" SG_ 917 FLTireTemp "FLTireTemp";
BA_ "Origin" SG_ 917 FLTireTemp "fuel,ev";
BA_ "GenSigCycleTime" SG_ 917 FRTirePress 500;
BA_ "Match" SG_ 917 FRTirePress "FRTirePress";
BA_ "Origin" SG_ 917 FRTirePress "fuel,ev";
BA_ "GenSigCycleTime" SG_ 917 FRTireTemp 500;
BA_ "Match" SG_ 917 FRTireTemp "FRTireTemp";
BA_ "Origin" SG_ 917 FRTireTemp "fuel,ev";
BA_ "GenSigCycleTime" SG_ 917 RLTirePress 500;
BA_ "Match" SG_ 917 RLTirePress "RLTirePress";
BA_ "Origin" SG_ 917 RLTirePress "fuel,ev";
BA_ "GenSigCycleTime" SG_ 917 RLTireTemp 500;
BA_ "Match" SG_ 917 RLTireTemp "RLTireTemp";
BA_ "Origin" SG_ 917 RLTireTemp "fuel,ev";
BA_ "GenSigCycleTime" SG_ 917 RRTirePress 500;
BA_ "Match" SG_ 917 RRTirePress "RRTirePress";
BA_ "Origin" SG_ 917 RRTirePress "fuel,ev";
BA_ "GenSigCycleTime" SG_ 917 RRTireTemp 500;
BA_ "Match" SG_ 917 RRTireTemp "RRTireTemp";
BA_ "Origin" SG_ 917 RRTireTemp "fuel,ev";
BA_ "GenSigCycleTime" SG_ 917 FreshnessValue_TPMS2 500;
BA_ "Match" SG_ 917 FreshnessValue_TPMS2 "FreshnessValue_TPMS2";
BA_ "Origin" SG_ 917 FreshnessValue_TPMS2 "fuel,ev";
BA_ "GenSigCycleTime" SG_ 917 MAC_Check_TPMS2 500;
BA_ "Match" SG_ 917 MAC_Check_TPMS2 "MAC_Check_TPMS2";
BA_ "Origin" SG_ 917 MAC_Check_TPMS2 "fuel,ev";
BA_ "GenSigCycleTime" SG_ 627 TrailerSts 50;
BA_ "Match" SG_ 627 TrailerSts "TrailerSts";
BA_ "Origin" SG_ 627 TrailerSts "fuel,ev";
BA_ "GenSigCycleTime" SG_ 698 WPC_ChrgSts 100;
BA_ "Match" SG_ 698 WPC_ChrgSts "WPC_ChrgSts";
BA_ "Origin" SG_ 698 WPC_ChrgSts "fuel,ev";
BA_ "GenSigCycleTime" SG_ 698 WPC_SwtSts 100;
BA_ "Match" SG_ 698 WPC_SwtSts "WPC_SwtSts";
BA_ "Origin" SG_ 698 WPC_SwtSts "fuel,ev";
BA_ "GenSigCycleTime" SG_ 698 WPC_FaultSts 100;
BA_ "Match" SG_ 698 WPC_FaultSts "WPC_FaultSts";
BA_ "Origin" SG_ 698 WPC_FaultSts "fuel,ev";
BA_ "GenSigCycleTime" SG_ 698 WPC_PhoneReminder 100;
BA_ "Match" SG_ 698 WPC_PhoneReminder "WPC_PhoneReminder";
BA_ "Origin" SG_ 698 WPC_PhoneReminder "fuel,ev";
BA_ "GenSigCycleTime" SG_ 785 DOCK_ExternalDevice_P 200;
BA_ "Match" SG_ 785 DOCK_ExternalDevice_P "DOCK_ExternalDevice_P";
BA_ "Origin" SG_ 785 DOCK_ExternalDevice_P "fuel,ev";
BA_ "GenSigSendType" SG_ 479 DOCK_HUT_ExternalDevice_E 2;
BA_ "Match" SG_ 479 DOCK_HUT_ExternalDevice_E "DOCK_HUT_ExternalDevice_E";
BA_ "Origin" SG_ 479 DOCK_HUT_ExternalDevice_E "fuel,ev";
BA_ "GenSigCycleTime" SG_ 718 DrvSeatMassLvlSetSts 100;
BA_ "Match" SG_ 718 DrvSeatMassLvlSetSts "DrvSeatMassLvlSetSts";
BA_ "Origin" SG_ 718 DrvSeatMassLvlSetSts "fuel,ev";
BA_ "GenSigCycleTime" SG_ 718 DrvSeatMassModeSts 100;
BA_ "Match" SG_ 718 DrvSeatMassModeSts "DrvSeatMassModeSts";
BA_ "Origin" SG_ 718 DrvSeatMassModeSts "fuel,ev";
BA_ "GenSigCycleTime" SG_ 718 PassSeatMassgLvlSetSts 100;
BA_ "Match" SG_ 718 PassSeatMassgLvlSetSts "PassSeatMassgLvlSetSts";
BA_ "Origin" SG_ 718 PassSeatMassgLvlSetSts "fuel,ev";
BA_ "GenSigCycleTime" SG_ 718 RLSeatMassgLvlSetSts 100;
BA_ "Match" SG_ 718 RLSeatMassgLvlSetSts "RLSeatMassgLvlSetSts";
BA_ "Origin" SG_ 718 RLSeatMassgLvlSetSts "fuel,ev";
BA_ "GenSigCycleTime" SG_ 718 RRSeatMassgLvlSetSts 100;
BA_ "Match" SG_ 718 RRSeatMassgLvlSetSts "RRSeatMassgLvlSetSts";
BA_ "Origin" SG_ 718 RRSeatMassgLvlSetSts "fuel,ev";
BA_ "GenSigCycleTime" SG_ 718 PassSeatMassgModeSts 100;
BA_ "Match" SG_ 718 PassSeatMassgModeSts "PassSeatMassgModeSts";
BA_ "Origin" SG_ 718 PassSeatMassgModeSts "fuel,ev";
BA_ "GenSigCycleTime" SG_ 718 RLSeatMassgModSts 100;
BA_ "Match" SG_ 718 RLSeatMassgModSts "RLSeatMassgModSts";
BA_ "Origin" SG_ 718 RLSeatMassgModSts "fuel,ev";
BA_ "GenSigCycleTime" SG_ 718 RRSeatMassgModSts 100;
BA_ "Match" SG_ 718 RRSeatMassgModSts "RRSeatMassgModSts";
BA_ "Origin" SG_ 718 RRSeatMassgModSts "fuel,ev";
BA_ "GenSigCycleTime" SG_ 604 BLEConnSts 50;
BA_ "Match" SG_ 604 BLEConnSts "BLEConnSts";
BA_ "Origin" SG_ 604 BLEConnSts "fuel,ev";
BA_ "GenSigCycleTime" SG_ 604 BLESecuritySts 50;
BA_ "Match" SG_ 604 BLESecuritySts "BLESecuritySts";
BA_ "Origin" SG_ 604 BLESecuritySts "fuel,ev";
BA_ "GenSigSendType" SG_ 506 BLE_BeanID 2;
BA_ "Match" SG_ 506 BLE_BeanID "BLE_BeanID";
BA_ "Origin" SG_ 506 BLE_BeanID "fuel,ev";
BA_ "GenSigSendType" SG_ 473 OTA_UpgrdModErrCode 2;
BA_ "Match" SG_ 473 OTA_UpgrdModErrCode "OTA_UpgrdModErrCode";
BA_ "Origin" SG_ 473 OTA_UpgrdModErrCode "fuel,ev";
BA_ "GenSigCycleTime" SG_ 721 DrvSeatVentnSts 100;
BA_ "Match" SG_ 721 DrvSeatVentnSts "DrvSeatVentnSts";
BA_ "Origin" SG_ 721 DrvSeatVentnSts "fuel,ev";
BA_ "GenSigCycleTime" SG_ 721 PassSeatVentnSts 100;
BA_ "Match" SG_ 721 PassSeatVentnSts "PassSeatVentnSts";
BA_ "Origin" SG_ 721 PassSeatVentnSts "fuel,ev";
BA_ "GenSigSendType" SG_ 497 AntiDisIdnRndNumber 2;
BA_ "Match" SG_ 497 AntiDisIdnRndNumber "AntiDisIdnRndNumber";
BA_ "Origin" SG_ 497 AntiDisIdnRndNumber "fuel,ev";
BA_ "GenSigCycleTime" SG_ 836 AntiDisIdnResult 500;
BA_ "GenSigStartValue" SG_ 836 AntiDisIdnResult 2;
BA_ "Match" SG_ 836 AntiDisIdnResult "AntiDisIdnResult";
BA_ "Origin" SG_ 836 AntiDisIdnResult "fuel,ev";
BA_ "GenSigCycleTime" SG_ 836 SelfChkSts 500;
BA_ "GenSigStartValue" SG_ 836 SelfChkSts 2;
BA_ "Match" SG_ 836 SelfChkSts "SelfChkSts";
BA_ "Origin" SG_ 836 SelfChkSts "fuel,ev";
BA_ "GenSigCycleTime" SG_ 836 ActvdSts 500;
BA_ "GenSigStartValue" SG_ 836 ActvdSts 2;
BA_ "Match" SG_ 836 ActvdSts "ActvdSts";
BA_ "Origin" SG_ 836 ActvdSts "fuel,ev";
BA_ "GenSigSendType" SG_ 498 TransSts 2;
BA_ "Match" SG_ 498 TransSts "TransSts";
BA_ "Origin" SG_ 498 TransSts "fuel,ev";
BA_ "GenSigSendType" SG_ 498 EntrAndExitCdn 2;
BA_ "Match" SG_ 498 EntrAndExitCdn "EntrAndExitCdn";
BA_ "Origin" SG_ 498 EntrAndExitCdn "fuel,ev";
BA_ "GenSigSendType" SG_ 498 TransAmnt 2;
BA_ "Match" SG_ 498 TransAmnt "TransAmnt";
BA_ "Origin" SG_ 498 TransAmnt "fuel,ev";
BA_ "GenSigCycleTime" SG_ 776 LHiBeamSts 200;
BA_ "Match" SG_ 776 LHiBeamSts "LHiBeamSts";
BA_ "Origin" SG_ 776 LHiBeamSts "fuel,ev";
BA_ "GenSigCycleTime" SG_ 776 LHiBeamFailSts_HCM 200;
BA_ "Match" SG_ 776 LHiBeamFailSts_HCM "LHiBeamFailSts_HCM";
BA_ "Origin" SG_ 776 LHiBeamFailSts_HCM "fuel,ev";
BA_ "GenSigCycleTime" SG_ 776 LLowBeamSts 200;
BA_ "Match" SG_ 776 LLowBeamSts "LLowBeamSts";
BA_ "Origin" SG_ 776 LLowBeamSts "fuel,ev";
BA_ "GenSigCycleTime" SG_ 776 LLowBeamFailSts_HCM 200;
BA_ "Match" SG_ 776 LLowBeamFailSts_HCM "LLowBeamFailSts_HCM";
BA_ "Origin" SG_ 776 LLowBeamFailSts_HCM "fuel,ev";
BA_ "GenSigCycleTime" SG_ 772 Checksum_HCM_L2 200;
BA_ "Match" SG_ 772 Checksum_HCM_L2 "Checksum_HCM_L2";
BA_ "Origin" SG_ 772 Checksum_HCM_L2 "fuel,ev";
BA_ "GenSigCycleTime" SG_ 772 LeftLightShowSts 200;
BA_ "Match" SG_ 772 LeftLightShowSts "LeftLightShowSts";
BA_ "Origin" SG_ 772 LeftLightShowSts "fuel,ev";
BA_ "GenSigCycleTime" SG_ 772 FLMusicLightShowSts 200;
BA_ "Match" SG_ 772 FLMusicLightShowSts "FLMusicLightShowSts";
BA_ "Origin" SG_ 772 FLMusicLightShowSts "fuel,ev";
BA_ "GenSigCycleTime" SG_ 772 RollingCounter_HCM_L2 200;
BA_ "Match" SG_ 772 RollingCounter_HCM_L2 "RollingCounter_HCM_L2";
BA_ "Origin" SG_ 772 RollingCounter_HCM_L2 "fuel,ev";
BA_ "GenSigCycleTime" SG_ 781 RHiBeamSts 200;
BA_ "Match" SG_ 781 RHiBeamSts "RHiBeamSts";
BA_ "Origin" SG_ 781 RHiBeamSts "fuel,ev";
BA_ "GenSigCycleTime" SG_ 781 RHiBeamFailSts_HCM 200;
BA_ "Match" SG_ 781 RHiBeamFailSts_HCM "RHiBeamFailSts_HCM";
BA_ "Origin" SG_ 781 RHiBeamFailSts_HCM "fuel,ev";
BA_ "GenSigCycleTime" SG_ 781 RLowBeamSts 200;
BA_ "Match" SG_ 781 RLowBeamSts "RLowBeamSts";
BA_ "Origin" SG_ 781 RLowBeamSts "fuel,ev";
BA_ "GenSigCycleTime" SG_ 781 RLowBeamFailSts_HCM 200;
BA_ "Match" SG_ 781 RLowBeamFailSts_HCM "RLowBeamFailSts_HCM";
BA_ "Origin" SG_ 781 RLowBeamFailSts_HCM "fuel,ev";
BA_ "GenSigCycleTime" SG_ 816 Checksum_HCM_R2 200;
BA_ "Match" SG_ 816 Checksum_HCM_R2 "Checksum_HCM_R2";
BA_ "Origin" SG_ 816 Checksum_HCM_R2 "fuel,ev";
BA_ "GenSigCycleTime" SG_ 816 RightLightShowSts 200;
BA_ "Match" SG_ 816 RightLightShowSts "RightLightShowSts";
BA_ "Origin" SG_ 816 RightLightShowSts "fuel,ev";
BA_ "GenSigCycleTime" SG_ 816 FRMusicLightShowSts 200;
BA_ "Match" SG_ 816 FRMusicLightShowSts "FRMusicLightShowSts";
BA_ "Origin" SG_ 816 FRMusicLightShowSts "fuel,ev";
BA_ "GenSigCycleTime" SG_ 816 RollingCounter_HCM_R2 200;
BA_ "Match" SG_ 816 RollingCounter_HCM_R2 "RollingCounter_HCM_R2";
BA_ "Origin" SG_ 816 RollingCounter_HCM_R2 "fuel,ev";
BA_ "GenSigCycleTime" SG_ 647 CheckSum_HC1 100;
BA_ "Match" SG_ 647 CheckSum_HC1 "CheckSum_HC1";
BA_ "Origin" SG_ 647 CheckSum_HC1 "fuel,ev";
BA_ "GenSigCycleTime" SG_ 647 ALS_FailSts 100;
BA_ "Match" SG_ 647 ALS_FailSts "ALS_FailSts";
BA_ "Origin" SG_ 647 ALS_FailSts "fuel,ev";
BA_ "GenSigCycleTime" SG_ 647 RollingCounter_HC1 100;
BA_ "Match" SG_ 647 RollingCounter_HC1 "RollingCounter_HC1";
BA_ "Origin" SG_ 647 RollingCounter_HC1 "fuel,ev";
BA_ "GenSigCycleTime" SG_ 818 RFLLightShowSts 200;
BA_ "Match" SG_ 818 RFLLightShowSts "RFLLightShowSts";
BA_ "Origin" SG_ 818 RFLLightShowSts "fuel,ev";
BA_ "GenSigCycleTime" SG_ 819 RFRLightShowSts 200;
BA_ "Match" SG_ 819 RFRLightShowSts "RFRLightShowSts";
BA_ "Origin" SG_ 819 RFRLightShowSts "fuel,ev";
BA_ "Match" SG_ 1888 DiagFuncReq "DiagFuncReq";
BA_ "Origin" SG_ 1888 DiagFuncReq "fuel,ev";
BA_ "Match" SG_ 1889 GW_Phy_Req "GW_Phy_Req";
BA_ "Origin" SG_ 1889 GW_Phy_Req "fuel,ev";
BA_ "Match" SG_ 1918 T_Box_Phy_Req "T_Box_Phy_Req";
BA_ "Origin" SG_ 1918 T_Box_Phy_Req "fuel,ev";
BA_ "Match" SG_ 1843 XBOX_D_Phy_Req "XBOX_D_Phy_Req";
BA_ "Origin" SG_ 1843 XBOX_D_Phy_Req "fuel,ev";
BA_ "Match" SG_ 1907 HUT_Phy_Req "HUT_Phy_Req";
BA_ "Origin" SG_ 1907 HUT_Phy_Req "fuel,ev";
BA_ "Match" SG_ 1953 GW_Phy_Resp "GW_Phy_Resp";
BA_ "Origin" SG_ 1953 GW_Phy_Resp "fuel,ev";
BA_ "Match" SG_ 1982 T_Box_Phy_Resp "T_Box_Phy_Resp";
BA_ "Origin" SG_ 1982 T_Box_Phy_Resp "fuel,ev";
BA_ "Match" SG_ 1844 XBOX_D_Phy_Resp "XBOX_D_Phy_Resp";
BA_ "Origin" SG_ 1844 XBOX_D_Phy_Resp "fuel,ev";
BA_ "Match" SG_ 1971 HUT_Phy_Resp "HUT_Phy_Resp";
BA_ "Origin" SG_ 1971 HUT_Phy_Resp "fuel,ev";
BA_ "Match" SG_ 1290 Destination_T_Box_NM "Destination_T_Box_NM";
BA_ "Origin" SG_ 1290 Destination_T_Box_NM "fuel,ev";
BA_ "Match" SG_ 1290 OpCode_T_Box_NM "OpCode_T_Box_NM";
BA_ "Origin" SG_ 1290 OpCode_T_Box_NM "fuel,ev";
BA_ "Match" SG_ 1289 Destination_HUT_NM "Destination_HUT_NM";
BA_ "Origin" SG_ 1289 Destination_HUT_NM "fuel,ev";
BA_ "Match" SG_ 1289 OpCode_HUT_NM "OpCode_HUT_NM";
BA_ "Origin" SG_ 1289 OpCode_HUT_NM "fuel,ev";
BA_ "Match" SG_ 1334 Destination_XBOX_D_NM "Destination_XBOX_D_NM";
BA_ "Origin" SG_ 1334 Destination_XBOX_D_NM "fuel,ev";
BA_ "Match" SG_ 1334 OpCode_XBOX_D_NM "OpCode_XBOX_D_NM";
BA_ "Origin" SG_ 1334 OpCode_XBOX_D_NM "fuel,ev";
BA_ "Match" SG_ 1281 Destination_CEM_NM "Destination_CEM_NM";
BA_ "Origin" SG_ 1281 Destination_CEM_NM "fuel,ev";
BA_ "Match" SG_ 1281 OpCode_CEM_NM "OpCode_CEM_NM";
BA_ "Origin" SG_ 1281 OpCode_CEM_NM "fuel,ev";
BA_ "GenSigSendType" SG_ 1122 SyncRequestMessageId 2;
BA_ "Match" SG_ 1122 SyncRequestMessageId "SyncRequestMessageId";
BA_ "Origin" SG_ 1122 SyncRequestMessageId "fuel,ev";
BA_ "GenSigSendType" SG_ 1122 SyncRequstReseverData 2;
BA_ "Match" SG_ 1122 SyncRequstReseverData "SyncRequstReseverData";
BA_ "Origin" SG_ 1122 SyncRequstReseverData "fuel,ev";
BA_ "Match" SG_ 1121 ResetCount "ResetCount";
BA_ "Origin" SG_ 1121 ResetCount "fuel,ev";
BA_ "Match" SG_ 1121 CMACMessageInfo "CMACMessageInfo";
BA_ "Origin" SG_ 1121 CMACMessageInfo "fuel,ev";
BA_ "Match" SG_ 1121 TripCount "TripCount";
BA_ "Origin" SG_ 1121 TripCount "fuel,ev";
BA_ "GenSigSendType" SG_ 483 BMS_ChrgTimResp 2;
BA_ "Match" SG_ 483 BMS_ChrgTimResp "BMS_ChrgTimResp";
BA_ "Origin" SG_ 483 BMS_ChrgTimResp "ev";
BA_ "GenSigCycleTime" SG_ 850 BMS_IntelEngIdlChrgnSts 500;
BA_ "Match" SG_ 850 BMS_IntelEngIdlChrgnSts "BMS_IntelEngIdlChrgnSts";
BA_ "Origin" SG_ 850 BMS_IntelEngIdlChrgnSts "ev";
BA_ "GenSigCycleTime" SG_ 850 BMS_BattKeepTempSts 500;
BA_ "Match" SG_ 850 BMS_BattKeepTempSts "BMS_BattKeepTempSts";
BA_ "Origin" SG_ 850 BMS_BattKeepTempSts "ev";
BA_ "GenSigCycleTime" SG_ 959 BMS_ChrgDurationTime 1000;
BA_ "Match" SG_ 959 BMS_ChrgDurationTime "BMS_ChrgDurationTime";
BA_ "Origin" SG_ 959 BMS_ChrgDurationTime "ev";
BA_ "GenSigCycleTime" SG_ 1009 BMS_SOCLowWarn 1000;
BA_ "Match" SG_ 1009 BMS_SOCLowWarn "BMS_SOCLowWarn";
BA_ "Origin" SG_ 1009 BMS_SOCLowWarn "ev";
BA_ "GenSigCycleTime" SG_ 942 BMS_SocJumpWarn_RM 1000;
BA_ "Match" SG_ 942 BMS_SocJumpWarn_RM "BMS_SocJumpWarn_RM";
BA_ "Origin" SG_ 942 BMS_SocJumpWarn_RM "ev";
BA_ "GenSigCycleTime" SG_ 942 BMS_PackOverChrgWarn_RM 1000;
BA_ "Match" SG_ 942 BMS_PackOverChrgWarn_RM "BMS_PackOverChrgWarn_RM";
BA_ "Origin" SG_ 942 BMS_PackOverChrgWarn_RM "ev";
BA_ "GenSigCycleTime" SG_ 942 BMS_ChrgSts_RM 1000;
BA_ "GenSigStartValue" SG_ 942 BMS_ChrgSts_RM 1;
BA_ "Match" SG_ 942 BMS_ChrgSts_RM "BMS_ChrgSts_RM";
BA_ "Origin" SG_ 942 BMS_ChrgSts_RM "ev";
BA_ "GenSigCycleTime" SG_ 942 BMS_IsolationRValue_RM 1000;
BA_ "GenSigStartValue" SG_ 942 BMS_IsolationRValue_RM 10000;
BA_ "Match" SG_ 942 BMS_IsolationRValue_RM "BMS_IsolationRValue_RM";
BA_ "Origin" SG_ 942 BMS_IsolationRValue_RM "ev";
BA_ "GenSigCycleTime" SG_ 942 BMS_PackCurr_RM 1000;
BA_ "Match" SG_ 942 BMS_PackCurr_RM "BMS_PackCurr_RM";
BA_ "Origin" SG_ 942 BMS_PackCurr_RM "ev";
BA_ "GenSigCycleTime" SG_ 942 BMS_SocOverWarn_RM 1000;
BA_ "Match" SG_ 942 BMS_SocOverWarn_RM "BMS_SocOverWarn_RM";
BA_ "Origin" SG_ 942 BMS_SocOverWarn_RM "ev";
BA_ "GenSigCycleTime" SG_ 942 BMS_BattOverTempRank_RM 1000;
BA_ "Match" SG_ 942 BMS_BattOverTempRank_RM "BMS_BattOverTempRank_RM";
BA_ "Origin" SG_ 942 BMS_BattOverTempRank_RM "ev";
BA_ "GenSigCycleTime" SG_ 942 BMS_BattOverVoltRank_RM 1000;
BA_ "Match" SG_ 942 BMS_BattOverVoltRank_RM "BMS_BattOverVoltRank_RM";
BA_ "Origin" SG_ 942 BMS_BattOverVoltRank_RM "ev";
BA_ "GenSigCycleTime" SG_ 942 BMS_BattSOCLowRank_RM 1000;
BA_ "Match" SG_ 942 BMS_BattSOCLowRank_RM "BMS_BattSOCLowRank_RM";
BA_ "Origin" SG_ 942 BMS_BattSOCLowRank_RM "ev";
BA_ "GenSigCycleTime" SG_ 942 BMS_VCUIsolateErr_RM 1000;
BA_ "Match" SG_ 942 BMS_VCUIsolateErr_RM "BMS_VCUIsolateErr_RM";
BA_ "Origin" SG_ 942 BMS_VCUIsolateErr_RM "ev";
BA_ "GenSigCycleTime" SG_ 942 BMS_BattUnderVoltRank_RM 1000;
BA_ "Match" SG_ 942 BMS_BattUnderVoltRank_RM "BMS_BattUnderVoltRank_RM";
BA_ "Origin" SG_ 942 BMS_BattUnderVoltRank_RM "ev";
BA_ "GenSigCycleTime" SG_ 942 BMS_CellDeltaVoltRank_RM 1000;
BA_ "Match" SG_ 942 BMS_CellDeltaVoltRank_RM "BMS_CellDeltaVoltRank_RM";
BA_ "Origin" SG_ 942 BMS_CellDeltaVoltRank_RM "ev";
BA_ "GenSigCycleTime" SG_ 942 BMS_CellOverVoltRank_RM 1000;
BA_ "Match" SG_ 942 BMS_CellOverVoltRank_RM "BMS_CellOverVoltRank_RM";
BA_ "Origin" SG_ 942 BMS_CellOverVoltRank_RM "ev";
BA_ "GenSigCycleTime" SG_ 942 BMS_CellUnderVoltRank_RM 1000;
BA_ "Match" SG_ 942 BMS_CellUnderVoltRank_RM "BMS_CellUnderVoltRank_RM";
BA_ "Origin" SG_ 942 BMS_CellUnderVoltRank_RM "ev";
BA_ "GenSigCycleTime" SG_ 942 BMS_DeltaTempRank_RM 1000;
BA_ "Match" SG_ 942 BMS_DeltaTempRank_RM "BMS_DeltaTempRank_RM";
BA_ "Origin" SG_ 942 BMS_DeltaTempRank_RM "ev";
BA_ "GenSigCycleTime" SG_ 942 BMS_PackMismatchWarn_RM 1000;
BA_ "Match" SG_ 942 BMS_PackMismatchWarn_RM "BMS_PackMismatchWarn_RM";
BA_ "Origin" SG_ 942 BMS_PackMismatchWarn_RM "ev";
BA_ "GenSigCycleTime" SG_ 942 BMS_PackVolt_RM 1000;
BA_ "Match" SG_ 942 BMS_PackVolt_RM "BMS_PackVolt_RM";
BA_ "Origin" SG_ 942 BMS_PackVolt_RM "ev";
BA_ "GenSigCycleTime" SG_ 645 BMS_BattHeatRunaway 100;
BA_ "Match" SG_ 645 BMS_BattHeatRunaway "BMS_BattHeatRunaway";
BA_ "Origin" SG_ 645 BMS_BattHeatRunaway "ev";
BA_ "GenSigCycleTime" SG_ 645 BMS_DisSOC1 100;
BA_ "Match" SG_ 645 BMS_DisSOC1 "BMS_DisSOC1";
BA_ "Origin" SG_ 645 BMS_DisSOC1 "ev";
BA_ "GenSigCycleTime" SG_ 142 EngTrqCrankshaftLvl 10;
BA_ "Match" SG_ 142 EngTrqCrankshaftLvl "EngTrqCrankshaftLvl";
BA_ "Origin" SG_ 142 EngTrqCrankshaftLvl "ev";
BA_ "GenSigCycleTime" SG_ 142 EngTrqCrankshaftLvlValid 10;
BA_ "GenSigStartValue" SG_ 142 EngTrqCrankshaftLvlValid 1;
BA_ "Match" SG_ 142 EngTrqCrankshaftLvlValid "EngTrqCrankshaftLvlValid";
BA_ "Origin" SG_ 142 EngTrqCrankshaftLvlValid "ev";
BA_ "GenSigCycleTime" SG_ 279 EngState_PHEV 20;
BA_ "Match" SG_ 279 EngState_PHEV "EngState_PHEV";
BA_ "Origin" SG_ 279 EngState_PHEV "ev";
BA_ "GenSigCycleTime" SG_ 279 CruiseCtrlSts_PHEV 20;
BA_ "Match" SG_ 279 CruiseCtrlSts_PHEV "CruiseCtrlSts_PHEV";
BA_ "Origin" SG_ 279 CruiseCtrlSts_PHEV "ev";
BA_ "GenSigCycleTime" SG_ 96 HCU_AccelPedalPosn_Diag 10;
BA_ "Match" SG_ 96 HCU_AccelPedalPosn_Diag "HCU_AccelPedalPosn_Diag";
BA_ "Origin" SG_ 96 HCU_AccelPedalPosn_Diag "ev";
BA_ "GenSigCycleTime" SG_ 96 HCU_AccelPedalPosn_DiagValid 10;
BA_ "GenSigStartValue" SG_ 96 HCU_AccelPedalPosn_DiagValid 1;
BA_ "Match" SG_ 96 HCU_AccelPedalPosn_DiagValid "HCU_AccelPedalPosn_DiagValid";
BA_ "Origin" SG_ 96 HCU_AccelPedalPosn_DiagValid "ev";
BA_ "GenSigCycleTime" SG_ 96 HCU_PowertrainSts_0x60 10;
BA_ "Match" SG_ 96 HCU_PowertrainSts_0x60 "HCU_PowertrainSts";
BA_ "Origin" SG_ 96 HCU_PowertrainSts_0x60 "ev";
BA_ "GenSigCycleTime" SG_ 96 HCU_RaceLaunchSts_0x60 10;
BA_ "Match" SG_ 96 HCU_RaceLaunchSts_0x60 "HCU_RaceLaunchSts";
BA_ "Origin" SG_ 96 HCU_RaceLaunchSts_0x60 "ev";
BA_ "GenSigCycleTime" SG_ 96 HCU_RaceLaunchAvail_0x60 10;
BA_ "Match" SG_ 96 HCU_RaceLaunchAvail_0x60 "HCU_RaceLaunchAvail";
BA_ "Origin" SG_ 96 HCU_RaceLaunchAvail_0x60 "ev";
BA_ "GenSigCycleTime" SG_ 96 HCU_AccelPedalPosn 10;
BA_ "Match" SG_ 96 HCU_AccelPedalPosn "HCU_AccelPedalPosn";
BA_ "Origin" SG_ 96 HCU_AccelPedalPosn "ev";
BA_ "GenSigCycleTime" SG_ 96 HCU_AccelPedalPosnValid 10;
BA_ "GenSigStartValue" SG_ 96 HCU_AccelPedalPosnValid 1;
BA_ "Match" SG_ 96 HCU_AccelPedalPosnValid "HCU_AccelPedalPosnValid";
BA_ "Origin" SG_ 96 HCU_AccelPedalPosnValid "ev";
BA_ "GenSigCycleTime" SG_ 616 HCU_BattLowTempWarn 50;
BA_ "Match" SG_ 616 HCU_BattLowTempWarn "HCU_BattLowTempWarn";
BA_ "Origin" SG_ 616 HCU_BattLowTempWarn "ev";
BA_ "GenSigCycleTime" SG_ 616 HCU_BattLowTempHeatSts 50;
BA_ "Match" SG_ 616 HCU_BattLowTempHeatSts "HCU_BattLowTempHeatSts";
BA_ "Origin" SG_ 616 HCU_BattLowTempHeatSts "ev";
BA_ "GenSigCycleTime" SG_ 788 HCU_ACLineDisconnect 200;
BA_ "Match" SG_ 788 HCU_ACLineDisconnect "HCU_ACLineDisconnect";
BA_ "Origin" SG_ 788 HCU_ACLineDisconnect "ev";
BA_ "GenSigCycleTime" SG_ 788 HCU_ChargSts 200;
BA_ "Match" SG_ 788 HCU_ChargSts "HCU_ChargSts";
BA_ "Origin" SG_ 788 HCU_ChargSts "ev";
BA_ "GenSigCycleTime" SG_ 788 HCU_IntelBattTempMagSts 200;
BA_ "Match" SG_ 788 HCU_IntelBattTempMagSts "HCU_IntelBattTempMagSts";
BA_ "Origin" SG_ 788 HCU_IntelBattTempMagSts "ev";
BA_ "GenSigSendType" SG_ 482 HCU_TotalScore 2;
BA_ "Match" SG_ 482 HCU_TotalScore "HCU_TotalScore";
BA_ "Origin" SG_ 482 HCU_TotalScore "ev";
BA_ "GenSigCycleTime" SG_ 249 HCU_TrqLimMax_Norm 10;
BA_ "GenSigStartValue" SG_ 249 HCU_TrqLimMax_Norm 275;
BA_ "Match" SG_ 249 HCU_TrqLimMax_Norm "HCU_TrqLimMax_Norm";
BA_ "Origin" SG_ 249 HCU_TrqLimMax_Norm "ev";
BA_ "GenSigCycleTime" SG_ 330 HCUImmoAuthRes 20;
BA_ "Match" SG_ 330 HCUImmoAuthRes "HCUImmoAuthRes";
BA_ "Origin" SG_ 330 HCUImmoAuthRes "ev";
BA_ "GenSigCycleTime" SG_ 330 HCU_EVLmpSts 20;
BA_ "Match" SG_ 330 HCU_EVLmpSts "HCU_EVLmpSts";
BA_ "Origin" SG_ 330 HCU_EVLmpSts "ev";
BA_ "GenSigCycleTime" SG_ 330 HCU_ECODrvHabit_Indcn 20;
BA_ "GenSigStartValue" SG_ 330 HCU_ECODrvHabit_Indcn 100;
BA_ "Match" SG_ 330 HCU_ECODrvHabit_Indcn "HCU_ECODrvHabit_Indcn";
BA_ "Origin" SG_ 330 HCU_ECODrvHabit_Indcn "ev";
BA_ "GenSigCycleTime" SG_ 330 HCU_TotDrvReqPower_0x14a 20;
BA_ "GenSigStartValue" SG_ 330 HCU_TotDrvReqPower_0x14a 100;
BA_ "Match" SG_ 330 HCU_TotDrvReqPower_0x14a "HCU_TotDrvReqPower";
BA_ "Origin" SG_ 330 HCU_TotDrvReqPower_0x14a "ev";
BA_ "GenSigCycleTime" SG_ 330 HCU_AvailPower_TM 20;
BA_ "Match" SG_ 330 HCU_AvailPower_TM "HCU_AvailPower_TM";
BA_ "Origin" SG_ 330 HCU_AvailPower_TM "ev";
BA_ "GenSigCycleTime" SG_ 330 HCU_DrvMod 20;
BA_ "Match" SG_ 330 HCU_DrvMod "HCU_DrvMod";
BA_ "Origin" SG_ 330 HCU_DrvMod "ev";
BA_ "GenSigCycleTime" SG_ 282 HCU_HybMod 20;
BA_ "Match" SG_ 282 HCU_HybMod "HCU_HybMod";
BA_ "Origin" SG_ 282 HCU_HybMod "ev";
BA_ "GenSigCycleTime" SG_ 282 HCU_HybFctnMod 20;
BA_ "Match" SG_ 282 HCU_HybFctnMod "HCU_HybFctnMod";
BA_ "Origin" SG_ 282 HCU_HybFctnMod "ev";
BA_ "GenSigCycleTime" SG_ 448 HCU_ChrgSysLmpSts 50;
BA_ "Match" SG_ 448 HCU_ChrgSysLmpSts "HCU_ChrgSysLmpSts";
BA_ "Origin" SG_ 448 HCU_ChrgSysLmpSts "ev";
BA_ "GenSigCycleTime" SG_ 448 HCU_ChrgSysErr_1 50;
BA_ "Match" SG_ 448 HCU_ChrgSysErr_1 "HCU_ChrgSysErr_1";
BA_ "Origin" SG_ 448 HCU_ChrgSysErr_1 "ev";
BA_ "GenSigCycleTime" SG_ 448 HCU_ChrgSysErr_2 50;
BA_ "Match" SG_ 448 HCU_ChrgSysErr_2 "HCU_ChrgSysErr_2";
BA_ "Origin" SG_ 448 HCU_ChrgSysErr_2 "ev";
BA_ "GenSigCycleTime" SG_ 448 HCU_ChrgSysErr_3 50;
BA_ "Match" SG_ 448 HCU_ChrgSysErr_3 "HCU_ChrgSysErr_3";
BA_ "Origin" SG_ 448 HCU_ChrgSysErr_3 "ev";
BA_ "GenSigCycleTime" SG_ 448 HCU_ChrgSysErr_4 50;
BA_ "Match" SG_ 448 HCU_ChrgSysErr_4 "HCU_ChrgSysErr_4";
BA_ "Origin" SG_ 448 HCU_ChrgSysErr_4 "ev";
BA_ "GenSigCycleTime" SG_ 448 HCU_ChrgSysErr_5 50;
BA_ "Match" SG_ 448 HCU_ChrgSysErr_5 "HCU_ChrgSysErr_5";
BA_ "Origin" SG_ 448 HCU_ChrgSysErr_5 "ev";
BA_ "GenSigCycleTime" SG_ 448 HCU_ChrgSysErr_6 50;
BA_ "Match" SG_ 448 HCU_ChrgSysErr_6 "HCU_ChrgSysErr_6";
BA_ "Origin" SG_ 448 HCU_ChrgSysErr_6 "ev";
BA_ "GenSigCycleTime" SG_ 448 HCU_ChrgSysErr_7 50;
BA_ "Match" SG_ 448 HCU_ChrgSysErr_7 "HCU_ChrgSysErr_7";
BA_ "Origin" SG_ 448 HCU_ChrgSysErr_7 "ev";
BA_ "GenSigCycleTime" SG_ 448 HCU_ChrgSysErr_8 50;
BA_ "Match" SG_ 448 HCU_ChrgSysErr_8 "HCU_ChrgSysErr_8";
BA_ "Origin" SG_ 448 HCU_ChrgSysErr_8 "ev";
BA_ "GenSigCycleTime" SG_ 448 HCU_DrvModDisp 50;
BA_ "Match" SG_ 448 HCU_DrvModDisp "HCU_DrvModDisp";
BA_ "Origin" SG_ 448 HCU_DrvModDisp "ev";
BA_ "GenSigCycleTime" SG_ 513 HCU_V2LReminder 50;
BA_ "Match" SG_ 513 HCU_V2LReminder "HCU_V2LReminder";
BA_ "Origin" SG_ 513 HCU_V2LReminder "ev";
BA_ "GenSigCycleTime" SG_ 513 HCU_SOCMngmntSts 50;
BA_ "Match" SG_ 513 HCU_SOCMngmntSts "HCU_SOCMngmntSts";
BA_ "Origin" SG_ 513 HCU_SOCMngmntSts "ev";
BA_ "GenSigCycleTime" SG_ 513 HCU_ARFSts 50;
BA_ "Match" SG_ 513 HCU_ARFSts "HCU_ARFSts";
BA_ "Origin" SG_ 513 HCU_ARFSts "ev";
BA_ "GenSigCycleTime" SG_ 513 HCU_ASFCSts 50;
BA_ "Match" SG_ 513 HCU_ASFCSts "HCU_ASFCSts";
BA_ "Origin" SG_ 513 HCU_ASFCSts "ev";
BA_ "GenSigCycleTime" SG_ 513 HCU_AGSSts 50;
BA_ "Match" SG_ 513 HCU_AGSSts "HCU_AGSSts";
BA_ "Origin" SG_ 513 HCU_AGSSts "ev";
BA_ "GenSigCycleTime" SG_ 513 PDCU_AvailabilityOfARF 50;
BA_ "Match" SG_ 513 PDCU_AvailabilityOfARF "PDCU_AvailabilityOfARF";
BA_ "Origin" SG_ 513 PDCU_AvailabilityOfARF "ev";
BA_ "GenSigCycleTime" SG_ 513 PDCU_lossenPedalPrompt 50;
BA_ "Match" SG_ 513 PDCU_lossenPedalPrompt "PDCU_lossenPedalPrompt";
BA_ "Origin" SG_ 513 PDCU_lossenPedalPrompt "ev";
BA_ "GenSigCycleTime" SG_ 513 PDCU_EvSave_disl 50;
BA_ "Match" SG_ 513 PDCU_EvSave_disl "PDCU_EvSave_disl";
BA_ "Origin" SG_ 513 PDCU_EvSave_disl "ev";
BA_ "GenSigCycleTime" SG_ 690 ExpertModReq_HUT_HCU 100;
BA_ "Match" SG_ 690 ExpertModReq_HUT_HCU "ExpertModReq_HUT_HCU";
BA_ "Origin" SG_ 690 ExpertModReq_HUT_HCU "ev";
BA_ "GenSigCycleTime" SG_ 301 EB_TgtRcprtnTrqSts 20;
BA_ "Match" SG_ 301 EB_TgtRcprtnTrqSts "EB_TgtRcprtnTrqSts";
BA_ "Origin" SG_ 301 EB_TgtRcprtnTrqSts "ev";
BA_ "GenSigCycleTime" SG_ 172 P2M_ActTrq 10;
BA_ "GenSigStartValue" SG_ 172 P2M_ActTrq 16382;
BA_ "Match" SG_ 172 P2M_ActTrq "P2M_ActTrq";
BA_ "Origin" SG_ 172 P2M_ActTrq "ev";
BA_ "GenSigCycleTime" SG_ 190 P2M_ActSpd 10;
BA_ "Match" SG_ 190 P2M_ActSpd "P2M_ActSpd";
BA_ "Origin" SG_ 190 P2M_ActSpd "ev";
BA_ "GenSigCycleTime" SG_ 190 P2M_ActHvDcVolt 10;
BA_ "GenSigStartValue" SG_ 190 P2M_ActHvDcVolt 4094;
BA_ "Match" SG_ 190 P2M_ActHvDcVolt "P2M_ActHvDcVolt";
BA_ "Origin" SG_ 190 P2M_ActHvDcVolt "ev";
BA_ "GenSigSendType" SG_ 510 T_BOX_ChrgTim_Day 2;
BA_ "Match" SG_ 510 T_BOX_ChrgTim_Day "T_BOX_ChrgTim_Day";
BA_ "Origin" SG_ 510 T_BOX_ChrgTim_Day "ev";
BA_ "GenSigCycleTime" SG_ 697 DWD_WorkSts 100;
BA_ "Match" SG_ 697 DWD_WorkSts "DWD_WorkSts";
BA_ "Origin" SG_ 697 DWD_WorkSts "ev";
BA_ "GenSigCycleTime" SG_ 697 DWD_TextDisp 100;
BA_ "Match" SG_ 697 DWD_TextDisp "DWD_TextDisp";
BA_ "Origin" SG_ 697 DWD_TextDisp "ev";
BA_ "GenSigCycleTime" SG_ 697 DWD_Dis 100;
BA_ "Match" SG_ 697 DWD_Dis "DWD_Dis";
BA_ "Origin" SG_ 697 DWD_Dis "ev";
BA_ "GenSigCycleTime" SG_ 697 DWD_SoundIndcn 100;
BA_ "Match" SG_ 697 DWD_SoundIndcn "DWD_SoundIndcn";
BA_ "Origin" SG_ 697 DWD_SoundIndcn "ev";
BA_ "GenSigCycleTime" SG_ 697 RSnsrFailSts 100;
BA_ "Match" SG_ 697 RSnsrFailSts "RSnsrFailSts";
BA_ "Origin" SG_ 697 RSnsrFailSts "ev";
BA_ "GenSigCycleTime" SG_ 697 LSnsrFailSts 100;
BA_ "Match" SG_ 697 LSnsrFailSts "LSnsrFailSts";
BA_ "Origin" SG_ 697 LSnsrFailSts "ev";
BA_ "GenSigCycleTime" SG_ 790 OBC_ModSts 200;
BA_ "GenSigStartValue" SG_ 790 OBC_ModSts 1;
BA_ "Match" SG_ 790 OBC_ModSts "OBC_ModSts";
BA_ "Origin" SG_ 790 OBC_ModSts "ev";
BA_ "GenSigCycleTime" SG_ 791 OBC_ConnectSts 200;
BA_ "Match" SG_ 791 OBC_ConnectSts "OBC_ConnectSts";
BA_ "Origin" SG_ 791 OBC_ConnectSts "ev";
BA_ "GenSigCycleTime" SG_ 708 BMS_BattSOCLimResp 100;
BA_ "GenSigStartValue" SG_ 708 BMS_BattSOCLimResp 6;
BA_ "Match" SG_ 708 BMS_BattSOCLimResp "BMS_BattSOCLimResp";
BA_ "Origin" SG_ 708 BMS_BattSOCLimResp "ev";
BA_ "GenSigSendType" SG_ 486 MultiColorNr1 2;
BA_ "GenSigStartValue" SG_ 486 MultiColorNr1 8;
BA_ "Match" SG_ 486 MultiColorNr1 "MultiColorNr1";
BA_ "Origin" SG_ 486 MultiColorNr1 "fuel";
BA_ "GenSigSendType" SG_ 486 MultiColorNr2 2;
BA_ "GenSigStartValue" SG_ 486 MultiColorNr2 9;
BA_ "Match" SG_ 486 MultiColorNr2 "MultiColorNr2";
BA_ "Origin" SG_ 486 MultiColorNr2 "fuel";
BA_ "GenSigSendType" SG_ 486 MultiColorNr3 2;
BA_ "GenSigStartValue" SG_ 486 MultiColorNr3 1;
BA_ "Match" SG_ 486 MultiColorNr3 "MultiColorNr3";
BA_ "Origin" SG_ 486 MultiColorNr3 "fuel";
BA_ "GenSigSendType" SG_ 486 MultiColorNr4 2;
BA_ "Match" SG_ 486 MultiColorNr4 "MultiColorNr4";
BA_ "Origin" SG_ 486 MultiColorNr4 "fuel";
BA_ "GenSigSendType" SG_ 486 MultiColorNr5 2;
BA_ "Match" SG_ 486 MultiColorNr5 "MultiColorNr5";
BA_ "Origin" SG_ 486 MultiColorNr5 "fuel";
BA_ "GenSigSendType" SG_ 486 MultiColorNr6 2;
BA_ "Match" SG_ 486 MultiColorNr6 "MultiColorNr6";
BA_ "Origin" SG_ 486 MultiColorNr6 "fuel";
BA_ "GenSigSendType" SG_ 486 MultiColorNr7 2;
BA_ "Match" SG_ 486 MultiColorNr7 "MultiColorNr7";
BA_ "Origin" SG_ 486 MultiColorNr7 "fuel";
BA_ "GenSigSendType" SG_ 486 MultiColorNr8 2;
BA_ "Match" SG_ 486 MultiColorNr8 "MultiColorNr8";
BA_ "Origin" SG_ 486 MultiColorNr8 "fuel";
BA_ "GenSigSendType" SG_ 492 MultiColorNr9 2;
BA_ "Match" SG_ 492 MultiColorNr9 "MultiColorNr9";
BA_ "Origin" SG_ 492 MultiColorNr9 "fuel";
BA_ "GenSigSendType" SG_ 492 MultiColorNr10 2;
BA_ "Match" SG_ 492 MultiColorNr10 "MultiColorNr10";
BA_ "Origin" SG_ 492 MultiColorNr10 "fuel";
BA_ "GenSigSendType" SG_ 492 MultiColorNr11 2;
BA_ "Match" SG_ 492 MultiColorNr11 "MultiColorNr11";
BA_ "Origin" SG_ 492 MultiColorNr11 "fuel";
BA_ "GenSigSendType" SG_ 492 MultiColorNr12 2;
BA_ "Match" SG_ 492 MultiColorNr12 "MultiColorNr12";
BA_ "Origin" SG_ 492 MultiColorNr12 "fuel";
BA_ "GenSigSendType" SG_ 492 MultiColorNr13 2;
BA_ "Match" SG_ 492 MultiColorNr13 "MultiColorNr13";
BA_ "Origin" SG_ 492 MultiColorNr13 "fuel";
BA_ "GenSigSendType" SG_ 492 MultiColorNr14 2;
BA_ "Match" SG_ 492 MultiColorNr14 "MultiColorNr14";
BA_ "Origin" SG_ 492 MultiColorNr14 "fuel";
BA_ "GenSigSendType" SG_ 492 MultiColorNr15 2;
BA_ "Match" SG_ 492 MultiColorNr15 "MultiColorNr15";
BA_ "Origin" SG_ 492 MultiColorNr15 "fuel";
BA_ "GenSigSendType" SG_ 492 MultiColorNr16 2;
BA_ "Match" SG_ 492 MultiColorNr16 "MultiColorNr16";
BA_ "Origin" SG_ 492 MultiColorNr16 "fuel";
BA_ "GenSigCycleTime" SG_ 130 NetEngTrq 10;
BA_ "GenSigStartValue" SG_ 130 NetEngTrq 32767;
BA_ "Match" SG_ 130 NetEngTrq "NetEngTrq";
BA_ "Origin" SG_ 130 NetEngTrq "fuel";
BA_ "GenSigCycleTime" SG_ 130 DrvEngTrqReq 10;
BA_ "GenSigStartValue" SG_ 130 DrvEngTrqReq 32767;
BA_ "Match" SG_ 130 DrvEngTrqReq "DrvEngTrqReq";
BA_ "Origin" SG_ 130 DrvEngTrqReq "fuel";
BA_ "GenSigCycleTime" SG_ 258 AccelPedlPosnDiagc 20;
BA_ "Match" SG_ 258 AccelPedlPosnDiagc "AccelPedlPosnDiagc";
BA_ "Origin" SG_ 258 AccelPedlPosnDiagc "fuel";
BA_ "GenSigCycleTime" SG_ 132 HCU_RaceLaunchAvail_0x84 10;
BA_ "Match" SG_ 132 HCU_RaceLaunchAvail_0x84 "HCU_RaceLaunchAvail";
BA_ "Origin" SG_ 132 HCU_RaceLaunchAvail_0x84 "fuel";
BA_ "GenSigCycleTime" SG_ 132 HCU_RaceLaunchSts_0x84 10;
BA_ "Match" SG_ 132 HCU_RaceLaunchSts_0x84 "HCU_RaceLaunchSts";
BA_ "Origin" SG_ 132 HCU_RaceLaunchSts_0x84 "fuel";
BA_ "GenSigCycleTime" SG_ 724 DPF_Warning 100;
BA_ "Match" SG_ 724 DPF_Warning "DPF_Warning";
BA_ "Origin" SG_ 724 DPF_Warning "fuel";
BA_ "GenSigCycleTime" SG_ 724 WIFSensorFailSts 100;
BA_ "Match" SG_ 724 WIFSensorFailSts "WIFSensorFailSts";
BA_ "Origin" SG_ 724 WIFSensorFailSts "fuel";
BA_ "GenSigCycleTime" SG_ 724 GlowPlugLmpCmd 100;
BA_ "Match" SG_ 724 GlowPlugLmpCmd "GlowPlugLmpCmd";
BA_ "Origin" SG_ 724 GlowPlugLmpCmd "fuel";
BA_ "GenSigCycleTime" SG_ 724 UreaLampCmd 100;
BA_ "Match" SG_ 724 UreaLampCmd "UreaLampCmd";
BA_ "Origin" SG_ 724 UreaLampCmd "fuel";
BA_ "GenSigCycleTime" SG_ 724 Urea_Level 100;
BA_ "Match" SG_ 724 Urea_Level "Urea_Level";
BA_ "Origin" SG_ 724 Urea_Level "fuel";
BA_ "GenSigCycleTime" SG_ 724 UreaRemainDist 100;
BA_ "Match" SG_ 724 UreaRemainDist "UreaRemainDist";
BA_ "Origin" SG_ 724 UreaRemainDist "fuel";
BA_ "GenSigCycleTime" SG_ 724 SCRSysWarnDisplay 100;
BA_ "Match" SG_ 724 SCRSysWarnDisplay "SCRSysWarnDisplay";
BA_ "Origin" SG_ 724 SCRSysWarnDisplay "fuel";
BA_ "GenSigCycleTime" SG_ 724 WIFFullLmpCmd 100;
BA_ "Match" SG_ 724 WIFFullLmpCmd "WIFFullLmpCmd";
BA_ "Origin" SG_ 724 WIFFullLmpCmd "fuel";
BA_ "GenSigCycleTime" SG_ 724 DPF_Activation 100;
BA_ "Match" SG_ 724 DPF_Activation "DPF_Activation";
BA_ "Origin" SG_ 724 DPF_Activation "fuel";
BA_ "GenSigCycleTime" SG_ 848 EngOilLvlWrn 500;
BA_ "Match" SG_ 848 EngOilLvlWrn "EngOilLvlWrn";
BA_ "Origin" SG_ 848 EngOilLvlWrn "fuel";
BA_ "GenSigCycleTime" SG_ 848 EngOilLowPresWrn 500;
BA_ "Match" SG_ 848 EngOilLowPresWrn "EngOilLowPresWrn";
BA_ "Origin" SG_ 848 EngOilLowPresWrn "fuel";
BA_ "GenSigCycleTime" SG_ 848 EngOilPres 500;
BA_ "Match" SG_ 848 EngOilPres "EngOilPres";
BA_ "Origin" SG_ 848 EngOilPres "fuel";
BA_ "GenSigCycleTime" SG_ 848 EngOilTemp 500;
BA_ "Match" SG_ 848 EngOilTemp "EngOilTemp";
BA_ "Origin" SG_ 848 EngOilTemp "fuel";
BA_ "GenSigCycleTime" SG_ 335 BMS_BattSOC_P0 20;
BA_ "Match" SG_ 335 BMS_BattSOC_P0 "BMS_BattSOC_P0";
BA_ "Origin" SG_ 335 BMS_BattSOC_P0 "fuel";
BA_ "GenSigCycleTime" SG_ 158 HCU_PowertrainSts_0x9e 10;
BA_ "Match" SG_ 158 HCU_PowertrainSts_0x9e "HCU_PowertrainSts";
BA_ "Origin" SG_ 158 HCU_PowertrainSts_0x9e "fuel";
BA_ "GenSigCycleTime" SG_ 158 HCU_TotDrvReqPower_0x9e 10;
BA_ "GenSigStartValue" SG_ 158 HCU_TotDrvReqPower_0x9e 100;
BA_ "Match" SG_ 158 HCU_TotDrvReqPower_0x9e "HCU_TotDrvReqPower";
BA_ "Origin" SG_ 158 HCU_TotDrvReqPower_0x9e "fuel";
BA_ "GenSigCycleTime" SG_ 158 TgtRcprtnTrqSts 10;
BA_ "Match" SG_ 158 TgtRcprtnTrqSts "TgtRcprtnTrqSts";
BA_ "Origin" SG_ 158 TgtRcprtnTrqSts "fuel";
VAL_ 659 IP_CurrTheme 0 "Valid Value" 3 "Valid Value" 4 "Initial value" 5 "Reserved" 7 "Reserved";
VAL_ 659 IP_VehSpdDisp 0 "Valid" 510 "Valid" 511 "Invalid";
VAL_ 659 IP_VelSpdDisp_Mile 0 "Valid" 254 "Valid" 255 "Invalid";
VAL_ 659 IP_FuelMainTankR 0 "Invalid value" 1 "Reserved" 9 "Reserved" 10 "Valid value" 1000 "Valid value" 1001 "Reserved" 1022 "Reserved" 1023 "Invalid value";
VAL_ 659 IP_FuelAuxTankR 0 "Invalid value" 1 "Reserved" 9 "Reserved" 10 "Valid value" 1000 "Valid value" 1001 "Reserved" 1022 "Reserved" 1023 "Invalid value";
VAL_ 659 IP_LagueSet 0 "Chinese" 1 "English" 2 "Russian" 3 "Spaish" 4 "Portuguese" 5 "German" 6 "French" 7 "Italian" 8 "Arabic" 9 "Thai" 10 "Ukrainian" 11 "Indonesian" 12 "Reserve" 14 "Reserve" 15 "Invalid value";
VAL_ 639 CheckSum_IP2 0 "Valid values" 255 "Valid values";
VAL_ 639 IP_DrvSeatBeltWarnLmpFailSts 0 "No failure" 1 "Failure" 2 "Signal not available" 3 "Reserved";
VAL_ 639 IP_PassSeatBeltWarnLmpFailSts 0 "No failure" 1 "Failure" 2 "Signal not available" 3 "Reserved";
VAL_ 639 IP_VehTotDistance 0 "0-9999999-km" 9999999 "0-9999999-km" 10000000 "Reserved" 16777214 "Reserved" 16777215 "Invalid";
VAL_ 639 IP_VehTotDistanceValid 0 "Invalid" 1 "Valid";
VAL_ 639 IP_FuelLvlInfo 0 "Valid Value" 200 "Valid Value" 201 "Reserved" 254 "Reserved" 255 "Invalid Value";
VAL_ 639 IP_FuelLvlLowLmpSts 0 "OFF" 1 "ON" 2 "Internal Error" 3 "Reserved";
VAL_ 639 IP_BattChrgLmpSts 0 "OFF" 1 "ON" 2 "Internal Error" 3 "Reserved";
VAL_ 639 IP_EngOilPressLowLmpSts 0 "OFF" 1 "ON" 2 "Internal Error" 3 "Reserved";
VAL_ 639 IP_ABMWarnLmpFailrSts 0 "No failure" 1 "Failure" 2 "Signal not available" 3 "Reserved";
VAL_ 639 IP_Err 0 "No error" 1 "Error";
VAL_ 639 IP_ACCErr 0 "No error" 1 "Error";
VAL_ 639 IP_VehSpdUnit 0 "kph" 1 "mph";
VAL_ 639 IP_VINcompr 0 "equality" 1 "inequality";
VAL_ 639 RollingCounter_IP2 0 "Valid value" 14 "Valid value" 15 "Invalid value";
VAL_ 842 IP_RemainDistance 0 "0~2000" 2000 "0~2000" 2001 "Reserved" 4094 "Reserved" 4095 "Invalid";
VAL_ 842 IP_InstFuelConsUnit 0 "L100km" 1 "Lh";
VAL_ 842 IP_EBDFailSts 0 "No failure" 1 "Failure";
VAL_ 842 IP_AvgFuelCons 0 "Valid" 2999 "Valid" 3000 "Reserved" 4094 "Reserved" 4095 "Invalid";
VAL_ 842 IP_InstFuelCons 0 "Valid" 9999 "Valid" 10000 "Reserved" 16382 "Reserved" 16383 "Invalid";
VAL_ 717 PassWinPosnSts_Perc 0 "Unknown" 1 "Close" 2 "Open" 3 "5%Open" 4 "10%Open" 5 "15%Open" 6 "20%Open" 7 "25%Open" 8 "30%Open" 9 "35%Open" 10 "40%Open" 11 "45%Open" 12 "50%Open" 13 "55%Open" 14 "60%Open" 15 "65%Open" 16 "70%Open" 17 "75%Open" 18 "80%Open" 19 "85%Open" 20 "90%Open" 21 "95%Open" 22 "Reserved" 31 "Reserved";
VAL_ 717 PassWinLrnSts 0 "Unlearn" 1 "Learn";
VAL_ 717 PassWinHotProtSts 0 "NO" 1 "Hot prtect";
VAL_ 717 PassSideRearWinPosnSts_Perc 0 "Unknown" 1 "Close" 2 "Open" 3 "5%Open" 4 "10%Open" 5 "15%Open" 6 "20%Open" 7 "25%Open" 8 "30%Open" 9 "35%Open" 10 "40%Open" 11 "45%Open" 12 "50%Open" 13 "55%Open" 14 "60%Open" 15 "65%Open" 16 "70%Open" 17 "75%Open" 18 "80%Open" 19 "85%Open" 20 "90%Open" 21 "95%Open" 22 "Reserved" 31 "Reserved";
VAL_ 717 PassSideRearWinLrnSts 0 "Unlearn" 1 "Learn";
VAL_ 717 PassSideRearWinHotProtSts 0 "NO" 1 "Hot prtect";
VAL_ 661 SysPowerMod 0 "OFF" 1 "ACC (reserved)" 2 "ON" 3 "Crank";
VAL_ 661 SysPowerModVld 0 "Invalid" 1 "Valid";
VAL_ 661 PEPS_PowerRlyOutpSts 0 "ACC & IGN1 & IGN2 are disconnected" 1 "ACC connected, others are disconnected(Reserved)" 2 "IGN2 connected, others are disconnected" 3 "ACC & IGN2 connected, IGN1 disconnected(Reserved)" 4 "IGN1 connected, others are disconnected" 5 "IGN1 & ACC connected, IGN2 disconnected(Reserved)" 6 "IGN1 & IGN2 connected, ACC disconnected(Reserved)" 7 "ACC & IGN1 & IGN2 connected";
VAL_ 661 RemPowerFailureSts 0 "No failure" 1 "power on condition not satisfied" 2 "power off condition not satisfied" 3 "Reserved";
VAL_ 661 RemUpgrdModSysPower 0 "OFF" 1 "Remote upgrade mode ON (Engine OFF )" 2 "Reserved" 3 "Reserved";
VAL_ 770 WarnPowerNotInOffPosn 0 "No Warning" 1 "Warning";
VAL_ 770 WarnKeyInCarWhenExit 0 "No Warning" 1 "Warning";
VAL_ 770 WarnVldKeyNotFound 0 "No Warning" 1 "Warning";
VAL_ 770 WarnEngStrtNotMeet 0 "No Warning" 1 "Warning";
VAL_ 770 PowerRlyFault 0 "No failure" 1 "ACCIGN1IGN2 Relay failure(ACC Reserved)";
VAL_ 770 AntLostFlg 0 "Not Lost" 1 "Antenna Lost";
VAL_ 412 HiPosnBrkLmpFailSts 0 "No failure" 1 "failure";
VAL_ 412 LBrkLmpFailSts 0 "No failure" 1 "failure";
VAL_ 412 RFogLmpFailSts_R_PBox 0 "No failure" 1 "failure";
VAL_ 412 RFogLmpSts_R_PBox 0 "Off" 1 "On";
VAL_ 412 ParkLmpSts_R_PBox 0 "Off" 1 "On";
VAL_ 412 RBrkLmpFailSts 0 "No failure" 1 "failure";
VAL_ 412 PosnLmpOutpSts_R_PBox 0 "OFF" 1 "ON";
VAL_ 412 RRPosnLmpFailSts 0 "No failure" 1 "failure";
VAL_ 412 RvsLmpFailSts 0 "No failure" 1 "failure";
VAL_ 412 LRPosnLmpFailSts 0 "No failure" 1 "failure";
VAL_ 412 LTurnLmpSts_R_PBox 0 "Off" 1 "On";
VAL_ 412 RTurnLmpSts_R_PBox 0 "Off" 1 "On";
VAL_ 412 RWinHeatgIconRlyCmd 0 "Not active" 1 "Active";
VAL_ 412 RWinHeatgFailSts 0 "No Failure" 1 "Failure";
VAL_ 412 LicPlateLmpFailSts 0 "No failure" 1 "failure";
VAL_ 412 RTurnLmpFailSts 0 "No failure" 1 "Short circuit" 2 "Open circuit" 3 "Reserved";
VAL_ 412 LTurnLmpFailSts 0 "No failure" 1 "Short circuit" 2 "Open circuit" 3 "Reserved";
VAL_ 412 LBrkLmpOutpSts_R_PBox 0 "Off" 1 "On";
VAL_ 412 RBrkLmpOutpSts_R_PBox 0 "Off" 1 "On";
VAL_ 412 HiPosnBrkLmpOutpSts_R_PBox 0 "Off" 1 "On";
VAL_ 367 RSDS_IPSoundReq 0 "No warning" 1 "Warning level 1Ã¯Â¼Âˆ2HzÃ¥Â£Â°Ã©ÂŸÂ³Ã¯Â¼Â‰" 2 "Warning level 2Ã¯Â¼Âˆ4HzÃ¥Â£Â°Ã©ÂŸÂ³Ã¯Â¼Â‰" 3 "Warning level 3Ã¯Â¼ÂˆÃ¥Â¸Â¸Ã¥Â“ÂÃ¯Â¼Â‰";
VAL_ 367 RSDS_ErrSts 0 "No Error" 1 "Error";
VAL_ 367 RSDS_BrkgTrig 0 "Not tirggered" 1 "Triggered";
VAL_ 367 RSDS_BliSts 0 "No Blindness" 1 "Blindness";
VAL_ 367 RSDS_TrailerSts 0 "None" 1 "Trailer";
VAL_ 367 RSDS_LCAResp 0 "OFF" 1 "ON";
VAL_ 367 RSDS_DOWResp 0 "OFF" 1 "ON";
VAL_ 367 RSDS_RCWResp 0 "OFF" 1 "ON";
VAL_ 367 RSDS_RCTAResp 0 "OFF" 1 "ON";
VAL_ 367 RSDS_RCTABrkResp 0 "OFF" 1 "ON";
VAL_ 367 RSDS_RCW_Trigger 0 "No warning" 1 "RCW level 1" 2 "RCW level 2" 3 "Reserved";
VAL_ 367 RSDS_CTA_Actv 0 "Not active" 1 "Active";
VAL_ 367 BSD_LCA_warningReqRight 0 "No warning" 1 "Warning level 1" 2 "Warning level 2" 3 "Reserved";
VAL_ 367 BSD_LCA_warningReqleft 0 "No warning" 1 "Warning level 1" 2 "Warning level 2" 3 "Reserved";
VAL_ 367 DOW_warningReqRight 0 "No warning" 1 "Warning level 1" 2 "Warning level 2" 3 "Reserved";
VAL_ 367 DOW_warningReqleft 0 "No warning" 1 "Warning level 1" 2 "Warning level 2" 3 "Reserved";
VAL_ 367 RCTA_warningReqRight 0 "No warning" 1 "Warning level 2";
VAL_ 367 RCTA_warningReqLeft 0 "No warning" 1 "Warning level 2";
VAL_ 778 RCTA_B_TTC 0 "No Display" 1 "valid value" 63 "valid value";
VAL_ 778 BSD_LCA_Left_TTC 0 "No Display" 1 "valid value" 63 "valid value";
VAL_ 778 BSD_LCA_Right_TTC 0 "No Display" 1 "valid value" 63 "valid value";
VAL_ 778 RCW_TTC 0 "No Display" 1 "valid value" 63 "valid value";
VAL_ 778 RSDS_LeTgt_01 0 "No target" 1 "target detected";
VAL_ 778 RSDS_LeTgt_01_dx 0 "Valid Value" 950 "Valid Value" 951 "Reserved" 1023 "Reserved";
VAL_ 778 RSDS_LeTgt_01_dy 0 "Valid Value" 80 "Valid Value" 81 "Reserved" 127 "Reserved";
VAL_ 778 RSDS_LeTgt_02 0 "No target" 1 "target detected";
VAL_ 778 RSDS_LeTgt_02_dx 0 "Valid Value" 950 "Valid Value" 951 "Reserved" 1023 "Reserved";
VAL_ 778 RSDS_LeTgt_02_dy 0 "Valid Value" 80 "Valid Value" 81 "Reserved" 127 "Reserved";
VAL_ 778 RSDS_RiTgt_01 0 "No target" 1 "target detected";
VAL_ 778 RSDS_RiTgt_01_dx 0 "Valid Value" 950 "Valid Value" 951 "Reserved" 1023 "Reserved";
VAL_ 778 RSDS_RiTgt_01_dy 0 "Valid Value" 80 "Valid Value" 81 "Reserved" 127 "Reserved";
VAL_ 778 RSDS_RiTgt_02 0 "No target" 1 "target detected";
VAL_ 778 RSDS_RiTgt_02_dx 0 "Valid Value" 950 "Valid Value" 951 "Reserved" 1023 "Reserved";
VAL_ 778 RSDS_RiTgt_02_dy 0 "Valid Value" 80 "Valid Value" 81 "Reserved" 127 "Reserved";
VAL_ 778 RSDS_MidTgt_01 0 "No target" 1 "target detected";
VAL_ 778 RSDS_MidTgt_01_dx 0 "Valid Value" 950 "Valid Value" 951 "Reserved" 1023 "Reserved";
VAL_ 778 RSDS_MidTgt_01_dy 0 "Valid Value" 80 "Valid Value" 81 "Reserved" 127 "Reserved";
VAL_ 778 RSDS_MidTgt_02 0 "No target" 1 "target detected";
VAL_ 778 RSDS_MidTgt_02_dx 0 "Valid Value" 950 "Valid Value" 951 "Reserved" 1023 "Reserved";
VAL_ 778 RSDS_MidTgt_02_dy 0 "Valid Value" 80 "Valid Value" 81 "Reserved" 127 "Reserved";
VAL_ 51 T_BOX_RemtDoorLockCtrl 0 "No Action" 1 "Driver door unlock" 2 "All doors unlock" 3 "Lock" 4 "Invalid" 5 "reserved" 7 "reserved";
VAL_ 51 T_BOX_AudioMuteReq 0 "No action" 1 "Request mute" 2 "Request unmute" 3 "Reserved";
VAL_ 51 T_BOX_PM25AirQLvl 0 "Level 1" 1 "Level 2" 2 "Level 3" 3 "Level 4" 4 "Level 5" 5 "Level 6" 6 "Reserved" 7 "TSP return error" 8 "Current city no information" 9 "No network signal" 10 "Reserved" 15 "Reserved";
VAL_ 51 T_BOX_PM25Dens 0 "PM2.5 density" 999 "PM2.5 density" 1000 "Current city no information" 1001 "No network signal" 1002 "Reserved" 1022 "Reserved" 1023 "Invalid";
VAL_ 1001 T_BOX_SysErrSts 0 "No error" 1 "Error" 2 "Standby Battery Error" 3 "Reserved" 31 "Reserved";
VAL_ 1001 T_BOX_SWUpdSts 0 "Idle" 1 "NAD start update" 2 "NAD update inprogress" 3 "NAD update done" 4 "NAD update failed" 5 "MCU start update" 6 "MCU update done" 7 "Reserved";
VAL_ 481 T_BOX_RemtVideoMonrEnaReq_APP 0 "No action" 1 "Disable" 2 "Enable" 3 "Reserved";
VAL_ 752 V2X_FCW 0 "No Warning" 1 "Warning" 2 "Reserved" 3 "Reserved";
VAL_ 752 V2X_BSW 0 "NO  Warning" 1 "Left Blind Warning" 2 "Right Blind Warning" 3 "Left Blind Warning andRight Blind Warning" 4 "Reserved" 15 "Reserved";
VAL_ 752 V2X_LCW 0 "NO  Warning" 1 "Left Lane Change Warning" 2 "Right Lane Change Warning" 3 "Reserved";
VAL_ 752 V2X_EBW 0 "NO  Warning" 1 "Warning" 2 "Reserved" 3 "Reserved";
VAL_ 752 V2X_ICW 0 "NO  Warning" 1 "Left crossroad Warning" 2 "Right crossroad Warning" 3 "Left and Right corssroad both Warning" 4 "Reserved" 15 "Reserved";
VAL_ 752 V2X_LTA 0 "NO  Warning" 1 "Warning" 2 "Reserved" 3 "Reserved";
VAL_ 752 V2X_IVSW 0 "No Warning" 1 "Snow" 2 "Fog" 3 "Rain" 4 "Haze" 5 "HailÃ¯Â¼ÂˆÃ¥Â†Â°Ã©Â›Â¹Ã¯Â¼Â‰" 6 "Wind" 7 "Sandstorm  (Ã¦Â²Â™Ã¥Â°Â˜Ã¦ÂšÂ´)" 8 "Narrow Bridge" 9 "RoundaboutÃ¯Â¼ÂˆÃ§ÂŽÂ¯Ã¥Â²Â›Ã¯Â¼Â‰" 10 "No Whistle Ã¯Â¼ÂˆÃ§Â¦ÂÃ¦Â­Â¢Ã©Â¸Â£Ã§Â¬Â›Ã¯Â¼Â‰" 11 "Danger" 12 "Gas" 13 "Service Area" 14 "Rest Area Advance Notice" 15 "No OvertakeÃ¯Â¼ÂˆÃ§Â¦ÂÃ¦Â­Â¢Ã¨Â¶Â…Ã¨Â½Â¦Ã¯Â¼Â‰" 16 "No Pass" 17 "No Entry" 18 "NoStraightLeftTurn" 19 "NoStraightRightTurn" 20 "NoLeftRightTurn" 21 "NoLeftTurn" 22 "NoRightTurn" 23 "NoStraight" 24 "WarnWorks" 25 "AccidentProneSectionÃ¯Â¼ÂˆÃ¤ÂºÂ‹Ã¦Â•Â…Ã¥Â¤ÂšÃ¥ÂÂ‘Ã¨Â·Â¯Ã¦Â®ÂµÃ¯Â¼Â‰" 26 "ContinuousBendÃ¯Â¼ÂˆÃ¨Â¿ÂžÃ§Â»Â­Ã¥Â¼Â¯Ã¨Â·Â¯Ã¯Â¼Â‰" 27 "Steep Slope Ã¥ÂÂ¡Ã¨Â·Â¯Ã¯Â¼ÂˆÃ¨Â­Â¦5Ã¯Â¼Â‰" 28 "Caution Children Ã¦Â³Â¨Ã¦Â„ÂÃ¥Â„Â¿Ã§Â«Â¥Ã¯Â¼ÂˆÃ¨Â­Â¦11Ã¯Â¼Â‰" 29 "Warn wildanimal Ã¦Â³Â¨Ã¦Â„ÂÃ©Â‡ÂŽÃ§Â”ÂŸÃ¥ÂŠÂ¨Ã§Â‰Â©Ã¯Â¼ÂˆÃ¨Â­Â¦13Ã¯Â¼Â‰" 30 "Unguarded Railway Ã¦Â—Â Ã¤ÂºÂºÃ§ÂœÂ‹Ã¥Â®ÂˆÃ©Â“ÂÃ¨Â·Â¯Ã¯Â¼ÂˆÃ¨Â­Â¦29Ã¯Â¼Â‰" 31 "NO Turn around Ã§Â¦ÂÃ¦Â­Â¢Ã¦ÂŽÂ‰Ã¥Â¤Â´Ã¯Â¼ÂˆÃ§Â¦Â28Ã¯Â¼Â‰" 32 "NO Parking Ã§Â¦ÂÃ¦Â­Â¢Ã¥ÂÂœÃ¨Â½Â¦Ã¯Â¼ÂˆÃ§Â¦Â31Ã¯Â¼Â‰" 33 "Limit Width Ã©Â™ÂÃ¥ÂˆÂ¶Ã¥Â®Â½Ã¥ÂºÂ¦Ã¯Â¼ÂˆÃ§Â¦Â34Ã¯Â¼Â‰" 34 "Limit Height Ã©Â™ÂÃ¥ÂˆÂ¶Ã©Â«Â˜Ã¥ÂºÂ¦Ã¯Â¼ÂˆÃ§Â¦Â35Ã¯Â¼Â‰" 35 "Parking Area Notice Ã¥ÂÂœÃ¨Â½Â¦Ã¥ÂœÂºÃ©Â¢Â„Ã¥Â‘ÂŠÃ¯Â¼ÂˆÃ¨Â·Â¯74Ã¯Â¼Â‰" 36 "Parking Area Ã¥ÂÂœÃ¨Â½Â¦Ã¥ÂœÂºÃ¯Â¼ÂˆÃ¨Â·Â¯75Ã¯Â¼Â‰" 37 "Reserved" 255 "Reserved";
VAL_ 752 V2X_AVW 0 "No Warning" 1 "Left Forward Warning (Ã¥Â·Â¦Ã¥Â‰ÂÃ¦Â–Â¹)" 2 "Forward Warning(Ã¦Â­Â£Ã¥Â‰ÂÃ¦Â–Â¹)" 3 "Right Forward Warning(Ã¥ÂÂ³Ã¥Â‰ÂÃ¦Â–Â¹)" 4 "Reserved" 7 "Reserved";
VAL_ 752 V2X_EVW 0 "No Warning" 1 "TypeUnkown Warning" 2 "Fire Truck" 3 "Ambulance" 4 "Police Vehicle" 5 "Other Responder" 6 "Reserved" 7 "Reserved";
VAL_ 752 V2X_DNPW 0 "NO  Warning" 1 "Warning" 2 "Reserved" 3 "Reserved";
VAL_ 752 V2X_HLW 0 "No Warning" 1 "Deep water" 2 "Deep pit" 3 "Slippery roadÃ¯Â¼ÂˆÃ¦Â¹Â¿Ã¦Â»Â‘Ã©ÂÂ“Ã¨Â·Â¯Ã¯Â¼Â‰" 4 "Sharp turn ahead" 5 "Road barrier(Ã©ÂÂ“Ã¨Â·Â¯Ã©ÂšÂœÃ§Â¢Â)" 6 "Road bumpÃ¯Â¼ÂˆÃ¨Â·Â¯Ã©ÂÂ¢Ã¤Â¸ÂÃ¥Â¹Â³Ã¯Â¼Â‰" 7 "Dangerous road near the mountainÃ¯Â¼ÂˆÃ¥Â‚ÂÃ¥Â±Â±Ã©Â™Â©Ã¨Â·Â¯Ã¯Â¼Â‰" 8 "Debris flowÃ¯Â¼ÂˆÃ¦Â³Â¥Ã§ÂŸÂ³Ã¦ÂµÂÃ¯Â¼Â‰" 9 "BridgeÃ¯Â¼ÂˆÃ©Â©Â¼Ã¥Â³Â°Ã¦Â¡Â¥Ã¯Â¼Â‰" 10 "Tunnel" 11 "Fire(Ã§ÂÂ«Ã§ÂÂ¾)" 12 "Falling Rocks" 13 "Icy Road" 14 "CrossWinds" 15 "Embankment roadÃ¯Â¼ÂˆÃ¥Â Â¤Ã¥ÂÂÃ¨Â·Â¯Ã¯Â¼Â‰" 16 "ReverseCurve" 17 "Narrow road" 18 "Pay attention to confluence" 19 "Facility Damaged" 20 "Throwing ObjectÃ¯Â¼ÂˆÃ¦Â•Â£Ã¨ÂÂ½Ã§Â‰Â©Ã¤Â½Â“Ã¯Â¼Â‰" 21 "Reserved" 31 "Reserved";
VAL_ 752 V2X_TJW 0 "No Warning" 1 "Light Congestion" 2 "Moderate Congestion" 3 "Heavy Congestion" 4 "Unknown Congestion" 5 "Reserved" 7 "Reserved";
VAL_ 752 V2X_CLW 0 "No Warning" 1 "Forward Warning" 2 "Rear Warning" 3 "Forward and Rear Warning" 4 "Reserved" 63 "Reserved";
VAL_ 752 V2X_RLVW 0 "No Warning" 1 "Warning" 2 "Reserved" 3 "Reserved";
VAL_ 752 V2X_VRUCW 0 "No Warning" 1 "Forward Warning" 2 "Rear Warning" 3 "Forward and Rear Warning" 4 "Reserved" 15 "Reserved";
VAL_ 752 V2X_SLW 0 "No Warning" 1 "SPL 5" 2 "SPL 10" 3 "SPL 15" 4 "SPL 20" 5 "SPL 25" 25 "SPL 125" 26 "SPL 130" 27 "SPL 135" 28 "SPL 140" 29 "SPL 145" 30 "SPL 150" 31 "Reserved" 63 "Reserved";
VAL_ 752 V2X_GLOSA 0 "SPL 0-SPL 150" 150 "SPL 0-SPL 150" 151 "Reserved" 254 "Reserved" 255 "No Warning";
VAL_ 752 V2X_SL1_LightTyp 0 "No warning" 1 "S" 2 "LT" 3 "RT" 4 "TA" 5 "SLT" 6 "SRT" 7 "SLRT" 8 "STA" 9 "Red light allow to turn  left" 10 "Red light allow to turn right" 11 "Reserved" 15 "Reserved";
VAL_ 752 V2X_SL1_LightColor 0 "No warning" 1 "Red light" 2 "Green light" 3 "Yellow light" 4 "Red light flash" 5 "Green light flash" 6 "Yellow light flash" 7 "Reserved" 15 "Reserved";
VAL_ 752 V2X_SL1_LightTim 0 "No warning" 1 "Valid Value" 999 "Valid Value" 1000 "Reserved" 65535 "Reserved";
VAL_ 752 V2X_SL2_LightTyp 0 "No warning" 1 "S" 2 "LT" 3 "RT" 4 "TA" 5 "SLT" 6 "SRT" 7 "SLRT" 8 "STA" 9 "Red light allow to turn  left" 10 "Red light allow to turn right" 11 "Reserved" 15 "Reserved";
VAL_ 752 V2X_SL2_LightColor 0 "No warning" 1 "Red light" 2 "Green light" 3 "Yellow light" 4 "Red light flash" 5 "Green light flash" 6 "Yellow light flash" 7 "Reserved" 15 "Reserved";
VAL_ 752 V2X_SL2_LightTim 0 "No warning" 1 "Valid Value" 999 "Valid Value" 1000 "Reserved" 65535 "Reserved";
VAL_ 752 V2X_SL3_LightTyp 0 "No warning" 1 "S" 2 "LT" 3 "RT" 4 "TA" 5 "SLT" 6 "SRT" 7 "SLRT" 8 "STA" 9 "Red light allow to turn  left" 10 "Red light allow to turn right" 11 "Reserved" 15 "Reserved";
VAL_ 752 V2X_SL3_LightColor 0 "No warning" 1 "Red light" 2 "Green light" 3 "Yellow light" 4 "Red light flash" 5 "Green light flash" 6 "Yellow light flash" 7 "Reserved" 15 "Reserved";
VAL_ 752 V2X_SL3_LightTim 0 "No warning" 1 "Valid Value" 999 "Valid Value" 1000 "Reserved" 65535 "Reserved";
VAL_ 752 V2X_SL4_LightTyp 0 "No warning" 1 "S" 2 "LT" 3 "RT" 4 "TA" 5 "SLT" 6 "SRT" 7 "SLRT" 8 "STA" 9 "Red light allow to turn  left" 10 "Red light allow to turn right" 11 "Reserved" 15 "Reserved";
VAL_ 752 V2X_SL4_LightColor 0 "No warning" 1 "Red light" 2 "Green light" 3 "Yellow light" 4 "Red light flash" 5 "Green light flash" 6 "Yellow light flash" 7 "Reserved" 15 "Reserved";
VAL_ 752 V2X_SL5_LightTyp 0 "No warning" 1 "S" 2 "LT" 3 "RT" 4 "TA" 5 "SLT" 6 "SRT" 7 "SLRT" 8 "STA" 9 "Red light allow to turn  left" 10 "Red light allow to turn right" 11 "Reserved" 15 "Reserved";
VAL_ 752 V2X_SL4_LightTim 0 "No warning" 1 "Valid Value" 999 "Valid Value" 1000 "Reserved" 65535 "Reserved";
VAL_ 752 V2X_SL5_LightColor 0 "No warning" 1 "Red light" 2 "Green light" 3 "Yellow light" 4 "Red light flash" 5 "Green light flash" 6 "Yellow light flash" 7 "Reserved" 15 "Reserved";
VAL_ 752 V2X_SL5_LightTim 0 "No warning" 1 "Valid Value" 999 "Valid Value" 1000 "Reserved" 65535 "Reserved";
VAL_ 752 V2X_SL6_LightTyp 0 "No warning" 1 "S" 2 "LT" 3 "RT" 4 "TA" 5 "SLT" 6 "SRT" 7 "SLRT" 8 "STA" 9 "Red light allow to turn  left" 10 "Red light allow to turn right" 11 "Reserved" 15 "Reserved";
VAL_ 752 V2X_SL6_LightColor 0 "No warning" 1 "Red light" 2 "Green light" 3 "Yellow light" 4 "Red light flash" 5 "Green light flash" 6 "Yellow light flash" 7 "Reserved" 15 "Reserved";
VAL_ 752 V2X_SL6_LightTim 0 "No warning" 1 "Valid Value" 999 "Valid Value" 1000 "Reserved" 65535 "Reserved";
VAL_ 752 V2X_SL7_LightTyp 0 "No warning" 1 "S" 2 "LT" 3 "RT" 4 "TA" 5 "SLT" 6 "SRT" 7 "SLRT" 8 "STA" 9 "Red light allow to turn  left" 10 "Red light allow to turn right" 11 "Reserved" 15 "Reserved";
VAL_ 752 V2X_SL7_LightColor 0 "No warning" 1 "Red light" 2 "Green light" 3 "Yellow light" 4 "Red light flash" 5 "Green light flash" 6 "Yellow light flash" 7 "Reserved" 15 "Reserved";
VAL_ 752 V2X_SL7_LightTim 0 "No warning" 1 "Valid Value" 999 "Valid Value" 1000 "Reserved" 65535 "Reserved";
VAL_ 752 V2X_SL8_LightTyp 0 "No warning" 1 "S" 2 "LT" 3 "RT" 4 "TA" 5 "SLT" 6 "SRT" 7 "SLRT" 8 "STA" 9 "Red light allow to turn  left" 10 "Red light allow to turn right" 11 "Reserved" 15 "Reserved";
VAL_ 752 V2X_SL8_LightColor 0 "No warning" 1 "Red light" 2 "Green light" 3 "Yellow light" 4 "Red light flash" 5 "Green light flash" 6 "Yellow light flash" 7 "Reserved" 15 "Reserved";
VAL_ 752 V2X_SL8_LightTim 0 "No warning" 1 "Valid Value" 999 "Valid Value" 1000 "Reserved" 65535 "Reserved";
VAL_ 752 V2X_SL_of_Veh 0 "No warning" 1 "1" 2 "2" 3 "3" 4 "4" 5 "5" 6 "6" 7 "7" 8 "8" 9 "Reserved" 15 "Reserved";
VAL_ 593 FuncProtnSts 0 "No fuction demotion" 1 "Fuction demotion";
VAL_ 593 ShiftSysStuInLow 0 "Not in low" 1 "Shift System Stuck in Low";
VAL_ 593 SystemOperMod 0 "Mode Unknown" 1 "System Fault" 2 "Mode 2WD" 3 "Mode 4WD (Lock)" 4 "Mode Active (AWD)" 5 "Reserved" 6 "Mode 4WD Low Range" 7 "Sport Mode (Active)(Reserved)" 8 "Unused" 15 "Unused";
VAL_ 593 CouplingFaultSts 0 "Normal Operating Mode" 1 "Reduced coupling functionality" 2 "Temporary coupling failure" 3 "Permanent coupling failure";
VAL_ 593 CouplingThermWarning 0 "No coupling thermal failsafe" 1 "coupling thermal failsafe";
VAL_ 593 DiagLmpReq 0 "Lamp is not being requested" 1 "Lamp is being requested";
VAL_ 593 ModeShiftTimeout 0 "No timeout" 1 "Timeout";
VAL_ 593 AutoShiftSts 0 "No AutoShift" 1 "HiLockTOAuto Active" 2 "Thermal Lock Active" 3 "AutoShift Error";
VAL_ 593 EstimatedTorque 0 "Valid value" 12000 "Valid value" 12001 "Reserved" 65534 "Reserved" 65535 "Invalid";
VAL_ 833 FLTirePressIndSts 0 "Normal" 1 "Low" 2 "Reserved" 3 "High" 4 "Not available" 5 "Reserved" 7 "Reserved";
VAL_ 833 FRTirePressIndSts 0 "Normal" 1 "Low" 2 "Reserved" 3 "High" 4 "Not available" 5 "Reserved" 7 "Reserved";
VAL_ 833 TirePressSysFailrIndcn 0 "No failure" 1 "Failure" 2 "Reserved" 3 "Reserved";
VAL_ 833 RLTirePressIndSts 0 "Normal" 1 "Low" 2 "Reserved" 3 "High" 4 "Not available" 5 "Reserved" 7 "Reserved";
VAL_ 833 RRTirePressIndSts 0 "Normal" 1 "Low" 2 "Reserved" 3 "High" 4 "Not available" 5 "Reserved" 7 "Reserved";
VAL_ 833 FLTireTempSts 0 "Normal" 1 "High" 2 "Not available" 3 "Reserved";
VAL_ 833 FRTireTempSts 0 "Normal" 1 "High" 2 "Not available" 3 "Reserved";
VAL_ 833 RLTireTempSts 0 "Normal" 1 "High" 2 "Not available" 3 "Reserved";
VAL_ 833 RRTireTempSts 0 "Normal" 1 "High" 2 "Not available" 3 "Reserved";
VAL_ 917 FLTirePress 0 "Valid Value" 254 "Valid Value" 255 "Invalid Value";
VAL_ 917 FLTireTemp 0 "Valid Value" 254 "Valid Value" 255 "Invalid Value";
VAL_ 917 FRTirePress 0 "Valid Value" 254 "Valid Value" 255 "Invalid Value";
VAL_ 917 FRTireTemp 0 "Valid Value" 254 "Valid Value" 255 "Invalid Value";
VAL_ 917 RLTirePress 0 "Valid Value" 254 "Valid Value" 255 "Invalid Value";
VAL_ 917 RLTireTemp 0 "Valid Value" 254 "Valid Value" 255 "Invalid Value";
VAL_ 917 RRTirePress 0 "Valid Value" 254 "Valid Value" 255 "Invalid Value";
VAL_ 917 RRTireTemp 0 "Valid Value" 254 "Valid Value" 255 "Invalid Value";
VAL_ 627 TrailerSts 0 "Trailer off" 1 "Trailer on";
VAL_ 698 WPC_ChrgSts 0 "Standby" 1 "Charging" 2 "Charging Completed" 3 "WPC Fault";
VAL_ 698 WPC_SwtSts 0 "Initial Value" 1 "ON" 2 "OFF" 3 "Reserved";
VAL_ 698 WPC_FaultSts 0 "No Fault" 1 "Foreign Object Detection_FOD" 2 "Over Voltage Protection_OVP" 3 "Low Voltage Protection_LVP" 4 "Over Temperature Protection_OTP" 5 "System Fault" 6 "Reserved" 7 "Reserved";
VAL_ 698 WPC_PhoneReminder 0 "No need to remind" 1 "Remind forgotten phone";
VAL_ 718 DrvSeatMassLvlSetSts 0 "OFF" 1 "Level1_Low" 2 "Level2_Middle" 3 "Level3_High" 4 "Reserved" 7 "Reserved";
VAL_ 718 DrvSeatMassModeSts 0 "No Action" 1 "Wave Mode" 2 "Serpentine Mode" 3 "Catwalk Mode" 4 "Shoulder Mode" 5 "Lumbar Mode" 6 "Soothing Mode" 7 "Butterfly Mode" 8 "Full Body Stretch Mode" 9 "Single Row Mode" 10 "Pulse Mode" 11 "Reserved" 15 "Reserved";
VAL_ 718 PassSeatMassgLvlSetSts 0 "OFF" 1 "Level1_Low" 2 "Level2_Middle" 3 "Level3_High" 4 "Reserved" 7 "Reserved";
VAL_ 718 RLSeatMassgLvlSetSts 0 "OFF" 1 "Level1_Low" 2 "Level2_Middle" 3 "Level3_High" 4 "Reserved" 7 "Reserved";
VAL_ 718 RRSeatMassgLvlSetSts 0 "OFF" 1 "Level1_Low" 2 "Level2_Middle" 3 "Level3_High" 4 "Reserved" 7 "Reserved";
VAL_ 718 PassSeatMassgModeSts 0 "No Action" 1 "Wave Mode" 2 "Serpentine Mode" 3 "Catwalk Mode" 4 "Shoulder Mode" 5 "Lumbar Mode" 6 "Soothing Mode" 7 "Butterfly Mode" 8 "Full Body Stretch Mode" 9 "Single Row Mode" 10 "Pulse Mode" 11 "Reserved" 15 "Reserved";
VAL_ 718 RLSeatMassgModSts 0 "No Action" 1 "Wave Mode" 2 "Serpentine Mode" 3 "Catwalk Mode" 4 "Shoulder Mode" 5 "Lumbar Mode" 6 "Soothing Mode" 7 "Butterfly Mode" 8 "Full Body Stretch Mode" 9 "Single Row Mode" 10 "Pulse Mode" 11 "Reserved" 15 "Reserved";
VAL_ 718 RRSeatMassgModSts 0 "No Action" 1 "Wave Mode" 2 "Serpentine Mode" 3 "Catwalk Mode" 4 "Shoulder Mode" 5 "Lumbar Mode" 6 "Soothing Mode" 7 "Butterfly Mode" 8 "Full Body Stretch Mode" 9 "Single Row Mode" 10 "Pulse Mode" 11 "Reserved" 15 "Reserved";
VAL_ 604 BLEConnSts 0 "Initial value" 1 "Not connection" 2 "Connection" 3 "Reserved";
VAL_ 604 BLESecuritySts 0 "Initial value" 1 "Not in Security certification status" 2 "In security certification status" 3 "Reserved";
VAL_ 473 OTA_UpgrdModErrCode 0 "No_Action" 1 "ota_mode_enter_error" 2 "Reserved" 3 "Reserved";
VAL_ 721 DrvSeatVentnSts 0 "OFF" 1 "Level 1_low" 2 "Level 2_middle" 3 "Level 3_high";
VAL_ 721 PassSeatVentnSts 0 "OFF" 1 "Level 1_low" 2 "Level 2_middle" 3 "Level 3_high";
VAL_ 836 AntiDisIdnResult 0 "Succeed" 1 "Fail" 2 "Invalid" 3 "Reserved";
VAL_ 836 SelfChkSts 0 "Succeed" 1 "Fail" 2 "Invalid" 3 "Reserved";
VAL_ 836 ActvdSts 0 "Active" 1 "Not_active" 2 "Invalid" 3 "Reserved";
VAL_ 498 TransSts 0 "Success" 1 "Abnormal" 2 "Contact_the_Service_provider" 3 "NoCard" 4 "Reserved" 255 "Reserved";
VAL_ 498 EntrAndExitCdn 0 "Reserved" 1 "Enclosed_Manual_Toll_Collection_Entrance" 2 "Enclosed_Manual_Toll_Collection_Exit" 3 "Enclosed_Electronic_Toll_Collection_Entrance" 4 "Enclosed_Electronic_Toll_Collection_Exit" 5 "Open-ended_Manual_Toll_Collection" 6 "Open-ended_Electronic_Toll_Collection" 7 "Reserved" 255 "Reserved";
VAL_ 776 LHiBeamSts 0 "Off" 1 "On";
VAL_ 776 LHiBeamFailSts_HCM 0 "No failure" 1 "failure";
VAL_ 776 LLowBeamSts 0 "Off" 1 "On";
VAL_ 776 LLowBeamFailSts_HCM 0 "No failure" 1 "failure";
VAL_ 772 Checksum_HCM_L2 0 "Valid values" 255 "Valid values";
VAL_ 772 LeftLightShowSts 0 "Animation OFF" 1 "Approach light Animation In Process" 2 "Approach light Animation Successful" 3 "Approach light Animation Failure" 4 "Unlock light Animation In Process" 5 "Unlock light Animation Successful" 6 "Unlock light Animation Failure" 7 "Lock light Animation In Process" 8 "Lock light Animation Successful" 9 "Lock light Animation Failure" 10 "Light show Animation In Process" 11 "Light show Animation Successful" 12 "Light show Animation Failure" 13 "Reserved" 31 "Reserved";
VAL_ 772 FLMusicLightShowSts 0 "OFF" 1 "In_Process" 2 "Successful" 3 "Failure";
VAL_ 772 RollingCounter_HCM_L2 0 "Valid value" 14 "Valid value" 15 "Invalid value";
VAL_ 781 RHiBeamSts 0 "Off" 1 "On";
VAL_ 781 RHiBeamFailSts_HCM 0 "No failure" 1 "failure";
VAL_ 781 RLowBeamSts 0 "Off" 1 "On";
VAL_ 781 RLowBeamFailSts_HCM 0 "No failure" 1 "failure";
VAL_ 816 Checksum_HCM_R2 0 "Valid values" 255 "Valid values";
VAL_ 816 RightLightShowSts 0 "Animation OFF" 1 "Approach light Animation In Process" 2 "Approach light Animation Successful" 3 "Approach light Animation Failure" 4 "Unlock light Animation In Process" 5 "Unlock light Animation Successful" 6 "Unlock light Animation Failure" 7 "Lock light Animation In Process" 8 "Lock light Animation Successful" 9 "Lock light Animation Failure" 10 "Light show Animation In Process" 11 "Light show Animation Successful" 12 "Light show Animation Failure" 13 "Reserved" 31 "Reserved";
VAL_ 816 FRMusicLightShowSts 0 "OFF" 1 "In_Process" 2 "Successful" 3 "Failure";
VAL_ 816 RollingCounter_HCM_R2 0 "Valid value" 14 "Valid value" 15 "Invalid value";
VAL_ 647 CheckSum_HC1 0 "Valid values" 255 "Valid values";
VAL_ 647 ALS_FailSts 0 "No failure" 1 "Failure";
VAL_ 647 RollingCounter_HC1 0 "Valid value" 14 "Valid value" 15 "Invalid value";
VAL_ 818 RFLLightShowSts 0 "Animation_OFF" 1 "Approach_light_In_Process" 2 "Approach_light_Successful" 3 "Approach_light_Failure" 4 "Unlock_light_In_Process" 5 "Unlock_light_Successful" 6 "Unlock_light_Failure" 7 "Lock_light_In_Process" 8 "Lock_light_Successful" 9 "Lock_light_Failure" 10 "Light_show_In_Process" 11 "Light_show_Successful" 12 "Light_show_Failure" 13 "MusicLight_In_Process" 14 "MusicLight_Successful" 15 "MusicLight_Failure";
VAL_ 819 RFRLightShowSts 0 "Animation_OFF" 1 "Approach_light_In_Process" 2 "Approach_light_Successful" 3 "Approach_light_Failure" 4 "Unlock_light_In_Process" 5 "Unlock_light_Successful" 6 "Unlock_light_Failure" 7 "Lock_light_In_Process" 8 "Lock_light_Successful" 9 "Lock_light_Failure" 10 "Light_show_In_Process" 11 "Light_show_Successful" 12 "Light_show_Failure" 13 "MusicLight_In_Process" 14 "MusicLight_Successful" 15 "MusicLight_Failure";
VAL_ 483 BMS_ChrgTimResp 0 "inactive" 1 "active";
VAL_ 850 BMS_IntelEngIdlChrgnSts 0 "Default" 1 "ON" 2 "Off" 3 "Reserved";
VAL_ 850 BMS_BattKeepTempSts 0 "Off" 1 "On";
VAL_ 959 BMS_ChrgDurationTime 0 "Valid value" 1022 "Valid value" 1023 "Invalid";
VAL_ 1009 BMS_SOCLowWarn 0 "Normal" 1 "Need to charge";
VAL_ 942 BMS_SocJumpWarn_RM 0 "No warning" 1 "warning";
VAL_ 942 BMS_PackOverChrgWarn_RM 0 "No warning" 1 "warning";
VAL_ 942 BMS_ChrgSts_RM 0 "Uncharged" 1 "Parking charging" 2 "Driving charging" 3 "Charge end";
VAL_ 942 BMS_IsolationRValue_RM 0 "Valid value" 60000 "Valid value" 60001 "Reseved" 65535 "Reseved";
VAL_ 942 BMS_PackCurr_RM 0 "Valid value" 20000 "Valid value" 20001 "Reserved" 32767 "Reserved";
VAL_ 942 BMS_SocOverWarn_RM 0 "No warning" 1 "warning";
VAL_ 942 BMS_BattOverTempRank_RM 0 "Normal" 1 "Waining";
VAL_ 942 BMS_BattOverVoltRank_RM 0 "Normal" 1 "Waining";
VAL_ 942 BMS_BattSOCLowRank_RM 0 "Normal" 1 "Waining";
VAL_ 942 BMS_VCUIsolateErr_RM 0 "Normal" 1 "Waining";
VAL_ 942 BMS_BattUnderVoltRank_RM 0 "Normal" 1 "Waining";
VAL_ 942 BMS_CellDeltaVoltRank_RM 0 "Normal" 1 "Waining";
VAL_ 942 BMS_CellOverVoltRank_RM 0 "Normal" 1 "Waining";
VAL_ 942 BMS_CellUnderVoltRank_RM 0 "Normal" 1 "Waining";
VAL_ 942 BMS_DeltaTempRank_RM 0 "Normal" 1 "Waining";
VAL_ 942 BMS_PackMismatchWarn_RM 0 "No warning" 1 "warning";
VAL_ 942 BMS_PackVolt_RM 0 "Valid value" 10000 "Valid value" 10001 "Reserved" 16383 "Reserved";
VAL_ 645 BMS_BattHeatRunaway 0 "inactive" 1 "running thermalrunaway" 2 "parking thermalrunaway" 3 "reserved";
VAL_ 645 BMS_DisSOC1 0 "Valid value" 100 "Valid value" 101 "Reserved" 254 "Reserved" 255 "Invalid";
VAL_ 142 EngTrqCrankshaftLvl 0 "Valid values" 4095 "Valid values";
VAL_ 142 EngTrqCrankshaftLvlValid 0 "Invalid value" 1 "Valid value";
VAL_ 279 EngState_PHEV 0 "Stand by" 1 "Ready" 2 "Cranking" 3 "Running" 4 "Stopping" 5 "Finish" 6 "Autostopping" 7 "Reserved";
VAL_ 279 CruiseCtrlSts_PHEV 0 "OFF" 1 "Stand by" 2 "Cruise" 3 "Acceleration" 4 "Deceleration" 5 "Tip up" 6 "Tip dwon" 7 "Resume from above vehicle speed" 8 "Resume from below vehicle speed" 9 "Error" 10 "Reserved" 15 "Reserved";
VAL_ 96 HCU_AccelPedalPosn_Diag 0 "Vaild value" 255 "Vaild value";
VAL_ 96 HCU_AccelPedalPosn_DiagValid 0 "Invaild" 1 "Vaild";
VAL_ 96 HCU_PowertrainSts_0x60 0 "Sleep" 1 "Initialize Mode" 2 "power up" 3 "power down" 4 "Home" 5 "run" 6 "Charging" 7 "Cellphone AC" 8 "Limphome" 9 "Emergency Mode" 10 "V2L" 11 "Prepare Sleep" 12 "ready" 13 "LV Charging" 14 "LT Charging" 15 "IL heating" 16 "Thermal run away" 17 "End of line" 18 "BattTempKeep" 19 "Reserved" 31 "Reserved";
VAL_ 96 HCU_RaceLaunchSts_0x60 0 "Not active" 1 "Active" 2 "Timeout protection" 3 "Reserved" 7 "Reserved";
VAL_ 96 HCU_RaceLaunchAvail_0x60 0 "Race Launch is available" 1 "Race Launch is not available due to ESP is not OFF" 2 "Race Launch is not available due to temporary hybrid system limitations" 3 "Reserved";
VAL_ 96 HCU_AccelPedalPosn 0 "Vaild value" 255 "Vaild value";
VAL_ 96 HCU_AccelPedalPosnValid 0 "Invalid value" 1 "Valid value";
VAL_ 616 HCU_BattLowTempWarn 0 "Normal" 1 "Battery temperature is too low, plug in heating" 2 "Reserved" 3 "Reserved";
VAL_ 616 HCU_BattLowTempHeatSts 0 "Normal" 1 "Battery heating complete" 2 "Reserved" 3 "Reserved";
VAL_ 788 HCU_ACLineDisconnect 0 "Init" 1 "Not connect" 2 "connect" 3 "Reserved";
VAL_ 788 HCU_ChargSts 0 "Default" 1 "Charging(Ã¥Â…Â…Ã§Â”ÂµÃ¤Â¸Â­)" 2 "Delaying" 3 "Charge complete" 4 "Charge stopped" 5 "Charge Initialize" 6 "Charging Heating(Ã¦ÂÂ’Ã¦ÂžÂªÃ¤Â»Â…Ã¥ÂŠÂ Ã§ÂƒÂ­)" 7 "Fault";
VAL_ 788 HCU_IntelBattTempMagSts 0 "Off" 1 "On";
VAL_ 482 HCU_TotalScore 0 "Valid value" 5 "Valid value" 6 "Reserved" 7 "Reserved";
VAL_ 249 HCU_TrqLimMax_Norm 0 "Valid values" 400 "Valid values" 401 "Reserved" 511 "Reserved";
VAL_ 330 HCUImmoAuthRes 0 "Idle" 1 "Passed" 2 "Failed" 3 "Invalid";
VAL_ 330 HCU_EVLmpSts 0 "Not active" 1 "Active";
VAL_ 330 HCU_ECODrvHabit_Indcn 0 "Valid values" 200 "Valid values" 201 "Reversed" 255 "Reversed";
VAL_ 330 HCU_TotDrvReqPower_0x14a 0 "Valid values-Power percentage ValueÃ¯Â¼Âˆ-100-0-100Ã¯Â¼Â‰" 200 "Valid values-Power percentage ValueÃ¯Â¼Âˆ-100-0-100Ã¯Â¼Â‰" 201 "invalid values" 255 "invalid values";
VAL_ 330 HCU_AvailPower_TM 0 "Valid values" 200 "Valid values" 201 "invalid value" 255 "invalid value";
VAL_ 330 HCU_DrvMod 0 "Normal Mode started" 1 "EV Mode started" 2 "Save Mode started" 3 "SPORT Mode started" 4 "AWD Normal Mode started" 5 "Snow Mode started" 6 "Muddy Mode started" 7 "Sand Mode started" 8 "ECO" 9 "Sport plus mode stared" 10 "AUTO Mode started" 11 "Individual" 12 "Reserved" 15 "Reserved";
VAL_ 282 HCU_HybMod 0 "HEV" 1 "EV" 2 "SAVE" 3 "Reserve";
VAL_ 282 HCU_HybFctnMod 0 "OFF" 1 "SAVE" 2 "SPORT+" 3 "Reserve";
VAL_ 448 HCU_ChrgSysLmpSts 0 "OFF" 1 "Green Light ON" 2 "Red Light ON" 3 "Yellow Light with slanting line" 4 "Red Light with slanting line" 5 "Reserved" 7 "Reserved";
VAL_ 448 HCU_ChrgSysErr_1 0 "Not indicate" 1 "Indicate";
VAL_ 448 HCU_ChrgSysErr_2 0 "Not indicate" 1 "Indicate";
VAL_ 448 HCU_ChrgSysErr_3 0 "Not indicate" 1 "Indicate";
VAL_ 448 HCU_ChrgSysErr_4 0 "Not indicate" 1 "Indicate";
VAL_ 448 HCU_ChrgSysErr_5 0 "Not indicate" 1 "Indicate";
VAL_ 448 HCU_ChrgSysErr_6 0 "Not indicate" 1 "Indicate";
VAL_ 448 HCU_ChrgSysErr_7 0 "Not indicate" 1 "Indicate";
VAL_ 448 HCU_ChrgSysErr_8 0 "Not indicate" 1 "Indicate";
VAL_ 448 HCU_DrvModDisp 0 "AutoNormal Mode started" 1 "EV Mode started" 2 "Save Mode started" 3 "SPORT Mode started" 4 "AWD Normal Mode started" 5 "Snow Mode started" 6 "Muddy Mode started" 7 "Sand Mode started" 8 "ECO" 9 "SPORT Plus Mode started" 10 "Reserved" 15 "Reserved";
VAL_ 513 HCU_V2LReminder 0 "Default" 1 "Need_press_start_stop_button_to_use_V2L" 2 "V2L_failed_to_activate_execute" 3 "Reserved";
VAL_ 513 HCU_SOCMngmntSts 0 "OFF" 1 "ON";
VAL_ 513 HCU_ARFSts 0 "OFF" 1 "ON";
VAL_ 513 HCU_ASFCSts 0 "OFF" 1 "ON";
VAL_ 513 HCU_AGSSts 0 "OFF" 1 "ON";
VAL_ 513 PDCU_AvailabilityOfARF 0 "Available" 1 "Prohibited_error" 2 "Prohibited_sensor_missing" 3 "Prohibited_intelligent_function_activated" 4 "Prohibited_ESP_activated" 5 "Deactivated";
VAL_ 513 PDCU_lossenPedalPrompt 0 "No_Prompt" 1 "Prompt";
VAL_ 513 PDCU_EvSave_disl 0 "Not_Active" 1 "Active";
VAL_ 690 ExpertModReq_HUT_HCU 0 "AutoNormal Mode" 1 "EV Mode" 2 "Save Mode" 3 "Reserved";
VAL_ 301 EB_TgtRcprtnTrqSts 0 "Not Initialized" 1 "Normal" 2 "Faulty" 3 "Reserved";
VAL_ 172 P2M_ActTrq 0 "Valid value" 16381 "Valid value" 16382 "Init" 16383 "Invalid";
VAL_ 190 P2M_ActSpd 0 "Valid value" 12286 "Valid value" 12287 "Invalid" 65535 "Invalid";
VAL_ 190 P2M_ActHvDcVolt 0 "Valid value" 4093 "Valid value" 4094 "Init" 4095 "Invalid";
VAL_ 510 T_BOX_ChrgTim_Day 0 "Invalid" 1 "Valid day" 31 "Valid day";
VAL_ 697 DWD_WorkSts 0 "Disable" 1 "Standby" 2 "Active" 3 "Failure";
VAL_ 697 DWD_TextDisp 0 "No Request" 1 "Smark stop system is on" 2 "Speed exceed 10kmh" 3 "Controller pedal undeploy" 4 "Slope exceed 10Ã‚Â°" 5 "Driving mode is snowÃ£Â€ÂmudÃ£Â€Âsand" 6 "Parking System is activated" 7 "Out rearview mirror undeploy" 8 "Doors are open" 9 "Trunk are open" 10 "System is fail" 11 "System is not available" 12 "sys exit" 13 "System is in disturb" 14 "Reserved" 31 "Reserved";
VAL_ 697 DWD_Dis 0 "No object" 1 "Object in zone 1, 0~10cm" 2 "Object in zone 2, 11~20cm" 3 "Object in zone 3, 21~30cm" 4 "Object in zone 4, 31~40cm" 5 "Object in zone 5, 41~50cm" 6 "Object in zone 6, 51~60cm" 7 "Object in zone 7, 61~70cm" 8 "Object in zone 8, 71~80cm" 9 "Object in zone 9, 81~90cm" 10 "Object in zone 10, 91~100cm" 11 "Object in zone 11, 101~110cm" 12 "Object in zone 12, 111~120cm" 13 "Object in zone 13, 121~130cm" 14 "Object in zone 14, 131~140cm" 15 "Object in zone 15, 141~150cm";
VAL_ 697 DWD_SoundIndcn 0 "No warning" 1 "Long beep" 2 "3Hz" 3 "1.5Hz";
VAL_ 697 RSnsrFailSts 0 "Sensor normal" 1 "Sensor fault";
VAL_ 697 LSnsrFailSts 0 "Sensor normal" 1 "Sensor fault";
VAL_ 790 OBC_ModSts 0 "Discharging" 1 "Init" 2 "Standby" 3 "Heating" 4 "Charging Normal" 5 "Reserved" 7 "Reserved" 8 "Fault" 9 "Reduced Power" 10 "Reserved" 11 "Sleep (Shutdown)" 12 "OFF" 13 "Reserved" 15 "Reserved";
VAL_ 791 OBC_ConnectSts 0 "Not connected" 1 "Connected" 2 "Error" 3 "Discharge connected";
VAL_ 708 BMS_BattSOCLimResp 0 "100%" 1 "50%" 2 "60%" 3 "70%" 4 "80%" 5 "90%" 6 "Invalid" 7 "reserved";
VAL_ 486 MultiColorNr1 0 "No command" 1 "Valid" 64 "Valid" 65 "Reserved" 127 "Reserved";
VAL_ 486 MultiColorNr2 0 "No command" 1 "Valid" 64 "Valid" 65 "Reserved" 127 "Reserved";
VAL_ 486 MultiColorNr3 0 "No command" 1 "Valid" 64 "Valid" 65 "Reserved" 127 "Reserved";
VAL_ 486 MultiColorNr4 0 "No command" 1 "Valid" 64 "Valid" 65 "Reserved" 127 "Reserved";
VAL_ 486 MultiColorNr5 0 "No command" 1 "Valid" 64 "Valid" 65 "Reserved" 127 "Reserved";
VAL_ 486 MultiColorNr6 0 "No command" 1 "Valid" 64 "Valid" 65 "Reserved" 127 "Reserved";
VAL_ 486 MultiColorNr7 0 "No command" 1 "Valid" 64 "Valid" 65 "Reserved" 127 "Reserved";
VAL_ 486 MultiColorNr8 0 "No command" 1 "Valid" 64 "Valid" 65 "Reserved" 127 "Reserved";
VAL_ 492 MultiColorNr9 0 "No command" 1 "Valid" 64 "Valid" 65 "Reserved" 127 "Reserved";
VAL_ 492 MultiColorNr10 0 "No command" 1 "Valid" 64 "Valid" 65 "Reserved" 127 "Reserved";
VAL_ 492 MultiColorNr11 0 "No command" 1 "Valid" 64 "Valid" 65 "Reserved" 127 "Reserved";
VAL_ 492 MultiColorNr12 0 "No command" 1 "Valid" 64 "Valid" 65 "Reserved" 127 "Reserved";
VAL_ 492 MultiColorNr13 0 "No command" 1 "Valid" 64 "Valid" 65 "Reserved" 127 "Reserved";
VAL_ 492 MultiColorNr14 0 "No command" 1 "Valid" 64 "Valid" 65 "Reserved" 127 "Reserved";
VAL_ 492 MultiColorNr15 0 "No command" 1 "Valid" 64 "Valid" 65 "Reserved" 127 "Reserved";
VAL_ 492 MultiColorNr16 0 "No command" 1 "Valid" 64 "Valid" 65 "Reserved" 127 "Reserved";
VAL_ 130 NetEngTrq 0 "Valid values" 65534 "Valid values" 65535 "Invalid";
VAL_ 130 DrvEngTrqReq 0 "Valid values" 65535 "Valid values";
VAL_ 258 AccelPedlPosnDiagc 0 "Valid values" 255 "Valid values";
VAL_ 132 HCU_RaceLaunchAvail_0x84 0 "Race Launch is available" 1 "Race Launch is not available due to ESP is not OFF" 2 "Race Launch is not available due to temporary hybrid system limitations" 3 "Reserved";
VAL_ 132 HCU_RaceLaunchSts_0x84 0 "Inactive" 1 "Active" 2 "Timeout protection" 3 "Reserved" 7 "Reserved";
VAL_ 724 DPF_Warning 0 "No self-cleaning" 1 "Please place self-cleaning" 2 "Please start the car and keep idle" 3 "In the clean" 4 "Clean finishi,thank you for waiting" 5 "Reserved" 6 "Invalid" 7 "Invalid";
VAL_ 724 WIFSensorFailSts 0 "No failure" 1 "Failure" 2 "Reserved" 3 "Not available";
VAL_ 724 GlowPlugLmpCmd 0 "Off" 1 "On" 2 "Reserved" 3 "Not available";
VAL_ 724 UreaLampCmd 0 "Off" 1 "On" 2 "Flsah" 3 "Reserved";
VAL_ 724 Urea_Level 0 "0%" 1 "5%" 2 "10%" 3 "15%" 4 "20%" 5 "25%" 6 "30%" 7 "35%" 8 "40%" 9 "45%" 10 "50%" 11 "55%" 12 "60%" 13 "65%" 14 "70%" 15 "75%" 16 "80%" 17 "85%" 18 "90%" 19 "95%" 20 "100%" 21 "Reserved";
VAL_ 724 UreaRemainDist 0 "Valid value" 4095 "Valid value";
VAL_ 724 SCRSysWarnDisplay 0 "No warnÃ¤Â¸ÂÃ¦ÂÂÃ§Â¤Âº(Ã©Â»Â˜Ã¨Â®Â¤Ã¥Â€Â¼)" 1 "Urea level lowÃ¥Â°Â¿Ã§Â´Â Ã¦Â¶Â²Ã¤Â½ÂÃ¤Â½ÂŽ,Ã¨Â¯Â·Ã¥ÂŠÂ Ã¦Â³Â¨" 2 "Urea level tool lowÃ¥Â°Â¿Ã§Â´Â Ã¦Â¶Â²Ã¤Â½ÂÃ¦ÂžÂÃ¤Â½ÂŽ,Ã¨Â¯Â·Ã¥ÂŠÂ Ã¦Â³Â¨" 3 "Empty tank,next start prohibitÃ¥Â°Â¿Ã§Â´Â Ã§Â½ÂÃ§Â©Âº,Ã§Â¦ÂÃ¦Â­Â¢Ã¤Â¸Â‹Ã¦Â¬Â¡Ã¥ÂÂ¯Ã¥ÂŠÂ¨" 4 "Incorrect ureaÃ¥Â°Â¿Ã§Â´Â Ã¤Â¸ÂÃ¥ÂÂˆÃ¦Â Â¼,Ã¨Â¯Â·Ã¦Â£Â€Ã¦ÂŸÂ¥" 5 "Incorrect urea over limit dist Ã¥Â°Â¿Ã§Â´Â Ã¤Â¸ÂÃ¥ÂÂˆÃ¦Â Â¼Ã¨Â¡ÂŒÃ©Â©Â¶Ã¨Â¶Â…Ã¨Â¿Â‡50km" 6 "Urea fill intercept,please refillÃ¥Â°Â¿Ã§Â´Â Ã¥ÂŠÂ Ã¦Â³Â¨Ã¤Â¸Â­Ã¦Â­Â¢,Ã¨Â¯Â·Ã©Â‡ÂÃ¦Â–Â°Ã¥ÂŠÂ Ã¦Â³Â¨" 7 "Urea fill intercept over limit distÃ¥Â°Â¿Ã§Â´Â Ã¥ÂŠÂ Ã¦Â³Â¨Ã¤Â¸Â­Ã¦Â­Â¢Ã¨Â¡ÂŒÃ©Â©Â¶Ã¨Â¶Â…Ã¨Â¿Â‡50km" 8 "Engine start prohibitÃ¥Â°Â¿Ã§Â´Â Ã§Â³Â»Ã§Â»ÂŸÃ§Â¦ÂÃ¦Â­Â¢Ã¥ÂÂ‘Ã¥ÂŠÂ¨Ã¦ÂœÂºÃ¥ÂÂ¯Ã¥ÂŠÂ¨" 9 "SCR system fault,please checkÃ¥Â°Â¿Ã§Â´Â Ã§Â³Â»Ã§Â»ÂŸÃ¦Â•Â…Ã©ÂšÂœ,Ã¨Â¯Â·Ã¥Â…Â¥Ã§Â«Â™Ã¦Â£Â€Ã¦ÂŸÂ¥" 10 "SCR system fault over limit DistÃ¥Â°Â¿Ã§Â´Â Ã§Â³Â»Ã§Â»ÂŸÃ¦Â•Â…Ã©ÂšÂœÃ¨Â¡ÂŒÃ©Â©Â¶Ã¨Â¶Â…Ã¨Â¿Â‡50km" 11 "Driving dist over limition with fault, next start prohibitÃ¥Â°Â¿Ã§Â´Â Ã§Â³Â»Ã§Â»ÂŸÃ¦Â•Â…Ã©ÂšÂœÃ§Â¦ÂÃ¦Â­Â¢Ã¤Â¸Â‹Ã¦Â¬Â¡Ã¥ÂÂ¯Ã¥ÂŠÂ¨" 12 "Reserved" 15 "Reserved";
VAL_ 724 WIFFullLmpCmd 0 "Off" 1 "On" 2 "Reserved" 3 "Not available";
VAL_ 724 DPF_Activation 0 "No action" 1 "Active" 2 "Reserved" 3 "Invalid";
VAL_ 848 EngOilLvlWrn 0 "No alarm" 1 "Oillevelmin alarm" 2 "Overfill alarm" 3 "Error";
VAL_ 848 EngOilLowPresWrn 0 "No alarm" 1 "Alarm";
VAL_ 848 EngOilPres 0 "Valid values" 120 "Valid values" 121 "Reserve" 126 "Reserve" 127 "Invalid value";
VAL_ 848 EngOilTemp 0 "Valid values" 200 "Valid values" 201 "Reserve" 254 "Reserve" 255 "Invalid value";
VAL_ 335 BMS_BattSOC_P0 0 "Valid value" 1000 "Valid value" 1001 "Reserved" 1022 "Reserved" 1023 "Invalid";
VAL_ 158 HCU_PowertrainSts_0x9e 0 "Sleep" 1 "Initialize Mode" 2 "power up" 3 "power down" 4 "Cellphone APP" 5 "run" 6 "Charging" 7 "Error Mode" 8 "Limphome" 9 "Emergency Mode" 10 "Service Mode" 11 "Prepare Sleep" 12 "Ready" 13 "Reserved" 15 "Reserved";
VAL_ 158 HCU_TotDrvReqPower_0x9e 0 "Valid Value" 200 "Valid Value" 201 "invalid" 255 "invalid";
VAL_ 158 TgtRcprtnTrqSts 0 "Not Initialized" 1 "Normal" 2 "Faulty" 3 "Reserved";
SIG_GROUP_ 639 IP2 1 : CheckSum_IP2 IP_VehTotDistance IP_FuelLvlInfo IP_ACCErr IP_VehTotDistanceValid IP_FuelLvlLowLmpSts IP_BattChrgLmpSts IP_EngOilPressLowLmpSts IP_ABMWarnLmpFailrSts IP_VehSpdUnit IP_Err IP_DrvSeatBeltWarnLmpFailSts IP_PassSeatBeltWarnLmpFailSts IP_VINcompr RollingCounter_IP2;
SIG_GROUP_ 772 HCM_L2 1 : Checksum_HCM_L2 LeftLightShowSts FLMusicLightShowSts RollingCounter_HCM_L2;
SIG_GROUP_ 816 HCM_R2 1 : Checksum_HCM_R2 RightLightShowSts FRMusicLightShowSts RollingCounter_HCM_R2;
SIG_GROUP_ 647 ALS1 1 : CheckSum_HC1 ALS_FailSts RollingCounter_HC1;
